VERSION ""

NS_ :

BS_:

BU_: VCU_LE CHUD_LE VKM_LE RCRM_LE VPM_LE EDI_LE V2V_LE TCP_LE CSM_LE UHP_Low_LE TouchPad_LE RSE_LE RSC_LE RSA_LE PDIM_LE OTIM_LE ICS_LE LVMPC_LE LVMNav_LE DVB_T_LE ONSTAR_LE HUD_LE IPC_LE RadioHead_LE CHM_LE Dummy_LE CGM_LE AMP_LE

BO_ 2156298240 High_Volt_Batt_Time_Pwr_Chrg_LE: 8 CGM_LE
 SG_ HTRActvIndOn : 59|1@0+ (1,0) [0|1] ""  VCU_LE,IPC_LE
 SG_ HVBSTLPC_MntOfHr : 53|6@0+ (1,0) [0|63] "Minute"  TCP_LE,ONSTAR_LE,CSM_LE,RadioHead_LE,VCU_LE,IPC_LE
 SG_ HVBSTLPC_HrOfDy : 42|5@0+ (1,0) [0|31] "Hour"  TCP_LE,ONSTAR_LE,CSM_LE,RadioHead_LE,VCU_LE,IPC_LE
 SG_ HVBSTLPC_DyOfWk : 45|3@0+ (1,0) [0|7] ""  TCP_LE,ONSTAR_LE,CSM_LE,RadioHead_LE,VCU_LE,IPC_LE
 SG_ HVBSTHPC_MntOfHr : 35|6@0+ (1,0) [0|63] "Minute"  TCP_LE,ONSTAR_LE,CSM_LE,RadioHead_LE,VCU_LE,IPC_LE
 SG_ HVBSTHPC_HrOfDy : 24|5@0+ (1,0) [0|31] "Hour"  TCP_LE,ONSTAR_LE,CSM_LE,RadioHead_LE,VCU_LE,IPC_LE
 SG_ HVBSTHPC_DyOfWk : 27|3@0+ (1,0) [0|7] ""  TCP_LE,ONSTAR_LE,CSM_LE,RadioHead_LE,VCU_LE,IPC_LE
 SG_ HVBCTLPC_MntOfHr : 17|6@0+ (1,0) [0|63] "Minute"  CSM_LE,RadioHead_LE,VCU_LE,IPC_LE
 SG_ HVBCTLPC_HrOfDy : 22|5@0+ (1,0) [0|31] "Hour"  CSM_LE,RadioHead_LE,VCU_LE,IPC_LE
 SG_ HVBCTLPC_DyOfWk : 9|3@0+ (1,0) [0|7] ""  CSM_LE,RadioHead_LE,VCU_LE,IPC_LE
 SG_ HVBCTHPC_MntOfHr : 15|6@0+ (1,0) [0|63] "Minute"  CSM_LE,RadioHead_LE,VCU_LE,IPC_LE
 SG_ HVBCTHPC_HrOfDy : 4|5@0+ (1,0) [0|31] "Hour"  CSM_LE,RadioHead_LE,VCU_LE,IPC_LE
 SG_ HVBCTHPC_DyOfWk : 7|3@0+ (1,0) [0|7] ""  CSM_LE,RadioHead_LE,VCU_LE,IPC_LE
 SG_ InvldHMIEtrIO : 61|1@0+ (1,0) [0|1] ""  VCU_LE,CSM_LE,RadioHead_LE
 SG_ InsfcntTmTFlChrgIO : 60|1@0+ (1,0) [0|1] ""  VCU_LE,CSM_LE,RadioHead_LE
 SG_ HVBatChrgCrdAlrtReq : 63|2@0+ (1,0) [0|3] ""  CSM_LE,VCU_LE,RadioHead_LE
 SG_ HVCSDTES_NPDTIO : 56|1@0+ (1,0) [0|1] ""  VCU_LE,CSM_LE,RadioHead_LE
 SG_ HVCSDTES_LoPwrCIO : 58|1@0+ (1,0) [0|1] ""  VCU_LE,CSM_LE,RadioHead_LE
 SG_ HVCSDTES_HiPwrCIO : 57|1@0+ (1,0) [0|1] ""  VCU_LE,CSM_LE,RadioHead_LE

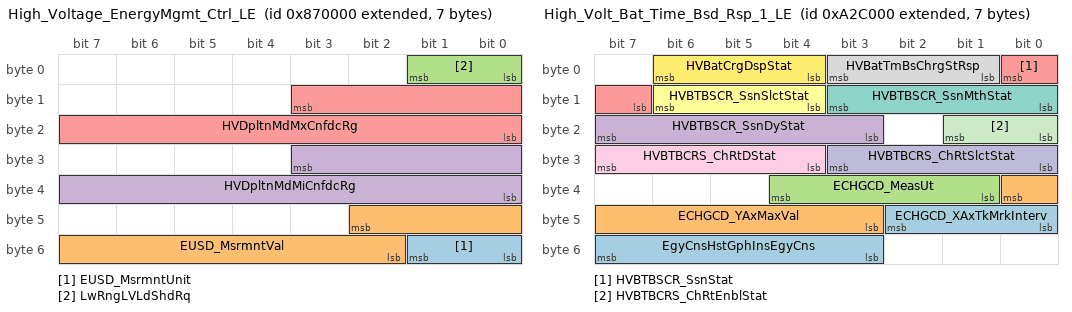
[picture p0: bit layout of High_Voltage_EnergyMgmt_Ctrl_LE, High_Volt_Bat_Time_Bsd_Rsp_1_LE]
BO_ 2156331008 High_Voltage_EnergyMgmt_Ctrl_LE: 7 CGM_LE
 SG_ EUSD_MsrmntUnit : 49|2@0+ (1,0) [0|3] ""  VCU_LE,CSM_LE,RadioHead_LE
 SG_ EUSD_MsrmntVal : 42|9@0+ (1,0) [0|511] ""  VCU_LE,CSM_LE,RadioHead_LE
 SG_ LwRngLVLdShdRq : 1|2@0+ (1,0) [0|3] ""  CSM_LE,VCU_LE,RadioHead_LE
 SG_ HVDpltnMdMiCnfdcRg : 27|12@0+ (0.1,0) [0|409.5] "km"  CSM_LE,RadioHead_LE,VCU_LE,IPC_LE
 SG_ HVDpltnMdMxCnfdcRg : 11|12@0+ (0.1,0) [0|409.5] "km"  CSM_LE,RadioHead_LE,VCU_LE,IPC_LE

BO_ 2158116864 High_Volt_Bat_Time_Bsd_Rsp_LE: 8 CGM_LE
 SG_ HVBatOvrhtdRdIO : 39|1@0+ (1,0) [0|1] ""  VCU_LE,IPC_LE
 SG_ SrvcHghVltBatIndReq : 37|2@0+ (1,0) [0|3] ""  VCU_LE,IPC_LE
 SG_ ChrgStPkInScnActIO : 35|1@0+ (1,0) [0|1] ""  VCU_LE,IPC_LE
 SG_ HVBTBRCR_RtCHSlctTblRwStat : 58|3@0+ (1,0) [0|7] "rows"  CSM_LE,VCU_LE,RadioHead_LE
 SG_ HVBTBRCR_RtChSlctStat : 42|3@0+ (1,0) [0|7] ""  CSM_LE,VCU_LE,RadioHead_LE
 SG_ HVBTBRCR_RtChSlRtStat : 62|4@0+ (1,0) [0|15] ""  CSM_LE,VCU_LE,RadioHead_LE
 SG_ HVBTBRCR_RtChSsnStat : 34|2@0+ (1,0) [0|3] ""  CSM_LE,VCU_LE,RadioHead_LE
 SG_ HVBTBRCR_RtChMHRsp : 32|6@0+ (1,0) [0|63] "min"  CSM_LE,VCU_LE,RadioHead_LE
 SG_ HVBTBRCR_RtChHRsp : 55|5@0+ (1,0) [0|31] "hr"  CSM_LE,VCU_LE,RadioHead_LE
 SG_ HVBTBRCR_RtChDStat : 50|4@0+ (1,0) [0|15] ""  CSM_LE,VCU_LE,RadioHead_LE
 SG_ HVBTBDCRS_DlChSlctStat : 19|4@0+ (1,0) [0|15] ""  CSM_LE,VCU_LE,RadioHead_LE
 SG_ HVBTBDCRS_DlChSsnStat : 31|2@0+ (1,0) [0|3] ""  CSM_LE,VCU_LE,RadioHead_LE
 SG_ HVBTBDCRS_DlChMHRsp : 29|6@0+ (1,0) [0|63] "min"  CSM_LE,VCU_LE,RadioHead_LE
 SG_ HVBTBDCRS_DlChHRsp : 12|5@0+ (1,0) [0|31] "hr"  CSM_LE,VCU_LE,RadioHead_LE
 SG_ HVBTBDCRS_DlChDStat : 23|4@0+ (1,0) [0|15] ""  CSM_LE,VCU_LE,RadioHead_LE
 SG_ HVBatStrtTmDspFrmt : 15|3@0+ (1,0) [0|7] ""  CSM_LE,VCU_LE,RadioHead_LE
 SG_ OBHVBCMinsRmng : 5|6@0+ (1,0) [0|63] ""  CSM_LE,RadioHead_LE,VCU_LE,IPC_LE
 SG_ OBHVBCCompTmDispFrmt : 7|2@0+ (1,0) [0|3] ""  CSM_LE,RadioHead_LE,VCU_LE,IPC_LE

BO_ 2158149632 High_Volt_Bat_Time_Bsd_Rsp_1_LE: 7 CGM_LE
 SG_ ECHGCD_XAxTkMrkInterv : 42|3@0+ (1,0) [0|7] ""  VCU_LE,CSM_LE,RadioHead_LE
 SG_ ECHGCD_YAxMaxVal : 32|6@0+ (4,0) [0|252] ""  VCU_LE,CSM_LE,RadioHead_LE
 SG_ ECHGCD_MeasUt : 36|4@0+ (1,0) [0|15] ""  VCU_LE,CSM_LE,RadioHead_LE
 SG_ HVBTBSCR_SsnDyStat : 23|5@0+ (1,0) [0|31] "day"  VCU_LE,CSM_LE,RadioHead_LE
 SG_ HVBTBSCR_SsnStat : 0|2@0+ (1,0) [0|3] ""  VCU_LE,CSM_LE,RadioHead_LE
 SG_ HVBTBSCR_SsnSlctStat : 14|3@0+ (1,0) [0|7] ""  VCU_LE,CSM_LE,RadioHead_LE
 SG_ HVBTBSCR_SsnMthStat : 11|4@0+ (1,0) [0|15] ""  VCU_LE,CSM_LE,RadioHead_LE
 SG_ HVBatTmBsChrgStRsp : 3|3@0+ (1,0) [0|7] ""  VCU_LE,CSM_LE,RadioHead_LE
 SG_ HVBTBCRS_ChRtDStat : 31|4@0+ (1,0) [0|15] ""  VCU_LE,CSM_LE,RadioHead_LE
 SG_ HVBTBCRS_ChRtSlctStat : 27|4@0+ (1,0) [0|15] ""  VCU_LE,CSM_LE,RadioHead_LE
 SG_ HVBTBCRS_ChRtEnblStat : 17|2@0+ (1,0) [0|3] ""  VCU_LE,CSM_LE,RadioHead_LE
 SG_ HVBatCrgDspStat : 6|3@0+ (1,0) [0|7] ""  CSM_LE,VCU_LE,RadioHead_LE
 SG_ EgyCnsHstGphInsEgyCns : 55|5@0+ (1,0) [0|31] ""  VCU_LE,CSM_LE,RadioHead_LE

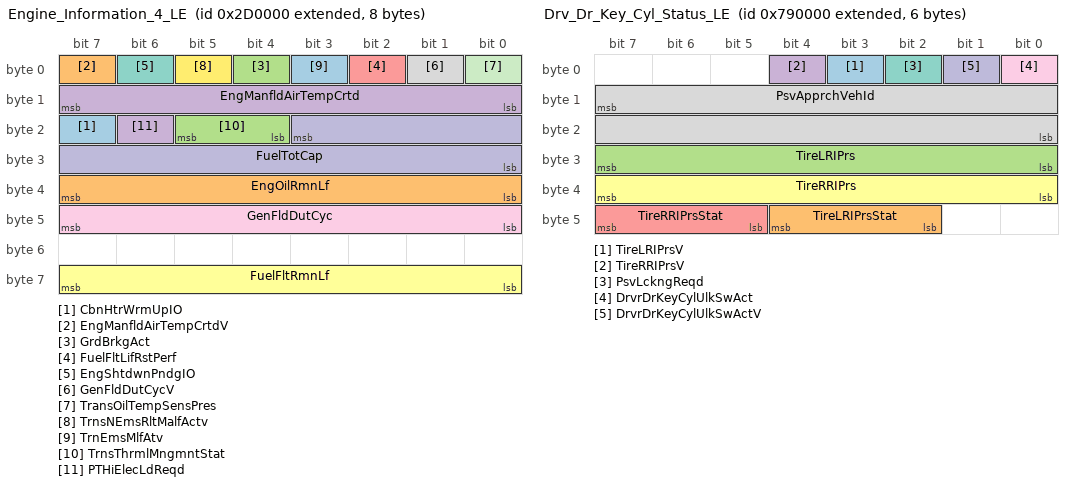
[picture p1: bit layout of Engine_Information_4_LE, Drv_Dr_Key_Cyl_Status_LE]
BO_ 2150432768 Engine_Information_4_LE: 8 CGM_LE
 SG_ CbnHtrWrmUpIO : 23|1@0+ (1,0) [0|1] ""  VCU_LE,IPC_LE
 SG_ EngManfldAirTempCrtdV : 7|1@0+ (1,0) [0|1] ""  Dummy_LE
 SG_ GrdBrkgAct : 4|1@0+ (1,0) [0|1] ""  CSM_LE,RadioHead_LE,VCU_LE,IPC_LE
 SG_ EngManfldAirTempCrtd : 15|8@0+ (1,-40) [-40|215] "deg C"  Dummy_LE
 SG_ FuelFltLifRstPerf : 2|1@0+ (1,0) [0|1] ""  CSM_LE,RadioHead_LE,VCU_LE,IPC_LE
 SG_ FuelFltRmnLf : 63|8@0+ (0.392157,0) [0|100.000035] "%"  CSM_LE,RadioHead_LE,VCU_LE,IPC_LE
 SG_ EngShtdwnPndgIO : 6|1@0+ (1,0) [0|1] ""  CSM_LE,RadioHead_LE,VCU_LE,IPC_LE
 SG_ GenFldDutCycV : 1|1@0+ (1,0) [0|1] ""  CSM_LE,VCU_LE,RadioHead_LE
 SG_ GenFldDutCyc : 47|8@0+ (0.392157,0) [0|100.000035] "%"  CSM_LE,VCU_LE,RadioHead_LE
 SG_ FuelTotCap : 19|12@0+ (0.125,0) [0|511.875] "liters"  TCP_LE,ONSTAR_LE,CSM_LE,RadioHead_LE,VCU_LE,IPC_LE
 SG_ TransOilTempSensPres : 0|1@0+ (1,0) [0|1] ""  CSM_LE,RadioHead_LE,VCU_LE,IPC_LE
 SG_ TrnsNEmsRltMalfActv : 5|1@0+ (1,0) [0|1] ""  CSM_LE,RadioHead_LE,VCU_LE,IPC_LE
 SG_ TrnEmsMlfAtv : 3|1@0+ (1,0) [0|1] ""  CSM_LE,RadioHead_LE,VCU_LE,IPC_LE
 SG_ EngOilRmnLf : 39|8@0+ (0.392157,0) [0|100.000035] "%"  CSM_LE,TCP_LE,ONSTAR_LE,RadioHead_LE,VCU_LE,IPC_LE
 SG_ TrnsThrmlMngmntStat : 21|2@0+ (1,0) [0|3] ""  CSM_LE,TCP_LE,ONSTAR_LE,RadioHead_LE,VCU_LE,IPC_LE
 SG_ PTHiElecLdReqd : 22|1@0+ (1,0) [0|1] ""  CSM_LE,RadioHead_LE,VCU_LE,IPC_LE

BO_ 2155413504 Drv_Dr_Key_Cyl_Status_LE: 6 CGM_LE
 SG_ TireLRIPrsV : 3|1@0+ (1,0) [0|1] ""  V2V_LE,TCP_LE,ONSTAR_LE,VCU_LE,IPC_LE
 SG_ TireLRIPrsStat : 44|3@0+ (1,0) [0|7] ""  TCP_LE,ONSTAR_LE,VCU_LE,IPC_LE
 SG_ TireLRIPrs : 31|8@0+ (4,0) [0|1020] "kPaG"  V2V_LE,TCP_LE,ONSTAR_LE,VCU_LE,IPC_LE
 SG_ TireRRIPrsV : 4|1@0+ (1,0) [0|1] ""  V2V_LE,TCP_LE,ONSTAR_LE,VCU_LE,IPC_LE
 SG_ TireRRIPrsStat : 47|3@0+ (1,0) [0|7] ""  TCP_LE,ONSTAR_LE,VCU_LE,IPC_LE
 SG_ TireRRIPrs : 39|8@0+ (4,0) [0|1020] "kPaG"  V2V_LE,TCP_LE,ONSTAR_LE,VCU_LE,IPC_LE
 SG_ PsvLckngReqd : 2|1@0+ (1,0) [0|1] ""  Dummy_LE
 SG_ PsvApprchVehId : 15|16@0+ (1,0) [0|65535] ""  Dummy_LE
 SG_ DrvrDrKeyCylUlkSwAct : 0|1@0+ (1,0) [0|1] ""  CSM_LE,VCU_LE,RadioHead_LE
 SG_ DrvrDrKeyCylUlkSwActV : 1|1@0+ (1,0) [0|1] ""  CSM_LE,VCU_LE,RadioHead_LE

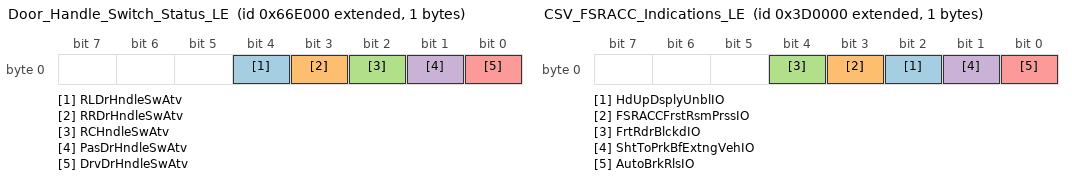
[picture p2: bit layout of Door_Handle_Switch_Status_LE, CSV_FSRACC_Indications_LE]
BO_ 2154225664 Door_Handle_Switch_Status_LE: 1 CGM_LE
 SG_ RLDrHndleSwAtv : 4|1@0+ (1,0) [0|1] ""  VKM_LE,CSM_LE,VCU_LE,RadioHead_LE
 SG_ RRDrHndleSwAtv : 3|1@0+ (1,0) [0|1] ""  VKM_LE,CSM_LE,VCU_LE,RadioHead_LE
 SG_ RCHndleSwAtv : 2|1@0+ (1,0) [0|1] ""  VKM_LE,CSM_LE,VCU_LE,RadioHead_LE
 SG_ PasDrHndleSwAtv : 1|1@0+ (1,0) [0|1] ""  VKM_LE,CSM_LE,VCU_LE,RadioHead_LE
 SG_ DrvDrHndleSwAtv : 0|1@0+ (1,0) [0|1] ""  VKM_LE,CSM_LE,VCU_LE,RadioHead_LE

BO_ 2151481344 CSV_FSRACC_Indications_LE: 1 CGM_LE
 SG_ HdUpDsplyUnblIO : 2|1@0+ (1,0) [0|1] ""  VCU_LE,IPC_LE
 SG_ FSRACCFrstRsmPrssIO : 3|1@0+ (1,0) [0|1] ""  VCU_LE,IPC_LE
 SG_ FrtRdrBlckdIO : 4|1@0+ (1,0) [0|1] ""  CSM_LE,RadioHead_LE,VCU_LE,IPC_LE
 SG_ ShtToPrkBfExtngVehIO : 1|1@0+ (1,0) [0|1] ""  VCU_LE,IPC_LE
 SG_ AutoBrkRlsIO : 0|1@0+ (1,0) [0|1] ""  VCU_LE,IPC_LE

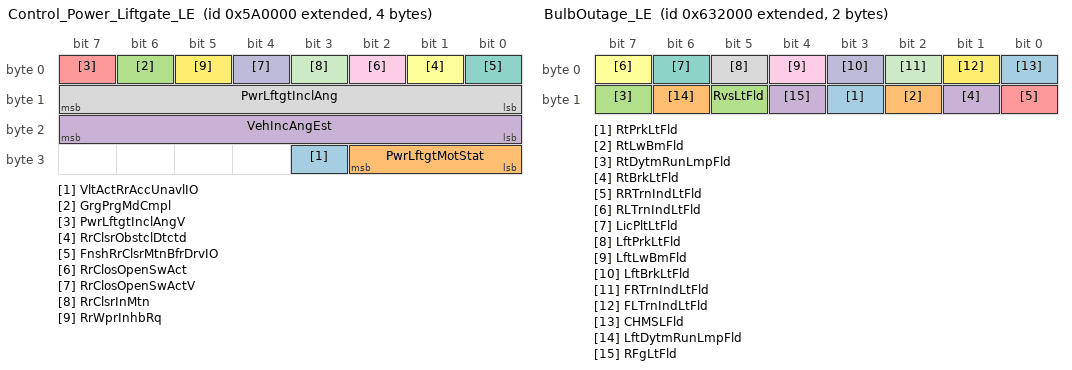
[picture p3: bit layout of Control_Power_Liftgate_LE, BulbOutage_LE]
BO_ 2153381888 Control_Power_Liftgate_LE: 4 CGM_LE
 SG_ VltActRrAccUnavlIO : 27|1@0+ (1,0) [0|1] ""  VCU_LE,IPC_LE
 SG_ PwrLftgtMotStat : 26|3@0+ (1,0) [0|7] ""  CSM_LE,IPC_LE,VCU_LE,RadioHead_LE
 SG_ GrgPrgMdCmpl : 6|1@0+ (1,0) [0|1] ""  CSM_LE,VCU_LE,RadioHead_LE
 SG_ VehIncAngEst : 23|8@0+ (1,0) [0|255] "deg"  CSM_LE,VCU_LE,RadioHead_LE
 SG_ PwrLftgtInclAngV : 7|1@0+ (1,0) [0|1] ""  CSM_LE,VCU_LE,RadioHead_LE
 SG_ RrClsrObstclDtctd : 1|1@0+ (1,0) [0|1] ""  CSM_LE,VCU_LE,RadioHead_LE
 SG_ FnshRrClsrMtnBfrDrvIO : 0|1@0+ (1,0) [0|1] ""  CSM_LE,RadioHead_LE,VCU_LE,IPC_LE
 SG_ PwrLftgtInclAng : 15|8@0+ (1,0) [0|255] ""  CSM_LE,VCU_LE,RadioHead_LE
 SG_ RrClosOpenSwAct : 2|1@0+ (1,0) [0|1] ""  VKM_LE,CSM_LE,RadioHead_LE,VCU_LE,IPC_LE
 SG_ RrClosOpenSwActV : 4|1@0+ (1,0) [0|1] ""  CSM_LE,RadioHead_LE,VCU_LE,IPC_LE
 SG_ RrClsrInMtn : 3|1@0+ (1,0) [0|1] ""  CSM_LE,VCU_LE,RadioHead_LE
 SG_ RrWprInhbRq : 5|1@0+ (1,0) [0|1] ""  CSM_LE,VCU_LE,RadioHead_LE

BO_ 2153979904 BulbOutage_LE: 2 CGM_LE
 SG_ RtPrkLtFld : 11|1@0+ (1,0) [0|1] ""  CSM_LE,TCP_LE,ONSTAR_LE,RadioHead_LE,VCU_LE,IPC_LE
 SG_ RtLwBmFld : 10|1@0+ (1,0) [0|1] ""  CSM_LE,TCP_LE,ONSTAR_LE,RadioHead_LE,VCU_LE,IPC_LE
 SG_ RtDytmRunLmpFld : 15|1@0+ (1,0) [0|1] ""  CSM_LE,RadioHead_LE,VCU_LE,IPC_LE
 SG_ RtBrkLtFld : 9|1@0+ (1,0) [0|1] ""  CSM_LE,TCP_LE,ONSTAR_LE,RadioHead_LE,VCU_LE,IPC_LE
 SG_ RRTrnIndLtFld : 8|1@0+ (1,0) [0|1] ""  CSM_LE,TCP_LE,ONSTAR_LE,RadioHead_LE,VCU_LE,IPC_LE
 SG_ RLTrnIndLtFld : 7|1@0+ (1,0) [0|1] ""  CSM_LE,TCP_LE,ONSTAR_LE,RadioHead_LE,VCU_LE,IPC_LE
 SG_ LicPltLtFld : 6|1@0+ (1,0) [0|1] ""  CSM_LE,TCP_LE,ONSTAR_LE,RadioHead_LE,VCU_LE,IPC_LE
 SG_ LftPrkLtFld : 5|1@0+ (1,0) [0|1] ""  CSM_LE,TCP_LE,ONSTAR_LE,RadioHead_LE,VCU_LE,IPC_LE
 SG_ LftLwBmFld : 4|1@0+ (1,0) [0|1] ""  CSM_LE,TCP_LE,ONSTAR_LE,RadioHead_LE,VCU_LE,IPC_LE
 SG_ LftBrkLtFld : 3|1@0+ (1,0) [0|1] ""  CSM_LE,TCP_LE,ONSTAR_LE,RadioHead_LE,VCU_LE,IPC_LE
 SG_ FRTrnIndLtFld : 2|1@0+ (1,0) [0|1] ""  CSM_LE,TCP_LE,ONSTAR_LE,RadioHead_LE,VCU_LE,IPC_LE
 SG_ FLTrnIndLtFld : 1|1@0+ (1,0) [0|1] ""  CSM_LE,TCP_LE,ONSTAR_LE,RadioHead_LE,VCU_LE,IPC_LE
 SG_ CHMSLFld : 0|1@0+ (1,0) [0|1] ""  CSM_LE,TCP_LE,ONSTAR_LE,RadioHead_LE,VCU_LE,IPC_LE
 SG_ LftDytmRunLmpFld : 14|1@0+ (1,0) [0|1] ""  CSM_LE,RadioHead_LE,VCU_LE,IPC_LE
 SG_ RvsLtFld : 13|1@0+ (1,0) [0|1] ""  CSM_LE,TCP_LE,ONSTAR_LE,RadioHead_LE,VCU_LE,IPC_LE
 SG_ RFgLtFld : 12|1@0+ (1,0) [0|1] ""  CSM_LE,TCP_LE,ONSTAR_LE,RadioHead_LE,VCU_LE,IPC_LE

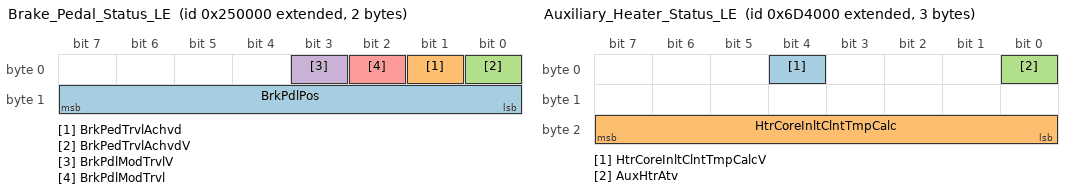
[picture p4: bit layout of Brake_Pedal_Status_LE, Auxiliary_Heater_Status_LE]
BO_ 2149908480 Brake_Pedal_Status_LE: 2 CGM_LE
 SG_ BrkPdlPos : 15|8@0+ (0.392157,0) [0|100.000035] "% full"  CSM_LE,RadioHead_LE,VCU_LE,IPC_LE
 SG_ BrkPedTrvlAchvd : 1|1@0+ (1,0) [0|1] ""  CSM_LE,RadioHead_LE,VCU_LE,IPC_LE
 SG_ BrkPedTrvlAchvdV : 0|1@0+ (1,0) [0|1] ""  CSM_LE,RadioHead_LE,VCU_LE,IPC_LE
 SG_ BrkPdlModTrvlV : 3|1@0+ (1,0) [0|1] ""  CSM_LE,VCU_LE,RadioHead_LE
 SG_ BrkPdlModTrvl : 2|1@0+ (1,0) [0|1] ""  CSM_LE,VCU_LE,RadioHead_LE

BO_ 2154643456 Auxiliary_Heater_Status_LE: 3 CGM_LE
 SG_ HtrCoreInltClntTmpCalcV : 4|1@0+ (1,0) [0|1] ""  CSM_LE,VCU_LE,RadioHead_LE
 SG_ HtrCoreInltClntTmpCalc : 23|8@0+ (1,-40) [-40|215] "deg C"  CSM_LE,VCU_LE,RadioHead_LE
 SG_ AuxHtrAtv : 0|1@0+ (1,0) [0|1] ""  CSM_LE,VCU_LE,RadioHead_LE

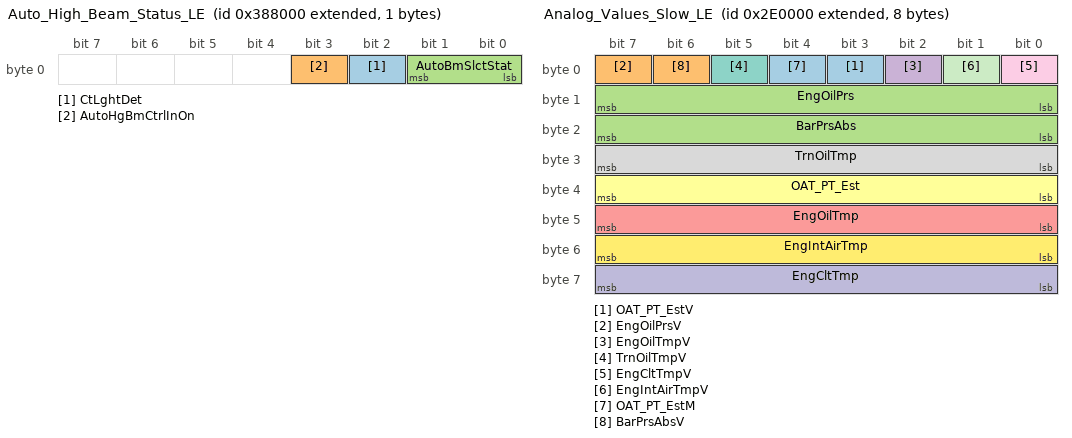
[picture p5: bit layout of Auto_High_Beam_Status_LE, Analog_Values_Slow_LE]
BO_ 2151186432 Auto_High_Beam_Status_LE: 1 CGM_LE
 SG_ CtLghtDet : 2|1@0+ (1,0) [0|1] ""  CSM_LE,VCU_LE,RadioHead_LE
 SG_ AutoHgBmCtrlInOn : 3|1@0+ (1,0) [0|1] ""  CSM_LE,RadioHead_LE,VCU_LE,IPC_LE
 SG_ AutoBmSlctStat : 1|2@0+ (1,0) [0|3] ""  CSM_LE,VCU_LE,RadioHead_LE

BO_ 2150498304 Analog_Values_Slow_LE: 8 CGM_LE
 SG_ OAT_PT_EstV : 3|1@0+ (1,0) [0|1] ""  CSM_LE,VCU_LE,RadioHead_LE
 SG_ EngOilPrsV : 7|1@0+ (1,0) [0|1] ""  CSM_LE,TCP_LE,ONSTAR_LE,RadioHead_LE,VCU_LE,IPC_LE
 SG_ EngOilPrs : 15|8@0+ (4,0) [0|1020] "kPa"  CSM_LE,TCP_LE,ONSTAR_LE,RadioHead_LE,VCU_LE,IPC_LE
 SG_ EngOilTmpV : 2|1@0+ (1,0) [0|1] ""  CSM_LE,RadioHead_LE,VCU_LE,IPC_LE
 SG_ EngOilTmp : 47|8@0+ (1,-40) [-40|215] "deg C"  CSM_LE,RadioHead_LE,VCU_LE,IPC_LE
 SG_ OAT_PT_Est : 39|8@0+ (0.5,-40) [-40|87.5] "deg C"  CSM_LE,VCU_LE,RadioHead_LE
 SG_ TrnOilTmpV : 5|1@0+ (1,0) [0|1] ""  CSM_LE,RadioHead_LE,VCU_LE,IPC_LE
 SG_ TrnOilTmp : 31|8@0+ (1,-40) [-40|215] "deg C"  CSM_LE,RadioHead_LE,VCU_LE,IPC_LE
 SG_ EngCltTmpV : 0|1@0+ (1,0) [0|1] ""  CSM_LE,RadioHead_LE,VCU_LE,IPC_LE
 SG_ EngCltTmp : 63|8@0+ (1,-40) [-40|215] "deg C"  CSM_LE,RadioHead_LE,VCU_LE,IPC_LE
 SG_ EngIntAirTmpV : 1|1@0+ (1,0) [0|1] ""  CSM_LE,VCU_LE,RadioHead_LE
 SG_ EngIntAirTmp : 55|8@0+ (1,-40) [-40|215] "deg C"  CSM_LE,VCU_LE,RadioHead_LE
 SG_ OAT_PT_EstM : 4|1@0+ (1,0) [0|1] ""  CSM_LE,VCU_LE,RadioHead_LE
 SG_ BarPrsAbsV : 6|1@0+ (1,0) [0|1] ""  CSM_LE,IPC_LE,VCU_LE,RadioHead_LE
 SG_ BarPrsAbs : 23|8@0+ (0.5,0) [0|127.5] "kPa"  CSM_LE,IPC_LE,VCU_LE,RadioHead_LE

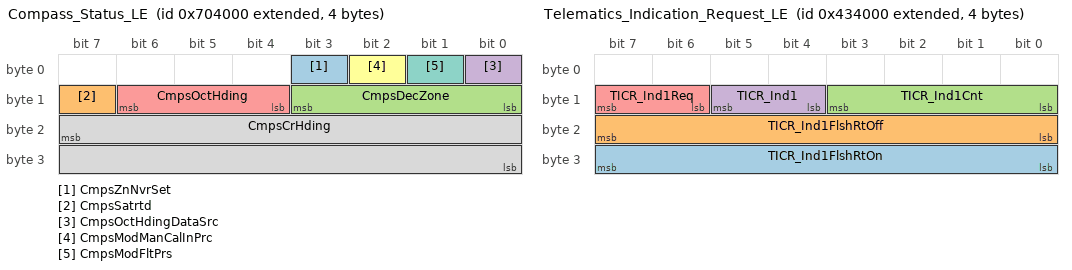
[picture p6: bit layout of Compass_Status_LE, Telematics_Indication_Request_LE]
BO_ 2154840064 Compass_Status_LE: 4 ONSTAR_LE
 SG_ CmpsZnNvrSet : 3|1@0+ (1,0) [0|1] ""  CSM_LE,CGM_LE,RadioHead_LE,VCU_LE,IPC_LE
 SG_ CmpsSatrtd : 15|1@0+ (1,0) [0|1] ""  CSM_LE,CGM_LE,RadioHead_LE,VCU_LE,IPC_LE
 SG_ CmpsDecZone : 11|4@0+ (1,0) [0|15] ""  CSM_LE,CGM_LE,RadioHead_LE,VCU_LE,IPC_LE
 SG_ CmpsOctHdingDataSrc : 0|1@0+ (1,0) [0|1] ""  CSM_LE,CGM_LE,RadioHead_LE,VCU_LE,IPC_LE
 SG_ CmpsOctHding : 14|3@0+ (1,0) [0|7] ""  CSM_LE,CGM_LE,RadioHead_LE,VCU_LE,IPC_LE
 SG_ CmpsModManCalInPrc : 2|1@0+ (1,0) [0|1] ""  CSM_LE,CGM_LE,RadioHead_LE,VCU_LE,IPC_LE
 SG_ CmpsModFltPrs : 1|1@0+ (1,0) [0|1] ""  CSM_LE,CGM_LE,RadioHead_LE,VCU_LE,IPC_LE
 SG_ CmpsCrHding : 23|16@0+ (0.0054932,0) [0|359.996862] "deg"  CSM_LE,CGM_LE,RadioHead_LE,VCU_LE,IPC_LE

BO_ 2151890944 Telematics_Indication_Request_LE: 4 ONSTAR_LE
 SG_ TICR_Ind1FlshRtOn : 31|8@0+ (10,0) [0|2550] "ms"  CGM_LE
 SG_ TICR_Ind1FlshRtOff : 23|8@0+ (10,0) [0|2550] "ms"  CGM_LE
 SG_ TICR_Ind1Cnt : 11|4@0+ (1,0) [0|15] ""  CGM_LE
 SG_ TICR_Ind1 : 13|2@0+ (1,0) [0|3] ""  CGM_LE
 SG_ TICR_Ind1Req : 15|2@0+ (1,0) [0|3] ""  CGM_LE

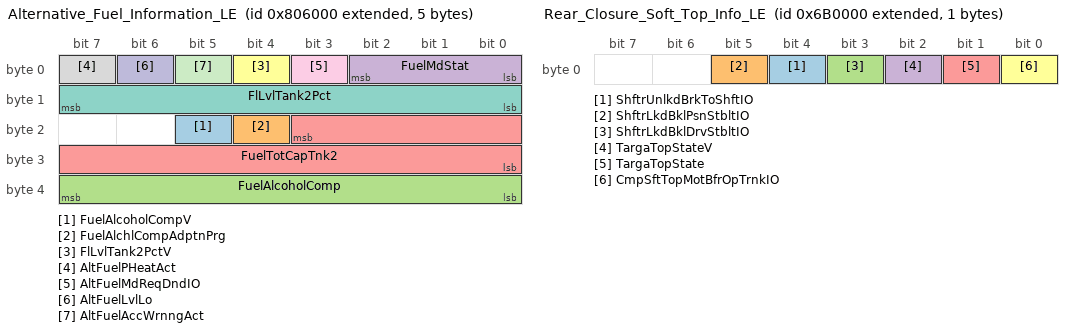
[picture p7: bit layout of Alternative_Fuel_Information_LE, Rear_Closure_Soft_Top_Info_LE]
BO_ 2155896832 Alternative_Fuel_Information_LE: 5 CGM_LE
 SG_ FuelAlcoholCompV : 21|1@0+ (1,0) [0|1] ""  CSM_LE,RadioHead_LE,VCU_LE,IPC_LE
 SG_ FuelAlchlCompAdptnPrg : 20|1@0+ (1,0) [0|1] ""  CSM_LE,RadioHead_LE,VCU_LE,IPC_LE
 SG_ FuelAlcoholComp : 39|8@0+ (0.392157,0) [0|100.000035] "%"  CSM_LE,RadioHead_LE,VCU_LE,IPC_LE
 SG_ FuelMdStat : 2|3@0+ (1,0) [0|7] ""  CSM_LE,RadioHead_LE,VCU_LE,IPC_LE
 SG_ FuelTotCapTnk2 : 19|12@0+ (0.125,0) [0|511.875] "liters"  CSM_LE,RadioHead_LE,VCU_LE,IPC_LE
 SG_ FlLvlTank2PctV : 4|1@0+ (1,0) [0|1] ""  CSM_LE,RadioHead_LE,VCU_LE,IPC_LE
 SG_ FlLvlTank2Pct : 15|8@0+ (0.392157,0) [0|100.000035] "%"  CSM_LE,RadioHead_LE,VCU_LE,IPC_LE
 SG_ AltFuelPHeatAct : 7|1@0+ (1,0) [0|1] ""  CSM_LE,RadioHead_LE,VCU_LE,IPC_LE
 SG_ AltFuelMdReqDndIO : 3|1@0+ (1,0) [0|1] ""  CSM_LE,RadioHead_LE,VCU_LE,IPC_LE
 SG_ AltFuelLvlLo : 6|1@0+ (1,0) [0|1] ""  CSM_LE,RadioHead_LE,VCU_LE,IPC_LE
 SG_ AltFuelAccWrnngAct : 5|1@0+ (1,0) [0|1] ""  CSM_LE,RadioHead_LE,VCU_LE,IPC_LE

BO_ 2154496000 Rear_Closure_Soft_Top_Info_LE: 1 CGM_LE
 SG_ ShftrUnlkdBrkToShftIO : 4|1@0+ (1,0) [0|1] ""  VCU_LE,IPC_LE
 SG_ ShftrLkdBklPsnStbltIO : 5|1@0+ (1,0) [0|1] ""  VCU_LE,IPC_LE
 SG_ ShftrLkdBklDrvStbltIO : 3|1@0+ (1,0) [0|1] ""  VCU_LE,IPC_LE
 SG_ TargaTopStateV : 2|1@0+ (1,0) [0|1] ""  AMP_LE,CSM_LE,VCU_LE,RadioHead_LE
 SG_ TargaTopState : 1|1@0+ (1,0) [0|1] ""  AMP_LE,CSM_LE,VCU_LE,RadioHead_LE
 SG_ CmpSftTopMotBfrOpTrnkIO : 0|1@0+ (1,0) [0|1] ""  CSM_LE,VCU_LE,IPC_LE

BO_ 2154471424 Rear_Closure_Ajr_Switch_Stats_LE: 1 CGM_LE
 SG_ RrClsrSnwLdIO : 1|1@0+ (1,0) [0|1] ""  CSM_LE,RadioHead_LE,VCU_LE,IPC_LE
 SG_ RrClosAjarSwAct : 0|1@0+ (1,0) [0|1] ""  RCRM_LE,AMP_LE,VPM_LE,CSM_LE,RadioHead_LE,VCU_LE,IPC_LE

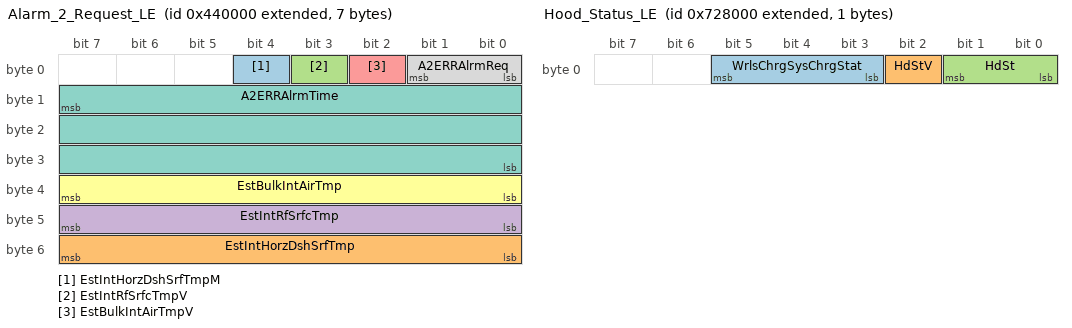
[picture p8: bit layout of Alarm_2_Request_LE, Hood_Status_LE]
BO_ 2151940096 Alarm_2_Request_LE: 7 CGM_LE
 SG_ EstIntHorzDshSrfTmpM : 4|1@0+ (1,0) [0|1] ""  Dummy_LE
 SG_ EstIntHorzDshSrfTmp : 55|8@0+ (1,-40) [-40|215] "deg C"  Dummy_LE
 SG_ EstIntRfSrfcTmpV : 3|1@0+ (1,0) [0|1] ""  VCU_LE,CSM_LE,RadioHead_LE
 SG_ EstIntRfSrfcTmp : 47|8@0+ (0.5,-40) [-40|87.5] "deg C"  VCU_LE,CSM_LE,RadioHead_LE
 SG_ EstBulkIntAirTmpV : 2|1@0+ (1,0) [0|1] ""  VCU_LE,CSM_LE,RadioHead_LE
 SG_ EstBulkIntAirTmp : 39|8@0+ (0.5,-40) [-40|87.5] "deg C"  VCU_LE,CSM_LE,RadioHead_LE
 SG_ A2ERRAlrmTime : 15|24@0+ (1,0) [0|16777215] "min"  Dummy_LE
 SG_ A2ERRAlrmReq : 1|2@0+ (1,0) [0|3] ""  Dummy_LE

BO_ 2154987520 Hood_Status_LE: 1 CGM_LE
 SG_ WrlsChrgSysChrgStat : 5|3@0+ (1,0) [0|7] ""  VCU_LE,CSM_LE,RadioHead_LE
 SG_ HdStV : 2|1@0+ (1,0) [0|1] ""  V2V_LE,CSM_LE,RadioHead_LE,VCU_LE,IPC_LE
 SG_ HdSt : 1|2@0+ (1,0) [0|3] ""  VKM_LE,CSM_LE,VPM_LE,V2V_LE,RadioHead_LE,VCU_LE,IPC_LE

BO_ 2156281856 High_Volt_Bat_Time_Bsd_Req_1_LE: 7 RadioHead_LE
 SG_ LftmEffDtRstRqd : 18|1@0+ (1,0) [0|1] ""  CGM_LE
 SG_ HTRCsStReq : 37|3@0+ (1,0) [0|7] ""  CGM_LE
 SG_ RtBsChrgCmplnTmPrfReq : 34|2@0+ (1,0) [0|3] ""  CGM_LE
 SG_ TONPDTR_StTmpOvrAtv : 32|2@0+ (1,0) [0|3] ""  CGM_LE
 SG_ TONPDTR_MntOfHr : 53|6@0+ (1,0) [0|63] "Minute"  CGM_LE
 SG_ TONPDTR_HrOfDy : 42|5@0+ (1,0) [0|31] "Hour"  CGM_LE
 SG_ TONPDTR_DyOfWk : 46|4@0+ (1,0) [0|15] ""  CGM_LE
 SG_ StTODChrgTmpOvrd : 7|1@0+ (1,0) [0|1] ""  CGM_LE
 SG_ HVBTBSCSR_SsnStReq : 0|2@0+ (1,0) [0|3] ""  CGM_LE
 SG_ HVBTBSCSR_SsnSlStReq : 14|3@0+ (1,0) [0|7] ""  CGM_LE
 SG_ HVBTBSCSR_SsnMthStReq : 11|4@0+ (1,0) [0|15] ""  CGM_LE
 SG_ HVBTBSCSR_SsnDayStReq : 23|5@0+ (1,0) [0|31] "day"  CGM_LE
 SG_ HVBTBCRSR_ChRtSlStReq : 27|4@0+ (1,0) [0|15] ""  CGM_LE
 SG_ HVBTBCRSR_ChRtEnblStReq : 17|2@0+ (1,0) [0|3] ""  CGM_LE
 SG_ HVBTBCRSR_ChRtDStReq : 31|4@0+ (1,0) [0|15] ""  CGM_LE
 SG_ HVBatTmBsChrgMdReq : 3|3@0+ (1,0) [0|7] ""  CGM_LE
 SG_ HVChgSyChgLvlPrfSt : 6|3@0+ (1,0) [0|7] ""  CGM_LE
 SG_ TODCTmpImdtOvrdReq : 39|2@0+ (1,0) [0|3] ""  CGM_LE

BO_ 2156314624 High_Volt_Time_Based_Chrg_LE: 8 CGM_LE
 SG_ HVChrgSysSplyFltIO : 23|1@0+ (1,0) [0|1] ""  VCU_LE,IPC_LE
 SG_ OffBrdCSFltDtctd : 6|1@0+ (1,0) [0|1] ""  CSM_LE,ONSTAR_LE,VCU_LE,IPC_LE
 SG_ OBVhCsACChgRqBnVs : 7|1@0+ (1,0) [0|1] ""  VCU_LE,CSM_LE,RadioHead_LE
 SG_ TODCNPDT_Min : 13|6@0+ (1,0) [0|63] "Minute"  VCU_LE,CSM_LE,RadioHead_LE
 SG_ TODCNPDT_Hr : 2|5@0+ (1,0) [0|31] "Hour"  VCU_LE,CSM_LE,RadioHead_LE
 SG_ TODCNPDT_DyOfWk : 5|3@0+ (1,0) [0|7] ""  VCU_LE,CSM_LE,RadioHead_LE
 SG_ HVBatBlkSOC : 63|8@0+ (0.392157,0) [0|100.000035] "%"  CSM_LE,RadioHead_LE,VCU_LE,IPC_LE
 SG_ TODCOpMd : 22|3@0+ (1,0) [0|7] ""  CSM_LE,TCP_LE,ONSTAR_LE,VCU_LE,RadioHead_LE
 SG_ TODCDMPTO_TpOvR : 51|4@0+ (1,0) [0|15] ""  TCP_LE,ONSTAR_LE,CSM_LE,RadioHead_LE,VCU_LE,IPC_LE
 SG_ TODCDMPTO_CmPgR : 52|1@0+ (1,0) [0|1] ""  TCP_LE,ONSTAR_LE,CSM_LE,RadioHead_LE,VCU_LE,IPC_LE
 SG_ HVChrgSysStNot : 55|3@0+ (1,0) [0|7] ""  CSM_LE,TCP_LE,ONSTAR_LE,VCU_LE,RadioHead_LE
 SG_ HVChrgAbrtRsn : 19|3@0+ (1,0) [0|7] ""  CSM_LE,TCP_LE,ONSTAR_LE,VCU_LE,RadioHead_LE
 SG_ HVCSCLPD_UsrIntTyp : 16|2@0+ (1,0) [0|3] ""  CSM_LE,VCU_LE,RadioHead_LE
 SG_ HVCSCLPD_RdCrntLv3 : 44|5@0+ (1,0) [0|31] "A"  CSM_LE,VCU_LE,RadioHead_LE
 SG_ HVCSCLPD_RdCrntLv2 : 33|5@0+ (1,0) [0|31] "A"  CSM_LE,VCU_LE,RadioHead_LE
 SG_ HVCSCLPD_RdCrntLv1 : 38|5@0+ (1,0) [0|31] "A"  CSM_LE,VCU_LE,RadioHead_LE
 SG_ HVCSCLPD_NrmChrgC : 27|5@0+ (1,0) [0|31] "A"  CSM_LE,VCU_LE,RadioHead_LE
 SG_ HVCSCLPD_ChgLvlPfS : 30|3@0+ (1,0) [0|7] ""  CSM_LE,VCU_LE,RadioHead_LE

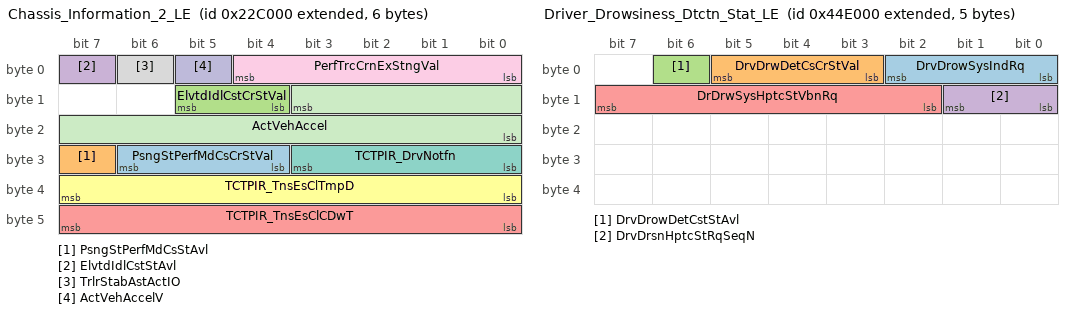
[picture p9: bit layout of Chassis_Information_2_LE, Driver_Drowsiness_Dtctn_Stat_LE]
BO_ 2149761024 Chassis_Information_2_LE: 6 CGM_LE
 SG_ PsngStPerfMdCsCrStVal : 30|3@0+ (1,0) [0|7] ""  VCU_LE,CSM_LE,RadioHead_LE
 SG_ PsngStPerfMdCsStAvl : 31|1@0+ (1,0) [0|1] ""  VCU_LE,CSM_LE,RadioHead_LE
 SG_ ElvtdIdlCstCrStVal : 13|2@0+ (1,0) [0|3] ""  CSM_LE,RadioHead_LE,VCU_LE,IPC_LE
 SG_ ElvtdIdlCstStAvl : 7|1@0+ (1,0) [0|1] ""  VCU_LE,CSM_LE,RadioHead_LE
 SG_ TCTPIR_TnsEsClCDwT : 47|8@0+ (0.392157,0) [0|100.000035] "%"  VCU_LE,IPC_LE
 SG_ TCTPIR_TnsEsClTmpD : 39|8@0+ (0.392157,0) [0|100.000035] "%"  VCU_LE,IPC_LE
 SG_ TCTPIR_DrvNotfn : 27|4@0+ (1,0) [0|15] ""  VCU_LE,IPC_LE
 SG_ TrlrStabAstActIO : 6|1@0+ (1,0) [0|1] ""  VCU_LE,IPC_LE
 SG_ PerfTrcCrnExStngVal : 4|5@0+ (1,0) [0|31] ""  VCU_LE,IPC_LE
 SG_ ActVehAccelV : 5|1@0+ (1,0) [0|1] ""  VCU_LE,IPC_LE
 SG_ ActVehAccel : 11|12@0- (0.01,0) [-20.48|20.47] "m/s^2"  VCU_LE,IPC_LE

BO_ 2151997440 Driver_Drowsiness_Dtctn_Stat_LE: 5 CGM_LE
 SG_ DrvDrowSysIndRq : 2|3@0+ (1,0) [0|7] ""  VCU_LE,IPC_LE
 SG_ DrvDrwDetCsCrStVal : 5|3@0+ (1,0) [0|7] ""  VCU_LE,CSM_LE,RadioHead_LE
 SG_ DrvDrowDetCstStAvl : 6|1@0+ (1,0) [0|1] ""  VCU_LE,CSM_LE,RadioHead_LE
 SG_ DrvDrsnHptcStRqSeqN : 9|2@0+ (1,0) [0|3] ""  Dummy_LE
 SG_ DrDrwSysHptcStVbnRq : 15|6@0+ (1,0) [0|63] ""  Dummy_LE

BO_ 2151948288 Driver_Drow_Det_Cst_Rqst_LE: 1 RadioHead_LE
 SG_ RunBrdOpMdCstStReq : 7|3@0+ (1,0) [0|7] ""  CGM_LE
 SG_ DrvDrowDetCstStRq : 2|3@0+ (1,0) [0|7] ""  CGM_LE

BO_ 2152128512 Performance_Mode_Cust_Setings_LE: 4 CGM_LE
 SG_ PSPMCA_PsngStPrfMd6Avl : 16|1@0+ (1,0) [0|1] ""  VCU_LE,CSM_LE,RadioHead_LE
 SG_ PSPMCA_PsngStPrfMd5Avl : 17|1@0+ (1,0) [0|1] ""  VCU_LE,CSM_LE,RadioHead_LE
 SG_ PSPMCA_PsngStPrfMd4Avl : 18|1@0+ (1,0) [0|1] ""  VCU_LE,CSM_LE,RadioHead_LE
 SG_ PSPMCA_PsngStPrfMd3Avl : 19|1@0+ (1,0) [0|1] ""  VCU_LE,CSM_LE,RadioHead_LE
 SG_ PSPMCA_PsngStPrfMd2Avl : 20|1@0+ (1,0) [0|1] ""  VCU_LE,CSM_LE,RadioHead_LE
 SG_ PSPMCA_PsngStPrfMd1Avl : 21|1@0+ (1,0) [0|1] ""  VCU_LE,CSM_LE,RadioHead_LE
 SG_ DSPMCA_DrvrStPrfMd6Avl : 8|1@0+ (1,0) [0|1] ""  VCU_LE,CSM_LE,RadioHead_LE
 SG_ DSPMCA_DrvrStPrfMd5Avl : 9|1@0+ (1,0) [0|1] ""  VCU_LE,CSM_LE,RadioHead_LE
 SG_ DSPMCA_DrvrStPrfMd4Avl : 10|1@0+ (1,0) [0|1] ""  VCU_LE,CSM_LE,RadioHead_LE
 SG_ DSPMCA_DrvrStPrfMd3Avl : 11|1@0+ (1,0) [0|1] ""  VCU_LE,CSM_LE,RadioHead_LE
 SG_ DSPMCA_DrvrStPrfMd2Avl : 12|1@0+ (1,0) [0|1] ""  VCU_LE,CSM_LE,RadioHead_LE
 SG_ DSPMCA_DrvrStPrfMd1Avl : 13|1@0+ (1,0) [0|1] ""  VCU_LE,CSM_LE,RadioHead_LE
 SG_ DSPMCA_DrvStyPrfMd7Avl : 24|1@0+ (1,0) [0|1] ""  VCU_LE,CSM_LE,RadioHead_LE
 SG_ DSPMCA_DrvStyPrfMd6Avl : 25|1@0+ (1,0) [0|1] ""  VCU_LE,CSM_LE,RadioHead_LE
 SG_ DSPMCA_DrvStyPrfMd5Avl : 26|1@0+ (1,0) [0|1] ""  VCU_LE,CSM_LE,RadioHead_LE
 SG_ DSPMCA_DrvStyPrfMd4Avl : 27|1@0+ (1,0) [0|1] ""  VCU_LE,CSM_LE,RadioHead_LE
 SG_ DSPMCA_DrvStyPrfMd3Avl : 28|1@0+ (1,0) [0|1] ""  VCU_LE,CSM_LE,RadioHead_LE
 SG_ DSPMCA_DrvStyPrfMd2Avl : 29|1@0+ (1,0) [0|1] ""  VCU_LE,CSM_LE,RadioHead_LE
 SG_ DSPMCA_DrvStyPrfMd1Avl : 30|1@0+ (1,0) [0|1] ""  VCU_LE,CSM_LE,RadioHead_LE
 SG_ ACCPMCA_ACCPrfMd6Avl : 0|1@0+ (1,0) [0|1] ""  VCU_LE,CSM_LE,RadioHead_LE
 SG_ ACCPMCA_ACCPrfMd5Avl : 1|1@0+ (1,0) [0|1] ""  VCU_LE,CSM_LE,RadioHead_LE
 SG_ ACCPMCA_ACCPrfMd4Avl : 2|1@0+ (1,0) [0|1] ""  VCU_LE,CSM_LE,RadioHead_LE
 SG_ ACCPMCA_ACCPrfMd3Avl : 3|1@0+ (1,0) [0|1] ""  VCU_LE,CSM_LE,RadioHead_LE
 SG_ ACCPMCA_ACCPrfMd2Avl : 4|1@0+ (1,0) [0|1] ""  VCU_LE,CSM_LE,RadioHead_LE
 SG_ ACCPMCA_ACCPrfMd1Avl : 5|1@0+ (1,0) [0|1] ""  VCU_LE,CSM_LE,RadioHead_LE

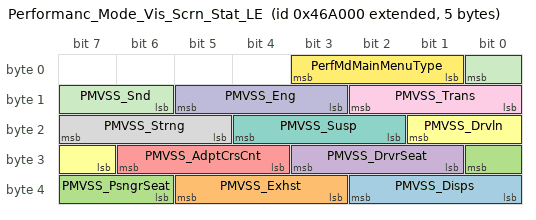
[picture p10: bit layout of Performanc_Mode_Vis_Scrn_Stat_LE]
BO_ 2152112128 Performanc_Mode_Vis_Scrn_Stat_LE: 5 CGM_LE
 SG_ PMVSS_Disps : 34|3@0+ (1,0) [0|7] ""  VCU_LE,CSM_LE,RadioHead_LE
 SG_ PMVSS_Exhst : 37|3@0+ (1,0) [0|7] ""  VCU_LE,CSM_LE,RadioHead_LE
 SG_ PMVSS_PsngrSeat : 24|3@0+ (1,0) [0|7] ""  VCU_LE,CSM_LE,RadioHead_LE
 SG_ PMVSS_DrvrSeat : 27|3@0+ (1,0) [0|7] ""  VCU_LE,CSM_LE,RadioHead_LE
 SG_ PMVSS_AdptCrsCnt : 30|3@0+ (1,0) [0|7] ""  VCU_LE,CSM_LE,RadioHead_LE
 SG_ PMVSS_Drvln : 17|3@0+ (1,0) [0|7] ""  VCU_LE,CSM_LE,RadioHead_LE
 SG_ PMVSS_Susp : 20|3@0+ (1,0) [0|7] ""  VCU_LE,CSM_LE,RadioHead_LE
 SG_ PMVSS_Strng : 23|3@0+ (1,0) [0|7] ""  VCU_LE,CSM_LE,RadioHead_LE
 SG_ PMVSS_Trans : 10|3@0+ (1,0) [0|7] ""  VCU_LE,CSM_LE,RadioHead_LE
 SG_ PMVSS_Eng : 13|3@0+ (1,0) [0|7] ""  VCU_LE,CSM_LE,RadioHead_LE
 SG_ PMVSS_Snd : 0|3@0+ (1,0) [0|7] ""  VCU_LE,CSM_LE,RadioHead_LE
 SG_ PerfMdMainMenuType : 3|3@0+ (1,0) [0|7] ""  VCU_LE,CSM_LE,RadioHead_LE

BO_ 2154299392 Car_Sharing_Info1_LE: 1 VKM_LE
 SG_ CrShrngVehChlngReq : 7|1@0+ (1,0) [0|1] ""  CGM_LE

BO_TX_BU_ 2154840064 : TCP_LE,CSM_LE,ONSTAR_LE,CGM_LE;
BO_TX_BU_ 2151890944 : TCP_LE,ONSTAR_LE;
BO_TX_BU_ 2156281856 : VCU_LE,CSM_LE,RadioHead_LE;
BO_TX_BU_ 2151948288 : VCU_LE,CSM_LE,RadioHead_LE;
CM_ BO_ 2151481344 "CAUTION!!!! BOTH GATED AND Tx ON LS!! DO NOT ADD ONLY GATED SIGNALS";
CM_ SG_ 2149908480 BrkPdlModTrvlV "Indicates that the brake pedal position has passed a threshold for brake torque management and some 2 channel Vehicle Dynamics Control systems.";
CM_ SG_ 2149908480 BrkPdlModTrvl "Indicates that the brake pedal position has passed a threshold for brake torque management and some 2 channel Vehicle Dynamics Control systems.";
CM_ SG_ 2154643456 AuxHtrAtv "Auxiliary Heater shall be used to denote a heater function that uses some kind of power, electrical or mechanical,  that was generated by the engine.";
CM_ SG_ 2154840064 CmpsCrHding "i.e., adjusted for declination zone, hysterisis, and filtering)";
CM_ BO_ 2154471424 "LAP: varför mappad i två olika VD'n?";
CM_ BO_ 2154987520 "LAP: Är det rätt Tx??? passar i frame0x130??";
BA_DEF_ SG_  "VNSigPrimaryTriggering" ENUM  "No","Yes","DLCLS","DLCHS","DLCCE","DLCFO";
BA_DEF_ SG_  "VNSigRemoteDiagnostics" ENUM  "No","Yes","DLCLS","DLCHS","DLCCE","DLCFO";
BA_DEF_ SG_  "VNSigInfotainment" ENUM  "No","Yes","DLCLS","DLCHS","DLCCE","DLCFO";
BA_DEF_ SG_  "VNSigParkedVehicle" ENUM  "No","Yes","DLCLS","DLCHS","DLCCE","DLCFO";
BA_DEF_ SG_  "VNSigIntermediate" ENUM  "No","Yes","DLCLS","DLCHS","DLCCE","DLCFO";
BA_DEF_ SG_  "VNSigUnused_4" ENUM  "No","Yes","DLCLS","DLCHS","DLCCE","DLCFO";
BA_DEF_ SG_  "SignalType" STRING ;
BA_DEF_ SG_  "PacketOrder" INT 0 65535;
BA_DEF_ SG_  "SignalLongName" STRING ;
BA_DEF_ SG_  "GenSigStartValue" INT 0 65535;
BA_DEF_ SG_  "VNSigDiagnostic" ENUM  "No","Yes","DLCLS","DLCHS","DLCCE","DLCFO";
BA_DEF_ SG_  "VNSigAllNodes" ENUM  "No","Yes","DLCLS","DLCHS","DLCCE","DLCFO";
BA_DEF_ SG_  "GenSigDeltaValue" INT 0 0;
BA_DEF_ SG_  "GenSigSendType" ENUM  "not used","not used","not used","not used","not used","not used","not used","NoSigSendType","not used","not used","OnAnyChange","OnChangeIfActive","OnDelta","DLCLS","DLCHS","DLCCE","DLCFO";
BA_DEF_ SG_  "GenSigSendOnInit" ENUM  "Not Initialized","Application","Handler","DLCLS","DLCHS","DLCCE","DLCFO";
BA_DEF_ BO_  "AppGenMsgCycleTime" INT 0 0;
BA_DEF_ BO_  "TpTxIndex" INT 0 99;
BA_DEF_ BO_  "GenMsgILSupport" ENUM  "No","Yes","DLCLS","DLCHS","DLCCE","DLCFO";
BA_DEF_ BO_  "TpApplType" STRING ;
BA_DEF_ BO_  "Prio" INT 0 7;
BA_DEF_ BO_  "MessageSubnet" ENUM  "LS","MS","HS","CE","PE","HV","FO","S1","HE","LE","HE2","DLCLS","DLCHS","DLCCE","DLCFO";
BA_DEF_ BO_  "GenMsgMandatoryToSupervision" ENUM  "No","Yes","DLCLS","DLCHS","DLCCE","DLCFO";
BA_DEF_ BO_  "DiagState" ENUM  "No","Yes","DLCLS","DLCHS","DLCCE","DLCFO";
BA_DEF_ BO_  "GenMsgStartDelayTime" INT 0 100000;
BA_DEF_ BO_  "GenMsgDelayTime" INT 0 100000;
BA_DEF_ BO_  "GenMsgCycleTime" INT 0 100000;
BA_DEF_ BO_  "GenMsgSendType" ENUM  "cyclicX","spontanX","cyclicIfActiveX","spontanWithDelay","cyclicAndSpontanX","cyclicAndSpontanWithDelay","spontanWithRepitition","cyclicIfActiveAndSpontanWD","DLCLS","DLCHS","DLCCE","DLCFO";
BA_DEF_ BO_  "DiagResponse" ENUM  "No","Yes","DLCLS","DLCHS","DLCCE","DLCFO";
BA_DEF_ BO_  "DiagRequest" ENUM  "No","Yes","DLCLS","DLCHS","DLCCE","DLCFO";
BA_DEF_ BO_  "NmMessage" ENUM  "No","Yes","DLCLS","DLCHS","DLCCE","DLCFO";
BA_DEF_REL_ BU_SG_REL_  "GenSigSuprvRespComment" STRING ;
BA_DEF_REL_ BU_SG_REL_  "GenSigVBitResp" ENUM  "No","Yes","DLCLS","DLCHS","DLCCE","DLCFO";
BA_DEF_REL_ BU_SG_REL_  "GenSigVBitRespComment" STRING ;
BA_DEF_REL_ BU_SG_REL_  "GenSigVDAFailComment" STRING ;
BA_DEF_REL_ BU_SG_REL_  "GenSigVDAFailResp" ENUM  "No","Yes","DLCLS","DLCHS","DLCCE","DLCFO";
BA_DEF_REL_ BU_SG_REL_  "GenSigRxStartValue" STRING ;
BA_DEF_REL_ BU_SG_REL_  "GenSigSuprvRespSubValue" INT 0 65535;
BA_DEF_REL_ BU_SG_REL_  "GenSigSuprvResp" ENUM  "None","Notify App","Substitute Default","DLCLS","DLCHS","DLCCE","DLCFO";
BA_DEF_REL_ BU_SG_REL_  "GenSigTimeoutMsg" HEX -2147483648 268435455;
BA_DEF_DEF_  "VNSigPrimaryTriggering" "No";
BA_DEF_DEF_  "VNSigRemoteDiagnostics" "No";
BA_DEF_DEF_  "VNSigInfotainment" "No";
BA_DEF_DEF_  "VNSigParkedVehicle" "No";
BA_DEF_DEF_  "VNSigIntermediate" "No";
BA_DEF_DEF_  "VNSigUnused_4" "No";
BA_DEF_DEF_  "SignalType" "";
BA_DEF_DEF_  "PacketOrder" 0;
BA_DEF_DEF_  "SignalLongName" "";
BA_DEF_DEF_  "GenSigStartValue" 0;
BA_DEF_DEF_  "VNSigDiagnostic" "No";
BA_DEF_DEF_  "VNSigAllNodes" "No";
BA_DEF_DEF_  "GenSigDeltaValue" 0;
BA_DEF_DEF_  "GenSigSendType" "NoSigSendType";
BA_DEF_DEF_  "GenSigSendOnInit" "Not Initialized";
BA_DEF_DEF_  "AppGenMsgCycleTime" 0;
BA_DEF_DEF_  "TpTxIndex" 0;
BA_DEF_DEF_  "GenMsgILSupport" "Yes";
BA_DEF_DEF_  "TpApplType" "";
BA_DEF_DEF_  "Prio" 4;
BA_DEF_DEF_  "MessageSubnet" "FO";
BA_DEF_DEF_  "GenMsgMandatoryToSupervision" "No";
BA_DEF_DEF_  "DiagState" "No";
BA_DEF_DEF_  "GenMsgStartDelayTime" 0;
BA_DEF_DEF_  "GenMsgDelayTime" 0;
BA_DEF_DEF_  "GenMsgCycleTime" 0;
BA_DEF_DEF_  "GenMsgSendType" "spontanX";
BA_DEF_DEF_  "DiagResponse" "No";
BA_DEF_DEF_  "DiagRequest" "No";
BA_DEF_DEF_  "NmMessage" "No";
BA_DEF_DEF_REL_ "GenSigSuprvRespComment" "";
BA_DEF_DEF_REL_ "GenSigVBitResp" "No";
BA_DEF_DEF_REL_ "GenSigVBitRespComment" "";
BA_DEF_DEF_REL_ "GenSigVDAFailComment" "";
BA_DEF_DEF_REL_ "GenSigVDAFailResp" "No";
BA_DEF_DEF_REL_ "GenSigRxStartValue" "";
BA_DEF_DEF_REL_ "GenSigSuprvRespSubValue" 0;
BA_DEF_DEF_REL_ "GenSigSuprvResp" "None";
BA_DEF_DEF_REL_ "GenSigTimeoutMsg" 0;
BA_ "MessageSubnet" BO_ 2156298240 9;
BA_ "GenMsgDelayTime" BO_ 2156298240 100;
BA_ "MessageSubnet" BO_ 2156331008 9;
BA_ "GenMsgDelayTime" BO_ 2156331008 100;
BA_ "MessageSubnet" BO_ 2158116864 9;
BA_ "GenMsgDelayTime" BO_ 2158116864 100;
BA_ "MessageSubnet" BO_ 2158149632 9;
BA_ "GenMsgDelayTime" BO_ 2158149632 100;
BA_ "MessageSubnet" BO_ 2150432768 9;
BA_ "GenMsgStartDelayTime" BO_ 2150432768 150;
BA_ "GenMsgCycleTime" BO_ 2150432768 500;
BA_ "GenMsgSendType" BO_ 2150432768 0;
BA_ "MessageSubnet" BO_ 2155413504 9;
BA_ "GenMsgDelayTime" BO_ 2155413504 100;
BA_ "Prio" BO_ 2154225664 3;
BA_ "MessageSubnet" BO_ 2154225664 9;
BA_ "GenMsgDelayTime" BO_ 2154225664 100;
BA_ "MessageSubnet" BO_ 2151481344 9;
BA_ "GenMsgCycleTime" BO_ 2151481344 200;
BA_ "GenMsgSendType" BO_ 2151481344 0;
BA_ "MessageSubnet" BO_ 2153381888 9;
BA_ "GenMsgDelayTime" BO_ 2153381888 100;
BA_ "MessageSubnet" BO_ 2153979904 9;
BA_ "GenMsgDelayTime" BO_ 2153979904 100;
BA_ "MessageSubnet" BO_ 2149908480 9;
BA_ "GenMsgStartDelayTime" BO_ 2149908480 130;
BA_ "GenMsgDelayTime" BO_ 2149908480 100;
BA_ "GenMsgCycleTime" BO_ 2149908480 1000;
BA_ "GenMsgSendType" BO_ 2149908480 0;
BA_ "MessageSubnet" BO_ 2154643456 9;
BA_ "GenMsgDelayTime" BO_ 2154643456 100;
BA_ "MessageSubnet" BO_ 2151186432 9;
BA_ "GenMsgDelayTime" BO_ 2151186432 100;
BA_ "MessageSubnet" BO_ 2150498304 9;
BA_ "GenMsgStartDelayTime" BO_ 2150498304 140;
BA_ "GenMsgCycleTime" BO_ 2150498304 1000;
BA_ "GenMsgSendType" BO_ 2150498304 0;
BA_ "MessageSubnet" BO_ 2154840064 9;
BA_ "GenMsgDelayTime" BO_ 2154840064 100;
BA_ "MessageSubnet" BO_ 2151890944 9;
BA_ "GenMsgDelayTime" BO_ 2151890944 100;
BA_ "GenMsgCycleTime" BO_ 2151890944 1500;
BA_ "GenMsgSendType" BO_ 2151890944 0;
BA_ "MessageSubnet" BO_ 2155896832 9;
BA_ "GenMsgStartDelayTime" BO_ 2155896832 170;
BA_ "GenMsgCycleTime" BO_ 2155896832 500;
BA_ "GenMsgSendType" BO_ 2155896832 0;
BA_ "MessageSubnet" BO_ 2154496000 9;
BA_ "GenMsgDelayTime" BO_ 2154496000 100;
BA_ "Prio" BO_ 2154471424 3;
BA_ "MessageSubnet" BO_ 2154471424 9;
BA_ "GenMsgDelayTime" BO_ 2154471424 100;
BA_ "MessageSubnet" BO_ 2151940096 9;
BA_ "GenMsgDelayTime" BO_ 2151940096 100;
BA_ "MessageSubnet" BO_ 2154987520 9;
BA_ "GenMsgDelayTime" BO_ 2154987520 100;
BA_ "MessageSubnet" BO_ 2156281856 9;
BA_ "GenMsgDelayTime" BO_ 2156281856 100;
BA_ "MessageSubnet" BO_ 2156314624 9;
BA_ "GenMsgDelayTime" BO_ 2156314624 100;
BA_ "MessageSubnet" BO_ 2149761024 9;
BA_ "GenMsgStartDelayTime" BO_ 2149761024 110;
BA_ "GenMsgCycleTime" BO_ 2149761024 250;
BA_ "GenMsgSendType" BO_ 2149761024 0;
BA_ "MessageSubnet" BO_ 2151997440 9;
BA_ "GenMsgDelayTime" BO_ 2151997440 100;
BA_ "MessageSubnet" BO_ 2151948288 9;
BA_ "GenMsgDelayTime" BO_ 2151948288 100;
BA_ "MessageSubnet" BO_ 2152128512 9;
BA_ "GenMsgCycleTime" BO_ 2152128512 2000;
BA_ "GenMsgSendType" BO_ 2152128512 0;
BA_ "MessageSubnet" BO_ 2152112128 9;
BA_ "GenMsgDelayTime" BO_ 2152112128 100;
BA_ "MessageSubnet" BO_ 2154299392 9;
BA_ "GenMsgDelayTime" BO_ 2154299392 100;
BA_ "GenSigSendType" SG_ 2156298240 HTRActvIndOn 10;
BA_ "GenSigSendOnInit" SG_ 2156298240 HTRActvIndOn 1;
BA_ "VNSigInfotainment" SG_ 2156298240 HTRActvIndOn 1;
BA_ "SignalType" SG_ 2156298240 HTRActvIndOn "BLN";
BA_ "SignalLongName" SG_ 2156298240 HTRActvIndOn "Hill Top Reserve Active Indication On";
BA_ "VNSigAllNodes" SG_ 2156298240 HTRActvIndOn 1;
BA_ "GenSigDeltaValue" SG_ 2156298240 HVBSTLPC_MntOfHr 1;
BA_ "GenSigSendType" SG_ 2156298240 HVBSTLPC_MntOfHr 12;
BA_ "GenSigSendOnInit" SG_ 2156298240 HVBSTLPC_MntOfHr 1;
BA_ "VNSigInfotainment" SG_ 2156298240 HVBSTLPC_MntOfHr 1;
BA_ "SignalType" SG_ 2156298240 HVBSTLPC_MntOfHr "UNM";
BA_ "PacketOrder" SG_ 2156298240 HVBSTLPC_MntOfHr 3;
BA_ "SignalLongName" SG_ 2156298240 HVBSTLPC_MntOfHr "High Voltage Battery Start Time Low Power Charge : Minute of Hour";
BA_ "VNSigAllNodes" SG_ 2156298240 HVBSTLPC_MntOfHr 1;
BA_ "GenSigDeltaValue" SG_ 2156298240 HVBSTLPC_HrOfDy 1;
BA_ "GenSigSendType" SG_ 2156298240 HVBSTLPC_HrOfDy 12;
BA_ "GenSigSendOnInit" SG_ 2156298240 HVBSTLPC_HrOfDy 1;
BA_ "VNSigInfotainment" SG_ 2156298240 HVBSTLPC_HrOfDy 1;
BA_ "SignalType" SG_ 2156298240 HVBSTLPC_HrOfDy "UNM";
BA_ "PacketOrder" SG_ 2156298240 HVBSTLPC_HrOfDy 2;
BA_ "SignalLongName" SG_ 2156298240 HVBSTLPC_HrOfDy "High Voltage Battery Start Time Low Power Charge : Hour of Day";
BA_ "VNSigAllNodes" SG_ 2156298240 HVBSTLPC_HrOfDy 1;
BA_ "GenSigSendType" SG_ 2156298240 HVBSTLPC_DyOfWk 10;
BA_ "GenSigSendOnInit" SG_ 2156298240 HVBSTLPC_DyOfWk 1;
BA_ "VNSigInfotainment" SG_ 2156298240 HVBSTLPC_DyOfWk 1;
BA_ "SignalType" SG_ 2156298240 HVBSTLPC_DyOfWk "ENM";
BA_ "PacketOrder" SG_ 2156298240 HVBSTLPC_DyOfWk 1;
BA_ "SignalLongName" SG_ 2156298240 HVBSTLPC_DyOfWk "High Voltage Battery Start Time Low Power Charge : Day of Week";
BA_ "VNSigAllNodes" SG_ 2156298240 HVBSTLPC_DyOfWk 1;
BA_ "GenSigDeltaValue" SG_ 2156298240 HVBSTHPC_MntOfHr 1;
BA_ "GenSigSendType" SG_ 2156298240 HVBSTHPC_MntOfHr 12;
BA_ "GenSigSendOnInit" SG_ 2156298240 HVBSTHPC_MntOfHr 1;
BA_ "VNSigInfotainment" SG_ 2156298240 HVBSTHPC_MntOfHr 1;
BA_ "SignalType" SG_ 2156298240 HVBSTHPC_MntOfHr "UNM";
BA_ "PacketOrder" SG_ 2156298240 HVBSTHPC_MntOfHr 3;
BA_ "SignalLongName" SG_ 2156298240 HVBSTHPC_MntOfHr "High Voltage Battery Start Time High Power Charge : Minute of Hour";
BA_ "VNSigAllNodes" SG_ 2156298240 HVBSTHPC_MntOfHr 1;
BA_ "GenSigDeltaValue" SG_ 2156298240 HVBSTHPC_HrOfDy 1;
BA_ "GenSigSendType" SG_ 2156298240 HVBSTHPC_HrOfDy 12;
BA_ "GenSigSendOnInit" SG_ 2156298240 HVBSTHPC_HrOfDy 1;
BA_ "VNSigInfotainment" SG_ 2156298240 HVBSTHPC_HrOfDy 1;
BA_ "SignalType" SG_ 2156298240 HVBSTHPC_HrOfDy "UNM";
BA_ "PacketOrder" SG_ 2156298240 HVBSTHPC_HrOfDy 2;
BA_ "SignalLongName" SG_ 2156298240 HVBSTHPC_HrOfDy "High Voltage Battery Start Time High Power Charge : Hour of Day";
BA_ "VNSigAllNodes" SG_ 2156298240 HVBSTHPC_HrOfDy 1;
BA_ "GenSigSendType" SG_ 2156298240 HVBSTHPC_DyOfWk 10;
BA_ "GenSigSendOnInit" SG_ 2156298240 HVBSTHPC_DyOfWk 1;
BA_ "VNSigInfotainment" SG_ 2156298240 HVBSTHPC_DyOfWk 1;
BA_ "SignalType" SG_ 2156298240 HVBSTHPC_DyOfWk "ENM";
BA_ "PacketOrder" SG_ 2156298240 HVBSTHPC_DyOfWk 1;
BA_ "SignalLongName" SG_ 2156298240 HVBSTHPC_DyOfWk "High Voltage Battery Start Time High Power Charge : Day of Week";
BA_ "VNSigAllNodes" SG_ 2156298240 HVBSTHPC_DyOfWk 1;
BA_ "GenSigDeltaValue" SG_ 2156298240 HVBCTLPC_MntOfHr 1;
BA_ "GenSigSendType" SG_ 2156298240 HVBCTLPC_MntOfHr 12;
BA_ "GenSigSendOnInit" SG_ 2156298240 HVBCTLPC_MntOfHr 1;
BA_ "VNSigInfotainment" SG_ 2156298240 HVBCTLPC_MntOfHr 1;
BA_ "SignalType" SG_ 2156298240 HVBCTLPC_MntOfHr "UNM";
BA_ "PacketOrder" SG_ 2156298240 HVBCTLPC_MntOfHr 3;
BA_ "SignalLongName" SG_ 2156298240 HVBCTLPC_MntOfHr "High Voltage Battery Complete Time Low Power Charge : Minute of Hour";
BA_ "VNSigAllNodes" SG_ 2156298240 HVBCTLPC_MntOfHr 1;
BA_ "GenSigDeltaValue" SG_ 2156298240 HVBCTLPC_HrOfDy 1;
BA_ "GenSigSendType" SG_ 2156298240 HVBCTLPC_HrOfDy 12;
BA_ "GenSigSendOnInit" SG_ 2156298240 HVBCTLPC_HrOfDy 1;
BA_ "VNSigInfotainment" SG_ 2156298240 HVBCTLPC_HrOfDy 1;
BA_ "SignalType" SG_ 2156298240 HVBCTLPC_HrOfDy "UNM";
BA_ "PacketOrder" SG_ 2156298240 HVBCTLPC_HrOfDy 2;
BA_ "SignalLongName" SG_ 2156298240 HVBCTLPC_HrOfDy "High Voltage Battery Complete Time Low Power Charge : Hour of Day";
BA_ "VNSigAllNodes" SG_ 2156298240 HVBCTLPC_HrOfDy 1;
BA_ "GenSigSendType" SG_ 2156298240 HVBCTLPC_DyOfWk 10;
BA_ "GenSigSendOnInit" SG_ 2156298240 HVBCTLPC_DyOfWk 1;
BA_ "VNSigInfotainment" SG_ 2156298240 HVBCTLPC_DyOfWk 1;
BA_ "SignalType" SG_ 2156298240 HVBCTLPC_DyOfWk "ENM";
BA_ "PacketOrder" SG_ 2156298240 HVBCTLPC_DyOfWk 1;
BA_ "SignalLongName" SG_ 2156298240 HVBCTLPC_DyOfWk "High Voltage Battery Complete Time Low Power Charge : Day of Week";
BA_ "VNSigAllNodes" SG_ 2156298240 HVBCTLPC_DyOfWk 1;
BA_ "GenSigDeltaValue" SG_ 2156298240 HVBCTHPC_MntOfHr 1;
BA_ "GenSigSendType" SG_ 2156298240 HVBCTHPC_MntOfHr 12;
BA_ "GenSigSendOnInit" SG_ 2156298240 HVBCTHPC_MntOfHr 1;
BA_ "VNSigInfotainment" SG_ 2156298240 HVBCTHPC_MntOfHr 1;
BA_ "SignalType" SG_ 2156298240 HVBCTHPC_MntOfHr "UNM";
BA_ "PacketOrder" SG_ 2156298240 HVBCTHPC_MntOfHr 3;
BA_ "SignalLongName" SG_ 2156298240 HVBCTHPC_MntOfHr "High Voltage Battery Complete Time High Power Charge : Minute of Hour";
BA_ "VNSigAllNodes" SG_ 2156298240 HVBCTHPC_MntOfHr 1;
BA_ "GenSigDeltaValue" SG_ 2156298240 HVBCTHPC_HrOfDy 1;
BA_ "GenSigSendType" SG_ 2156298240 HVBCTHPC_HrOfDy 12;
BA_ "GenSigSendOnInit" SG_ 2156298240 HVBCTHPC_HrOfDy 1;
BA_ "VNSigInfotainment" SG_ 2156298240 HVBCTHPC_HrOfDy 1;
BA_ "SignalType" SG_ 2156298240 HVBCTHPC_HrOfDy "UNM";
BA_ "PacketOrder" SG_ 2156298240 HVBCTHPC_HrOfDy 2;
BA_ "SignalLongName" SG_ 2156298240 HVBCTHPC_HrOfDy "High Voltage Battery Complete Time High Power Charge : Hour of Day";
BA_ "VNSigAllNodes" SG_ 2156298240 HVBCTHPC_HrOfDy 1;
BA_ "GenSigSendType" SG_ 2156298240 HVBCTHPC_DyOfWk 10;
BA_ "GenSigSendOnInit" SG_ 2156298240 HVBCTHPC_DyOfWk 1;
BA_ "VNSigInfotainment" SG_ 2156298240 HVBCTHPC_DyOfWk 1;
BA_ "SignalType" SG_ 2156298240 HVBCTHPC_DyOfWk "ENM";
BA_ "PacketOrder" SG_ 2156298240 HVBCTHPC_DyOfWk 1;
BA_ "SignalLongName" SG_ 2156298240 HVBCTHPC_DyOfWk "High Voltage Battery Complete Time High Power Charge : Day of Week";
BA_ "VNSigAllNodes" SG_ 2156298240 HVBCTHPC_DyOfWk 1;
BA_ "GenSigSendType" SG_ 2156298240 InvldHMIEtrIO 10;
BA_ "VNSigInfotainment" SG_ 2156298240 InvldHMIEtrIO 1;
BA_ "SignalType" SG_ 2156298240 InvldHMIEtrIO "BLN";
BA_ "SignalLongName" SG_ 2156298240 InvldHMIEtrIO "Invalid HMI Entry Indication On";
BA_ "VNSigAllNodes" SG_ 2156298240 InvldHMIEtrIO 1;
BA_ "GenSigSendType" SG_ 2156298240 InsfcntTmTFlChrgIO 10;
BA_ "VNSigInfotainment" SG_ 2156298240 InsfcntTmTFlChrgIO 1;
BA_ "SignalType" SG_ 2156298240 InsfcntTmTFlChrgIO "BLN";
BA_ "SignalLongName" SG_ 2156298240 InsfcntTmTFlChrgIO "Insufficient Time to Fully Charge Indication On";
BA_ "VNSigAllNodes" SG_ 2156298240 InsfcntTmTFlChrgIO 1;
BA_ "GenSigSendType" SG_ 2156298240 HVBatChrgCrdAlrtReq 10;
BA_ "VNSigInfotainment" SG_ 2156298240 HVBatChrgCrdAlrtReq 1;
BA_ "SignalType" SG_ 2156298240 HVBatChrgCrdAlrtReq "ENM";
BA_ "SignalLongName" SG_ 2156298240 HVBatChrgCrdAlrtReq "High Voltage Battery Charge Cord Alert Request";
BA_ "VNSigAllNodes" SG_ 2156298240 HVBatChrgCrdAlrtReq 1;
BA_ "GenSigSendType" SG_ 2156298240 HVCSDTES_NPDTIO 10;
BA_ "GenSigSendOnInit" SG_ 2156298240 HVCSDTES_NPDTIO 1;
BA_ "VNSigInfotainment" SG_ 2156298240 HVCSDTES_NPDTIO 1;
BA_ "SignalType" SG_ 2156298240 HVCSDTES_NPDTIO "BLN";
BA_ "PacketOrder" SG_ 2156298240 HVCSDTES_NPDTIO 3;
BA_ "SignalLongName" SG_ 2156298240 HVCSDTES_NPDTIO "High Voltage Charging System Departure Time Exceeded Status : Next Planned Departure Time Indication On";
BA_ "VNSigAllNodes" SG_ 2156298240 HVCSDTES_NPDTIO 1;
BA_ "GenSigSendType" SG_ 2156298240 HVCSDTES_LoPwrCIO 10;
BA_ "GenSigSendOnInit" SG_ 2156298240 HVCSDTES_LoPwrCIO 1;
BA_ "VNSigInfotainment" SG_ 2156298240 HVCSDTES_LoPwrCIO 1;
BA_ "SignalType" SG_ 2156298240 HVCSDTES_LoPwrCIO "BLN";
BA_ "PacketOrder" SG_ 2156298240 HVCSDTES_LoPwrCIO 1;
BA_ "SignalLongName" SG_ 2156298240 HVCSDTES_LoPwrCIO "High Voltage Charging System Departure Time Exceeded Status : Low Power Charge Complete Time Indication On";
BA_ "VNSigAllNodes" SG_ 2156298240 HVCSDTES_LoPwrCIO 1;
BA_ "GenSigSendType" SG_ 2156298240 HVCSDTES_HiPwrCIO 10;
BA_ "GenSigSendOnInit" SG_ 2156298240 HVCSDTES_HiPwrCIO 1;
BA_ "VNSigInfotainment" SG_ 2156298240 HVCSDTES_HiPwrCIO 1;
BA_ "SignalType" SG_ 2156298240 HVCSDTES_HiPwrCIO "BLN";
BA_ "PacketOrder" SG_ 2156298240 HVCSDTES_HiPwrCIO 2;
BA_ "SignalLongName" SG_ 2156298240 HVCSDTES_HiPwrCIO "High Voltage Charging System Departure Time Exceeded Status : High Power Charge Complete Time Indication On";
BA_ "VNSigAllNodes" SG_ 2156298240 HVCSDTES_HiPwrCIO 1;
BA_ "GenSigSendType" SG_ 2156331008 EUSD_MsrmntUnit 10;
BA_ "PacketOrder" SG_ 2156331008 EUSD_MsrmntUnit 2;
BA_ "VNSigInfotainment" SG_ 2156331008 EUSD_MsrmntUnit 1;
BA_ "SignalType" SG_ 2156331008 EUSD_MsrmntUnit "ENM";
BA_ "SignalLongName" SG_ 2156331008 EUSD_MsrmntUnit "Energy Usage Score Display : Measurement Unit";
BA_ "VNSigAllNodes" SG_ 2156331008 EUSD_MsrmntUnit 1;
BA_ "GenSigDeltaValue" SG_ 2156331008 EUSD_MsrmntVal 1;
BA_ "GenSigSendType" SG_ 2156331008 EUSD_MsrmntVal 12;
BA_ "PacketOrder" SG_ 2156331008 EUSD_MsrmntVal 1;
BA_ "VNSigInfotainment" SG_ 2156331008 EUSD_MsrmntVal 1;
BA_ "SignalType" SG_ 2156331008 EUSD_MsrmntVal "UNM";
BA_ "SignalLongName" SG_ 2156331008 EUSD_MsrmntVal "Energy Usage Score Display : Measurement Value";
BA_ "VNSigAllNodes" SG_ 2156331008 EUSD_MsrmntVal 1;
BA_ "GenSigSendType" SG_ 2156331008 LwRngLVLdShdRq 10;
BA_ "VNSigInfotainment" SG_ 2156331008 LwRngLVLdShdRq 1;
BA_ "SignalType" SG_ 2156331008 LwRngLVLdShdRq "ENM";
BA_ "SignalLongName" SG_ 2156331008 LwRngLVLdShdRq "Low Range Low Voltage Load Shedding Request";
BA_ "VNSigAllNodes" SG_ 2156331008 LwRngLVLdShdRq 1;
BA_ "GenSigDeltaValue" SG_ 2156331008 HVDpltnMdMiCnfdcRg 1;
BA_ "GenSigSendType" SG_ 2156331008 HVDpltnMdMiCnfdcRg 12;
BA_ "GenSigSendOnInit" SG_ 2156331008 HVDpltnMdMiCnfdcRg 1;
BA_ "VNSigInfotainment" SG_ 2156331008 HVDpltnMdMiCnfdcRg 1;
BA_ "SignalType" SG_ 2156331008 HVDpltnMdMiCnfdcRg "UNM";
BA_ "SignalLongName" SG_ 2156331008 HVDpltnMdMiCnfdcRg "High Voltage Depletion Mode Minimum Confidence Range";
BA_ "VNSigAllNodes" SG_ 2156331008 HVDpltnMdMiCnfdcRg 1;
BA_ "GenSigDeltaValue" SG_ 2156331008 HVDpltnMdMxCnfdcRg 1;
BA_ "GenSigSendType" SG_ 2156331008 HVDpltnMdMxCnfdcRg 12;
BA_ "GenSigSendOnInit" SG_ 2156331008 HVDpltnMdMxCnfdcRg 1;
BA_ "VNSigInfotainment" SG_ 2156331008 HVDpltnMdMxCnfdcRg 1;
BA_ "SignalType" SG_ 2156331008 HVDpltnMdMxCnfdcRg "UNM";
BA_ "SignalLongName" SG_ 2156331008 HVDpltnMdMxCnfdcRg "High Voltage Depletion Mode Maximum Confidence Range";
BA_ "VNSigAllNodes" SG_ 2156331008 HVDpltnMdMxCnfdcRg 1;
BA_ "GenSigSendType" SG_ 2158116864 HVBatOvrhtdRdIO 10;
BA_ "SignalType" SG_ 2158116864 HVBatOvrhtdRdIO "BLN";
BA_ "SignalLongName" SG_ 2158116864 HVBatOvrhtdRdIO "High Voltage Battery Overheated Redundant Indication On";
BA_ "VNSigAllNodes" SG_ 2158116864 HVBatOvrhtdRdIO 1;
BA_ "GenSigSendType" SG_ 2158116864 SrvcHghVltBatIndReq 10;
BA_ "SignalType" SG_ 2158116864 SrvcHghVltBatIndReq "ENM";
BA_ "SignalLongName" SG_ 2158116864 SrvcHghVltBatIndReq "Service High Voltage Battery Indication Request";
BA_ "VNSigAllNodes" SG_ 2158116864 SrvcHghVltBatIndReq 1;
BA_ "GenSigSendType" SG_ 2158116864 ChrgStPkInScnActIO 10;
BA_ "SignalType" SG_ 2158116864 ChrgStPkInScnActIO "BLN";
BA_ "SignalLongName" SG_ 2158116864 ChrgStPkInScnActIO "Charge Status Peek In Screen Active Indication On";
BA_ "VNSigAllNodes" SG_ 2158116864 ChrgStPkInScnActIO 1;
BA_ "GenSigDeltaValue" SG_ 2158116864 HVBTBRCR_RtCHSlctTblRwStat 1;
BA_ "GenSigSendType" SG_ 2158116864 HVBTBRCR_RtCHSlctTblRwStat 12;
BA_ "GenSigSendOnInit" SG_ 2158116864 HVBTBRCR_RtCHSlctTblRwStat 1;
BA_ "VNSigInfotainment" SG_ 2158116864 HVBTBRCR_RtCHSlctTblRwStat 1;
BA_ "SignalType" SG_ 2158116864 HVBTBRCR_RtCHSlctTblRwStat "UNM";
BA_ "PacketOrder" SG_ 2158116864 HVBTBRCR_RtCHSlctTblRwStat 7;
BA_ "SignalLongName" SG_ 2158116864 HVBTBRCR_RtCHSlctTblRwStat "High Voltage Battery Time Based Rate Charging Response : Rate Charging Selected Table Row Status";
BA_ "VNSigAllNodes" SG_ 2158116864 HVBTBRCR_RtCHSlctTblRwStat 1;
BA_ "GenSigSendType" SG_ 2158116864 HVBTBRCR_RtChSlctStat 10;
BA_ "GenSigSendOnInit" SG_ 2158116864 HVBTBRCR_RtChSlctStat 1;
BA_ "VNSigInfotainment" SG_ 2158116864 HVBTBRCR_RtChSlctStat 1;
BA_ "SignalType" SG_ 2158116864 HVBTBRCR_RtChSlctStat "ENM";
BA_ "PacketOrder" SG_ 2158116864 HVBTBRCR_RtChSlctStat 3;
BA_ "SignalLongName" SG_ 2158116864 HVBTBRCR_RtChSlctStat "High Voltage Battery Time Based Rate Charging Response : Rate Charging Selected Status";
BA_ "VNSigAllNodes" SG_ 2158116864 HVBTBRCR_RtChSlctStat 1;
BA_ "GenSigSendType" SG_ 2158116864 HVBTBRCR_RtChSlRtStat 10;
BA_ "GenSigSendOnInit" SG_ 2158116864 HVBTBRCR_RtChSlRtStat 1;
BA_ "VNSigInfotainment" SG_ 2158116864 HVBTBRCR_RtChSlRtStat 1;
BA_ "SignalType" SG_ 2158116864 HVBTBRCR_RtChSlRtStat "ENM";
BA_ "PacketOrder" SG_ 2158116864 HVBTBRCR_RtChSlRtStat 6;
BA_ "SignalLongName" SG_ 2158116864 HVBTBRCR_RtChSlRtStat "High Voltage Battery Time Based Rate Charging Response : Rate Charging Selected Rate Status";
BA_ "VNSigAllNodes" SG_ 2158116864 HVBTBRCR_RtChSlRtStat 1;
BA_ "GenSigSendType" SG_ 2158116864 HVBTBRCR_RtChSsnStat 10;
BA_ "GenSigSendOnInit" SG_ 2158116864 HVBTBRCR_RtChSsnStat 1;
BA_ "VNSigInfotainment" SG_ 2158116864 HVBTBRCR_RtChSsnStat 1;
BA_ "SignalType" SG_ 2158116864 HVBTBRCR_RtChSsnStat "ENM";
BA_ "PacketOrder" SG_ 2158116864 HVBTBRCR_RtChSsnStat 1;
BA_ "SignalLongName" SG_ 2158116864 HVBTBRCR_RtChSsnStat "High Voltage Battery Time Based Rate Charging Response : Rate Charging Season Status";
BA_ "VNSigAllNodes" SG_ 2158116864 HVBTBRCR_RtChSsnStat 1;
BA_ "GenSigDeltaValue" SG_ 2158116864 HVBTBRCR_RtChMHRsp 1;
BA_ "GenSigSendType" SG_ 2158116864 HVBTBRCR_RtChMHRsp 12;
BA_ "GenSigSendOnInit" SG_ 2158116864 HVBTBRCR_RtChMHRsp 1;
BA_ "VNSigInfotainment" SG_ 2158116864 HVBTBRCR_RtChMHRsp 1;
BA_ "SignalType" SG_ 2158116864 HVBTBRCR_RtChMHRsp "UNM";
BA_ "PacketOrder" SG_ 2158116864 HVBTBRCR_RtChMHRsp 2;
BA_ "SignalLongName" SG_ 2158116864 HVBTBRCR_RtChMHRsp "High Voltage Battery Time Based Rate Charging Response : Rate Charging Minute of Hour Response";
BA_ "VNSigAllNodes" SG_ 2158116864 HVBTBRCR_RtChMHRsp 1;
BA_ "GenSigDeltaValue" SG_ 2158116864 HVBTBRCR_RtChHRsp 1;
BA_ "GenSigSendType" SG_ 2158116864 HVBTBRCR_RtChHRsp 12;
BA_ "GenSigSendOnInit" SG_ 2158116864 HVBTBRCR_RtChHRsp 1;
BA_ "VNSigInfotainment" SG_ 2158116864 HVBTBRCR_RtChHRsp 1;
BA_ "SignalType" SG_ 2158116864 HVBTBRCR_RtChHRsp "UNM";
BA_ "PacketOrder" SG_ 2158116864 HVBTBRCR_RtChHRsp 4;
BA_ "SignalLongName" SG_ 2158116864 HVBTBRCR_RtChHRsp "High Voltage Battery Time Based Rate Charging Response : Rate Charging Hour Response";
BA_ "VNSigAllNodes" SG_ 2158116864 HVBTBRCR_RtChHRsp 1;
BA_ "GenSigSendType" SG_ 2158116864 HVBTBRCR_RtChDStat 10;
BA_ "GenSigSendOnInit" SG_ 2158116864 HVBTBRCR_RtChDStat 1;
BA_ "VNSigInfotainment" SG_ 2158116864 HVBTBRCR_RtChDStat 1;
BA_ "SignalType" SG_ 2158116864 HVBTBRCR_RtChDStat "ENM";
BA_ "PacketOrder" SG_ 2158116864 HVBTBRCR_RtChDStat 5;
BA_ "SignalLongName" SG_ 2158116864 HVBTBRCR_RtChDStat "High Voltage Battery Time Based Rate Charging Response : Rate Charging Day Status";
BA_ "VNSigAllNodes" SG_ 2158116864 HVBTBRCR_RtChDStat 1;
BA_ "GenSigSendType" SG_ 2158116864 HVBTBDCRS_DlChSlctStat 10;
BA_ "GenSigSendOnInit" SG_ 2158116864 HVBTBDCRS_DlChSlctStat 1;
BA_ "VNSigInfotainment" SG_ 2158116864 HVBTBDCRS_DlChSlctStat 1;
BA_ "SignalType" SG_ 2158116864 HVBTBDCRS_DlChSlctStat "ENM";
BA_ "PacketOrder" SG_ 2158116864 HVBTBDCRS_DlChSlctStat 3;
BA_ "SignalLongName" SG_ 2158116864 HVBTBDCRS_DlChSlctStat "High Voltage Battery Time Based Delayed Charging Response : Delayed Charging Selected Status";
BA_ "VNSigAllNodes" SG_ 2158116864 HVBTBDCRS_DlChSlctStat 1;
BA_ "GenSigSendType" SG_ 2158116864 HVBTBDCRS_DlChSsnStat 10;
BA_ "GenSigSendOnInit" SG_ 2158116864 HVBTBDCRS_DlChSsnStat 1;
BA_ "VNSigInfotainment" SG_ 2158116864 HVBTBDCRS_DlChSsnStat 1;
BA_ "SignalType" SG_ 2158116864 HVBTBDCRS_DlChSsnStat "ENM";
BA_ "PacketOrder" SG_ 2158116864 HVBTBDCRS_DlChSsnStat 4;
BA_ "SignalLongName" SG_ 2158116864 HVBTBDCRS_DlChSsnStat "High Voltage Battery Time Based Delayed Charging Response : Delayed Charging Season Status";
BA_ "VNSigAllNodes" SG_ 2158116864 HVBTBDCRS_DlChSsnStat 1;
BA_ "GenSigDeltaValue" SG_ 2158116864 HVBTBDCRS_DlChMHRsp 1;
BA_ "GenSigSendType" SG_ 2158116864 HVBTBDCRS_DlChMHRsp 12;
BA_ "GenSigSendOnInit" SG_ 2158116864 HVBTBDCRS_DlChMHRsp 1;
BA_ "VNSigInfotainment" SG_ 2158116864 HVBTBDCRS_DlChMHRsp 1;
BA_ "SignalType" SG_ 2158116864 HVBTBDCRS_DlChMHRsp "UNM";
BA_ "PacketOrder" SG_ 2158116864 HVBTBDCRS_DlChMHRsp 5;
BA_ "SignalLongName" SG_ 2158116864 HVBTBDCRS_DlChMHRsp "High Voltage Battery Time Based Delayed Charging Response : Delayed Charging Minute of Hour Response";
BA_ "VNSigAllNodes" SG_ 2158116864 HVBTBDCRS_DlChMHRsp 1;
BA_ "GenSigDeltaValue" SG_ 2158116864 HVBTBDCRS_DlChHRsp 1;
BA_ "GenSigSendType" SG_ 2158116864 HVBTBDCRS_DlChHRsp 12;
BA_ "GenSigSendOnInit" SG_ 2158116864 HVBTBDCRS_DlChHRsp 1;
BA_ "VNSigInfotainment" SG_ 2158116864 HVBTBDCRS_DlChHRsp 1;
BA_ "SignalType" SG_ 2158116864 HVBTBDCRS_DlChHRsp "UNM";
BA_ "PacketOrder" SG_ 2158116864 HVBTBDCRS_DlChHRsp 1;
BA_ "SignalLongName" SG_ 2158116864 HVBTBDCRS_DlChHRsp "High Voltage Battery Time Based Delayed Charging Response : Delayed Charging Hour Response";
BA_ "VNSigAllNodes" SG_ 2158116864 HVBTBDCRS_DlChHRsp 1;
BA_ "GenSigSendType" SG_ 2158116864 HVBTBDCRS_DlChDStat 10;
BA_ "GenSigSendOnInit" SG_ 2158116864 HVBTBDCRS_DlChDStat 1;
BA_ "VNSigInfotainment" SG_ 2158116864 HVBTBDCRS_DlChDStat 1;
BA_ "SignalType" SG_ 2158116864 HVBTBDCRS_DlChDStat "ENM";
BA_ "PacketOrder" SG_ 2158116864 HVBTBDCRS_DlChDStat 2;
BA_ "SignalLongName" SG_ 2158116864 HVBTBDCRS_DlChDStat "High Voltage Battery Time Based Delayed Charging Response : Delayed Charging Day Status";
BA_ "VNSigAllNodes" SG_ 2158116864 HVBTBDCRS_DlChDStat 1;
BA_ "GenSigSendType" SG_ 2158116864 HVBatStrtTmDspFrmt 10;
BA_ "VNSigInfotainment" SG_ 2158116864 HVBatStrtTmDspFrmt 1;
BA_ "SignalType" SG_ 2158116864 HVBatStrtTmDspFrmt "ENM";
BA_ "SignalLongName" SG_ 2158116864 HVBatStrtTmDspFrmt "High Voltage Battery Start Time Display Format";
BA_ "VNSigAllNodes" SG_ 2158116864 HVBatStrtTmDspFrmt 1;
BA_ "GenSigDeltaValue" SG_ 2158116864 OBHVBCMinsRmng 1;
BA_ "GenSigSendType" SG_ 2158116864 OBHVBCMinsRmng 12;
BA_ "VNSigInfotainment" SG_ 2158116864 OBHVBCMinsRmng 1;
BA_ "SignalType" SG_ 2158116864 OBHVBCMinsRmng "UNM";
BA_ "SignalLongName" SG_ 2158116864 OBHVBCMinsRmng "Off Board High Voltage Bulk Charging Minutes Remaining";
BA_ "VNSigAllNodes" SG_ 2158116864 OBHVBCMinsRmng 1;
BA_ "GenSigSendType" SG_ 2158116864 OBHVBCCompTmDispFrmt 10;
BA_ "VNSigInfotainment" SG_ 2158116864 OBHVBCCompTmDispFrmt 1;
BA_ "SignalType" SG_ 2158116864 OBHVBCCompTmDispFrmt "ENM";
BA_ "SignalLongName" SG_ 2158116864 OBHVBCCompTmDispFrmt "Off Board High Voltage Bulk Charging Completion Time Display Format";
BA_ "VNSigAllNodes" SG_ 2158116864 OBHVBCCompTmDispFrmt 1;
BA_ "GenSigSendType" SG_ 2158149632 ECHGCD_XAxTkMrkInterv 10;
BA_ "PacketOrder" SG_ 2158149632 ECHGCD_XAxTkMrkInterv 3;
BA_ "VNSigInfotainment" SG_ 2158149632 ECHGCD_XAxTkMrkInterv 1;
BA_ "SignalType" SG_ 2158149632 ECHGCD_XAxTkMrkInterv "ENM";
BA_ "SignalLongName" SG_ 2158149632 ECHGCD_XAxTkMrkInterv "Energy Consumption History Graph Configuration Data : X Axis Tick Mark Interval";
BA_ "VNSigAllNodes" SG_ 2158149632 ECHGCD_XAxTkMrkInterv 1;
BA_ "GenSigDeltaValue" SG_ 2158149632 ECHGCD_YAxMaxVal 1;
BA_ "GenSigSendType" SG_ 2158149632 ECHGCD_YAxMaxVal 12;
BA_ "PacketOrder" SG_ 2158149632 ECHGCD_YAxMaxVal 2;
BA_ "VNSigInfotainment" SG_ 2158149632 ECHGCD_YAxMaxVal 1;
BA_ "SignalType" SG_ 2158149632 ECHGCD_YAxMaxVal "UNM";
BA_ "SignalLongName" SG_ 2158149632 ECHGCD_YAxMaxVal "Energy Consumption History Graph Configuration Data : Y Axis Maximum Value";
BA_ "VNSigAllNodes" SG_ 2158149632 ECHGCD_YAxMaxVal 1;
BA_ "GenSigSendType" SG_ 2158149632 ECHGCD_MeasUt 10;
BA_ "PacketOrder" SG_ 2158149632 ECHGCD_MeasUt 1;
BA_ "VNSigInfotainment" SG_ 2158149632 ECHGCD_MeasUt 1;
BA_ "SignalType" SG_ 2158149632 ECHGCD_MeasUt "ENM";
BA_ "SignalLongName" SG_ 2158149632 ECHGCD_MeasUt "Energy Consumption History Graph Configuration Data : Measurement Unit";
BA_ "VNSigAllNodes" SG_ 2158149632 ECHGCD_MeasUt 1;
BA_ "GenSigDeltaValue" SG_ 2158149632 HVBTBSCR_SsnDyStat 1;
BA_ "GenSigSendType" SG_ 2158149632 HVBTBSCR_SsnDyStat 12;
BA_ "GenSigSendOnInit" SG_ 2158149632 HVBTBSCR_SsnDyStat 1;
BA_ "VNSigInfotainment" SG_ 2158149632 HVBTBSCR_SsnDyStat 1;
BA_ "SignalType" SG_ 2158149632 HVBTBSCR_SsnDyStat "UNM";
BA_ "PacketOrder" SG_ 2158149632 HVBTBSCR_SsnDyStat 4;
BA_ "SignalLongName" SG_ 2158149632 HVBTBSCR_SsnDyStat "High Voltage Battery Time Based Season Charging Response : Season Day Status";
BA_ "VNSigAllNodes" SG_ 2158149632 HVBTBSCR_SsnDyStat 1;
BA_ "GenSigSendType" SG_ 2158149632 HVBTBSCR_SsnStat 10;
BA_ "GenSigSendOnInit" SG_ 2158149632 HVBTBSCR_SsnStat 1;
BA_ "VNSigInfotainment" SG_ 2158149632 HVBTBSCR_SsnStat 1;
BA_ "SignalType" SG_ 2158149632 HVBTBSCR_SsnStat "ENM";
BA_ "PacketOrder" SG_ 2158149632 HVBTBSCR_SsnStat 1;
BA_ "SignalLongName" SG_ 2158149632 HVBTBSCR_SsnStat "High Voltage Battery Time Based Season Charging Response : Season Status";
BA_ "VNSigAllNodes" SG_ 2158149632 HVBTBSCR_SsnStat 1;
BA_ "GenSigSendType" SG_ 2158149632 HVBTBSCR_SsnSlctStat 10;
BA_ "GenSigSendOnInit" SG_ 2158149632 HVBTBSCR_SsnSlctStat 1;
BA_ "VNSigInfotainment" SG_ 2158149632 HVBTBSCR_SsnSlctStat 1;
BA_ "SignalType" SG_ 2158149632 HVBTBSCR_SsnSlctStat "ENM";
BA_ "PacketOrder" SG_ 2158149632 HVBTBSCR_SsnSlctStat 2;
BA_ "SignalLongName" SG_ 2158149632 HVBTBSCR_SsnSlctStat "High Voltage Battery Time Based Season Charging Response : Season Selected Status";
BA_ "VNSigAllNodes" SG_ 2158149632 HVBTBSCR_SsnSlctStat 1;
BA_ "GenSigSendType" SG_ 2158149632 HVBTBSCR_SsnMthStat 10;
BA_ "GenSigSendOnInit" SG_ 2158149632 HVBTBSCR_SsnMthStat 1;
BA_ "VNSigInfotainment" SG_ 2158149632 HVBTBSCR_SsnMthStat 1;
BA_ "SignalType" SG_ 2158149632 HVBTBSCR_SsnMthStat "ENM";
BA_ "PacketOrder" SG_ 2158149632 HVBTBSCR_SsnMthStat 3;
BA_ "SignalLongName" SG_ 2158149632 HVBTBSCR_SsnMthStat "High Voltage Battery Time Based Season Charging Response : Season Month Status";
BA_ "VNSigAllNodes" SG_ 2158149632 HVBTBSCR_SsnMthStat 1;
BA_ "GenSigSendType" SG_ 2158149632 HVBatTmBsChrgStRsp 10;
BA_ "GenSigSendOnInit" SG_ 2158149632 HVBatTmBsChrgStRsp 1;
BA_ "VNSigInfotainment" SG_ 2158149632 HVBatTmBsChrgStRsp 1;
BA_ "SignalType" SG_ 2158149632 HVBatTmBsChrgStRsp "ENM";
BA_ "SignalLongName" SG_ 2158149632 HVBatTmBsChrgStRsp "High Voltage Battery Time Based Charging Status Response";
BA_ "VNSigAllNodes" SG_ 2158149632 HVBatTmBsChrgStRsp 1;
BA_ "GenSigSendType" SG_ 2158149632 HVBTBCRS_ChRtDStat 10;
BA_ "GenSigSendOnInit" SG_ 2158149632 HVBTBCRS_ChRtDStat 1;
BA_ "VNSigInfotainment" SG_ 2158149632 HVBTBCRS_ChRtDStat 1;
BA_ "SignalType" SG_ 2158149632 HVBTBCRS_ChRtDStat "ENM";
BA_ "PacketOrder" SG_ 2158149632 HVBTBCRS_ChRtDStat 2;
BA_ "SignalLongName" SG_ 2158149632 HVBTBCRS_ChRtDStat "High Voltage Battery Time Based Charge Rate Response : Charge Rate Day Status";
BA_ "VNSigAllNodes" SG_ 2158149632 HVBTBCRS_ChRtDStat 1;
BA_ "GenSigSendType" SG_ 2158149632 HVBTBCRS_ChRtSlctStat 10;
BA_ "GenSigSendOnInit" SG_ 2158149632 HVBTBCRS_ChRtSlctStat 1;
BA_ "VNSigInfotainment" SG_ 2158149632 HVBTBCRS_ChRtSlctStat 1;
BA_ "SignalType" SG_ 2158149632 HVBTBCRS_ChRtSlctStat "ENM";
BA_ "PacketOrder" SG_ 2158149632 HVBTBCRS_ChRtSlctStat 3;
BA_ "SignalLongName" SG_ 2158149632 HVBTBCRS_ChRtSlctStat "High Voltage Battery Time Based Charge Rate Response : Charge Rate Selected Status";
BA_ "VNSigAllNodes" SG_ 2158149632 HVBTBCRS_ChRtSlctStat 1;
BA_ "GenSigSendType" SG_ 2158149632 HVBTBCRS_ChRtEnblStat 10;
BA_ "GenSigSendOnInit" SG_ 2158149632 HVBTBCRS_ChRtEnblStat 1;
BA_ "VNSigInfotainment" SG_ 2158149632 HVBTBCRS_ChRtEnblStat 1;
BA_ "SignalType" SG_ 2158149632 HVBTBCRS_ChRtEnblStat "ENM";
BA_ "PacketOrder" SG_ 2158149632 HVBTBCRS_ChRtEnblStat 1;
BA_ "SignalLongName" SG_ 2158149632 HVBTBCRS_ChRtEnblStat "High Voltage Battery Time Based Charge Rate Response : Charge Rate Enable Status";
BA_ "VNSigAllNodes" SG_ 2158149632 HVBTBCRS_ChRtEnblStat 1;
BA_ "GenSigSendType" SG_ 2158149632 HVBatCrgDspStat 10;
BA_ "VNSigInfotainment" SG_ 2158149632 HVBatCrgDspStat 1;
BA_ "SignalType" SG_ 2158149632 HVBatCrgDspStat "ENM";
BA_ "SignalLongName" SG_ 2158149632 HVBatCrgDspStat "High Voltage Battery Charge Display Status";
BA_ "VNSigAllNodes" SG_ 2158149632 HVBatCrgDspStat 1;
BA_ "GenSigDeltaValue" SG_ 2158149632 EgyCnsHstGphInsEgyCns 1;
BA_ "GenSigSendType" SG_ 2158149632 EgyCnsHstGphInsEgyCns 12;
BA_ "VNSigInfotainment" SG_ 2158149632 EgyCnsHstGphInsEgyCns 1;
BA_ "SignalType" SG_ 2158149632 EgyCnsHstGphInsEgyCns "UNM";
BA_ "SignalLongName" SG_ 2158149632 EgyCnsHstGphInsEgyCns "Energy Consumption History Graph Instantaneous Energy Consumption";
BA_ "VNSigAllNodes" SG_ 2158149632 EgyCnsHstGphInsEgyCns 1;
BA_ "SignalType" SG_ 2150432768 CbnHtrWrmUpIO "BLN";
BA_ "SignalLongName" SG_ 2150432768 CbnHtrWrmUpIO "Cabin Heater Warm Up Indication On";
BA_ "VNSigAllNodes" SG_ 2150432768 CbnHtrWrmUpIO 1;
BA_ "SignalType" SG_ 2150432768 EngManfldAirTempCrtdV "ENM";
BA_ "SignalLongName" SG_ 2150432768 EngManfldAirTempCrtdV "Engine Manifold Air Temperature Corrected Validity";
BA_ "VNSigAllNodes" SG_ 2150432768 EngManfldAirTempCrtdV 1;
BA_ "SignalType" SG_ 2150432768 GrdBrkgAct "BLN";
BA_ "SignalLongName" SG_ 2150432768 GrdBrkgAct "Grade Braking Active";
BA_ "VNSigAllNodes" SG_ 2150432768 GrdBrkgAct 1;
BA_ "SignalType" SG_ 2150432768 EngManfldAirTempCrtd "UNM";
BA_ "SignalLongName" SG_ 2150432768 EngManfldAirTempCrtd "Engine Manifold Air Temperature Corrected";
BA_ "VNSigAllNodes" SG_ 2150432768 EngManfldAirTempCrtd 1;
BA_ "SignalType" SG_ 2150432768 FuelFltLifRstPerf "BLN";
BA_ "SignalLongName" SG_ 2150432768 FuelFltLifRstPerf "Fuel Filter Life Reset Performed";
BA_ "VNSigAllNodes" SG_ 2150432768 FuelFltLifRstPerf 1;
BA_ "SignalType" SG_ 2150432768 FuelFltRmnLf "UNM";
BA_ "SignalLongName" SG_ 2150432768 FuelFltRmnLf "Fuel Filter Remaining Life";
BA_ "VNSigAllNodes" SG_ 2150432768 FuelFltRmnLf 1;
BA_ "SignalType" SG_ 2150432768 EngShtdwnPndgIO "BLN";
BA_ "SignalLongName" SG_ 2150432768 EngShtdwnPndgIO "Engine Shutdown Pending Indication On";
BA_ "VNSigAllNodes" SG_ 2150432768 EngShtdwnPndgIO 1;
BA_ "SignalType" SG_ 2150432768 GenFldDutCycV "ENM";
BA_ "SignalLongName" SG_ 2150432768 GenFldDutCycV "Generator Field Duty Cycle Validity";
BA_ "VNSigAllNodes" SG_ 2150432768 GenFldDutCycV 1;
BA_ "SignalType" SG_ 2150432768 GenFldDutCyc "UNM";
BA_ "SignalLongName" SG_ 2150432768 GenFldDutCyc "Generator Field Duty Cycle";
BA_ "VNSigAllNodes" SG_ 2150432768 GenFldDutCyc 1;
BA_ "GenSigSendOnInit" SG_ 2150432768 FuelTotCap 1;
BA_ "SignalType" SG_ 2150432768 FuelTotCap "UNM";
BA_ "SignalLongName" SG_ 2150432768 FuelTotCap "Fuel Total Capacity";
BA_ "VNSigAllNodes" SG_ 2150432768 FuelTotCap 1;
BA_ "SignalType" SG_ 2150432768 TransOilTempSensPres "BLN";
BA_ "SignalLongName" SG_ 2150432768 TransOilTempSensPres "Transmission Oil Temperature Sensor Present";
BA_ "VNSigAllNodes" SG_ 2150432768 TransOilTempSensPres 1;
BA_ "SignalType" SG_ 2150432768 TrnsNEmsRltMalfActv "BLN";
BA_ "SignalLongName" SG_ 2150432768 TrnsNEmsRltMalfActv "Transmission Non Emissions Related Malfunction Active";
BA_ "VNSigAllNodes" SG_ 2150432768 TrnsNEmsRltMalfActv 1;
BA_ "SignalType" SG_ 2150432768 TrnEmsMlfAtv "BLN";
BA_ "SignalLongName" SG_ 2150432768 TrnEmsMlfAtv "Transmission Emissions Related Malfunction Active";
BA_ "VNSigAllNodes" SG_ 2150432768 TrnEmsMlfAtv 1;
BA_ "SignalType" SG_ 2150432768 EngOilRmnLf "UNM";
BA_ "SignalLongName" SG_ 2150432768 EngOilRmnLf "Engine Oil Remaining Life";
BA_ "VNSigAllNodes" SG_ 2150432768 EngOilRmnLf 1;
BA_ "SignalType" SG_ 2150432768 TrnsThrmlMngmntStat "ENM";
BA_ "SignalLongName" SG_ 2150432768 TrnsThrmlMngmntStat "Transmission Thermal Management Status";
BA_ "VNSigAllNodes" SG_ 2150432768 TrnsThrmlMngmntStat 1;
BA_ "SignalType" SG_ 2150432768 PTHiElecLdReqd "BLN";
BA_ "SignalLongName" SG_ 2150432768 PTHiElecLdReqd "Powertrain High Electrical Load Requested";
BA_ "VNSigAllNodes" SG_ 2150432768 PTHiElecLdReqd 1;
BA_ "GenSigSendType" SG_ 2155413504 TireLRIPrsV 10;
BA_ "SignalType" SG_ 2155413504 TireLRIPrsV "ENM";
BA_ "SignalLongName" SG_ 2155413504 TireLRIPrsV "Tire Left Rear Inner Pressure Validity";
BA_ "VNSigAllNodes" SG_ 2155413504 TireLRIPrsV 1;
BA_ "GenSigSendType" SG_ 2155413504 TireLRIPrsStat 10;
BA_ "SignalType" SG_ 2155413504 TireLRIPrsStat "ENM";
BA_ "SignalLongName" SG_ 2155413504 TireLRIPrsStat "Tire Left Rear Inner Pressure Status";
BA_ "VNSigAllNodes" SG_ 2155413504 TireLRIPrsStat 1;
BA_ "GenSigDeltaValue" SG_ 2155413504 TireLRIPrs 1;
BA_ "GenSigSendType" SG_ 2155413504 TireLRIPrs 12;
BA_ "SignalType" SG_ 2155413504 TireLRIPrs "UNM";
BA_ "SignalLongName" SG_ 2155413504 TireLRIPrs "Tire Left Rear Inner Pressure";
BA_ "GenSigStartValue" SG_ 2155413504 TireLRIPrs 255;
BA_ "VNSigAllNodes" SG_ 2155413504 TireLRIPrs 1;
BA_ "GenSigSendType" SG_ 2155413504 TireRRIPrsV 10;
BA_ "SignalType" SG_ 2155413504 TireRRIPrsV "ENM";
BA_ "SignalLongName" SG_ 2155413504 TireRRIPrsV "Tire Right Rear Inner Pressure Validity";
BA_ "VNSigAllNodes" SG_ 2155413504 TireRRIPrsV 1;
BA_ "GenSigSendType" SG_ 2155413504 TireRRIPrsStat 10;
BA_ "SignalType" SG_ 2155413504 TireRRIPrsStat "ENM";
BA_ "SignalLongName" SG_ 2155413504 TireRRIPrsStat "Tire Right Rear Inner Pressure Status";
BA_ "VNSigAllNodes" SG_ 2155413504 TireRRIPrsStat 1;
BA_ "GenSigDeltaValue" SG_ 2155413504 TireRRIPrs 1;
BA_ "GenSigSendType" SG_ 2155413504 TireRRIPrs 12;
BA_ "SignalType" SG_ 2155413504 TireRRIPrs "UNM";
BA_ "SignalLongName" SG_ 2155413504 TireRRIPrs "Tire Right Rear Inner Pressure";
BA_ "GenSigStartValue" SG_ 2155413504 TireRRIPrs 255;
BA_ "VNSigAllNodes" SG_ 2155413504 TireRRIPrs 1;
BA_ "GenSigSendType" SG_ 2155413504 PsvLckngReqd 10;
BA_ "SignalType" SG_ 2155413504 PsvLckngReqd "BLN";
BA_ "SignalLongName" SG_ 2155413504 PsvLckngReqd "Passive Locking Requested";
BA_ "VNSigAllNodes" SG_ 2155413504 PsvLckngReqd 1;
BA_ "GenSigDeltaValue" SG_ 2155413504 PsvApprchVehId 1;
BA_ "GenSigSendType" SG_ 2155413504 PsvApprchVehId 12;
BA_ "SignalType" SG_ 2155413504 PsvApprchVehId "UNM";
BA_ "SignalLongName" SG_ 2155413504 PsvApprchVehId "Passive Approach Vehicle Identifier";
BA_ "VNSigAllNodes" SG_ 2155413504 PsvApprchVehId 1;
BA_ "GenSigSendType" SG_ 2155413504 DrvrDrKeyCylUlkSwAct 10;
BA_ "SignalType" SG_ 2155413504 DrvrDrKeyCylUlkSwAct "BLN";
BA_ "SignalLongName" SG_ 2155413504 DrvrDrKeyCylUlkSwAct "Driver Door Key Cylinder Unlock Switch Active";
BA_ "VNSigAllNodes" SG_ 2155413504 DrvrDrKeyCylUlkSwAct 1;
BA_ "GenSigSendType" SG_ 2155413504 DrvrDrKeyCylUlkSwActV 10;
BA_ "SignalType" SG_ 2155413504 DrvrDrKeyCylUlkSwActV "ENM";
BA_ "SignalLongName" SG_ 2155413504 DrvrDrKeyCylUlkSwActV "Driver Door Key Cylinder Unlock Switch Active Validity";
BA_ "VNSigAllNodes" SG_ 2155413504 DrvrDrKeyCylUlkSwActV 1;
BA_ "GenSigSendType" SG_ 2154225664 RLDrHndleSwAtv 10;
BA_ "SignalType" SG_ 2154225664 RLDrHndleSwAtv "BLN";
BA_ "SignalLongName" SG_ 2154225664 RLDrHndleSwAtv "Rear Left Door Handle Switch Active";
BA_ "VNSigAllNodes" SG_ 2154225664 RLDrHndleSwAtv 1;
BA_ "GenSigSendType" SG_ 2154225664 RRDrHndleSwAtv 10;
BA_ "SignalType" SG_ 2154225664 RRDrHndleSwAtv "BLN";
BA_ "SignalLongName" SG_ 2154225664 RRDrHndleSwAtv "Rear Right Door Handle Switch Active";
BA_ "VNSigAllNodes" SG_ 2154225664 RRDrHndleSwAtv 1;
BA_ "GenSigSendType" SG_ 2154225664 RCHndleSwAtv 10;
BA_ "SignalType" SG_ 2154225664 RCHndleSwAtv "BLN";
BA_ "SignalLongName" SG_ 2154225664 RCHndleSwAtv "Rear Closure Handle Switch Active";
BA_ "VNSigAllNodes" SG_ 2154225664 RCHndleSwAtv 1;
BA_ "GenSigSendType" SG_ 2154225664 PasDrHndleSwAtv 10;
BA_ "SignalType" SG_ 2154225664 PasDrHndleSwAtv "BLN";
BA_ "SignalLongName" SG_ 2154225664 PasDrHndleSwAtv "Passenger Door Handle Switch Active";
BA_ "VNSigAllNodes" SG_ 2154225664 PasDrHndleSwAtv 1;
BA_ "GenSigSendType" SG_ 2154225664 DrvDrHndleSwAtv 10;
BA_ "SignalType" SG_ 2154225664 DrvDrHndleSwAtv "BLN";
BA_ "SignalLongName" SG_ 2154225664 DrvDrHndleSwAtv "Driver Door Handle Switch Active";
BA_ "VNSigAllNodes" SG_ 2154225664 DrvDrHndleSwAtv 1;
BA_ "SignalType" SG_ 2151481344 HdUpDsplyUnblIO "BLN";
BA_ "SignalLongName" SG_ 2151481344 HdUpDsplyUnblIO "Head Up Display Unavailable Indication On";
BA_ "VNSigAllNodes" SG_ 2151481344 HdUpDsplyUnblIO 1;
BA_ "SignalType" SG_ 2151481344 FSRACCFrstRsmPrssIO "BLN";
BA_ "SignalLongName" SG_ 2151481344 FSRACCFrstRsmPrssIO "Full Speed Range Adaptive Cruise Control First Resume Press Indication On";
BA_ "VNSigAllNodes" SG_ 2151481344 FSRACCFrstRsmPrssIO 1;
BA_ "SignalType" SG_ 2151481344 FrtRdrBlckdIO "BLN";
BA_ "SignalLongName" SG_ 2151481344 FrtRdrBlckdIO "Front Radar Blocked Indication On";
BA_ "VNSigAllNodes" SG_ 2151481344 FrtRdrBlckdIO 1;
BA_ "SignalType" SG_ 2151481344 ShtToPrkBfExtngVehIO "BLN";
BA_ "SignalLongName" SG_ 2151481344 ShtToPrkBfExtngVehIO "Shift to Park Before Exiting Vehicle Indication On";
BA_ "VNSigAllNodes" SG_ 2151481344 ShtToPrkBfExtngVehIO 1;
BA_ "SignalType" SG_ 2151481344 AutoBrkRlsIO "BLN";
BA_ "SignalLongName" SG_ 2151481344 AutoBrkRlsIO "Autonomous Brake Release Indication On";
BA_ "VNSigAllNodes" SG_ 2151481344 AutoBrkRlsIO 1;
BA_ "GenSigSendType" SG_ 2153381888 VltActRrAccUnavlIO 10;
BA_ "SignalType" SG_ 2153381888 VltActRrAccUnavlIO "BLN";
BA_ "SignalLongName" SG_ 2153381888 VltActRrAccUnavlIO "Valet Active Rear Access Unavailable Indication On";
BA_ "VNSigAllNodes" SG_ 2153381888 VltActRrAccUnavlIO 1;
BA_ "GenSigSendType" SG_ 2153381888 PwrLftgtMotStat 10;
BA_ "SignalType" SG_ 2153381888 PwrLftgtMotStat "ENM";
BA_ "SignalLongName" SG_ 2153381888 PwrLftgtMotStat "Power Liftgate Motion Status";
BA_ "VNSigAllNodes" SG_ 2153381888 PwrLftgtMotStat 1;
BA_ "GenSigSendType" SG_ 2153381888 GrgPrgMdCmpl 10;
BA_ "GenSigSendOnInit" SG_ 2153381888 GrgPrgMdCmpl 1;
BA_ "SignalType" SG_ 2153381888 GrgPrgMdCmpl "BLN";
BA_ "SignalLongName" SG_ 2153381888 GrgPrgMdCmpl "Garage Programming Mode Complete";
BA_ "VNSigAllNodes" SG_ 2153381888 GrgPrgMdCmpl 1;
BA_ "GenSigDeltaValue" SG_ 2153381888 VehIncAngEst 1;
BA_ "GenSigSendType" SG_ 2153381888 VehIncAngEst 12;
BA_ "SignalType" SG_ 2153381888 VehIncAngEst "UNM";
BA_ "SignalLongName" SG_ 2153381888 VehIncAngEst "Vehicle Inclination Angle Estimated";
BA_ "VNSigAllNodes" SG_ 2153381888 VehIncAngEst 1;
BA_ "GenSigSendType" SG_ 2153381888 PwrLftgtInclAngV 10;
BA_ "GenSigSendOnInit" SG_ 2153381888 PwrLftgtInclAngV 1;
BA_ "VNSigParkedVehicle" SG_ 2153381888 PwrLftgtInclAngV 1;
BA_ "SignalType" SG_ 2153381888 PwrLftgtInclAngV "ENM";
BA_ "SignalLongName" SG_ 2153381888 PwrLftgtInclAngV "Power Liftgate Inclination Angle Validity";
BA_ "VNSigAllNodes" SG_ 2153381888 PwrLftgtInclAngV 1;
BA_ "GenSigSendType" SG_ 2153381888 RrClsrObstclDtctd 10;
BA_ "GenSigSendOnInit" SG_ 2153381888 RrClsrObstclDtctd 1;
BA_ "SignalType" SG_ 2153381888 RrClsrObstclDtctd "BLN";
BA_ "SignalLongName" SG_ 2153381888 RrClsrObstclDtctd "Rear Closure Obstacle Detected";
BA_ "VNSigAllNodes" SG_ 2153381888 RrClsrObstclDtctd 1;
BA_ "GenSigSendType" SG_ 2153381888 FnshRrClsrMtnBfrDrvIO 10;
BA_ "GenSigSendOnInit" SG_ 2153381888 FnshRrClsrMtnBfrDrvIO 1;
BA_ "SignalType" SG_ 2153381888 FnshRrClsrMtnBfrDrvIO "BLN";
BA_ "SignalLongName" SG_ 2153381888 FnshRrClsrMtnBfrDrvIO "Finish Rear Closure Motion Before Driving Indication On";
BA_ "VNSigAllNodes" SG_ 2153381888 FnshRrClsrMtnBfrDrvIO 1;
BA_ "GenSigDeltaValue" SG_ 2153381888 PwrLftgtInclAng 1;
BA_ "GenSigSendType" SG_ 2153381888 PwrLftgtInclAng 12;
BA_ "GenSigSendOnInit" SG_ 2153381888 PwrLftgtInclAng 1;
BA_ "VNSigParkedVehicle" SG_ 2153381888 PwrLftgtInclAng 1;
BA_ "SignalType" SG_ 2153381888 PwrLftgtInclAng "UNM";
BA_ "SignalLongName" SG_ 2153381888 PwrLftgtInclAng "Power Liftgate Inclination Angle";
BA_ "VNSigAllNodes" SG_ 2153381888 PwrLftgtInclAng 1;
BA_ "GenSigSendType" SG_ 2153381888 RrClosOpenSwAct 10;
BA_ "GenSigSendOnInit" SG_ 2153381888 RrClosOpenSwAct 1;
BA_ "SignalType" SG_ 2153381888 RrClosOpenSwAct "BLN";
BA_ "SignalLongName" SG_ 2153381888 RrClosOpenSwAct "Rear Closure Open Switch Active";
BA_ "VNSigAllNodes" SG_ 2153381888 RrClosOpenSwAct 1;
BA_ "GenSigSendType" SG_ 2153381888 RrClosOpenSwActV 10;
BA_ "SignalType" SG_ 2153381888 RrClosOpenSwActV "ENM";
BA_ "SignalLongName" SG_ 2153381888 RrClosOpenSwActV "Rear Closure Open Switch Active Validity";
BA_ "VNSigAllNodes" SG_ 2153381888 RrClosOpenSwActV 1;
BA_ "GenSigSendType" SG_ 2153381888 RrClsrInMtn 10;
BA_ "GenSigSendOnInit" SG_ 2153381888 RrClsrInMtn 1;
BA_ "SignalType" SG_ 2153381888 RrClsrInMtn "BLN";
BA_ "SignalLongName" SG_ 2153381888 RrClsrInMtn "Rear Closure In Motion";
BA_ "VNSigAllNodes" SG_ 2153381888 RrClsrInMtn 1;
BA_ "GenSigSendType" SG_ 2153381888 RrWprInhbRq 10;
BA_ "SignalType" SG_ 2153381888 RrWprInhbRq "BLN";
BA_ "SignalLongName" SG_ 2153381888 RrWprInhbRq "Rear Wiper Inhibit Request";
BA_ "VNSigAllNodes" SG_ 2153381888 RrWprInhbRq 1;
BA_ "GenSigSendType" SG_ 2153979904 RtPrkLtFld 10;
BA_ "GenSigSendOnInit" SG_ 2153979904 RtPrkLtFld 1;
BA_ "SignalType" SG_ 2153979904 RtPrkLtFld "BLN";
BA_ "SignalLongName" SG_ 2153979904 RtPrkLtFld "Right Park Light Failed";
BA_ "VNSigAllNodes" SG_ 2153979904 RtPrkLtFld 1;
BA_ "GenSigSendType" SG_ 2153979904 RtLwBmFld 10;
BA_ "GenSigSendOnInit" SG_ 2153979904 RtLwBmFld 1;
BA_ "SignalType" SG_ 2153979904 RtLwBmFld "BLN";
BA_ "SignalLongName" SG_ 2153979904 RtLwBmFld "Right Low Beam Failed";
BA_ "VNSigAllNodes" SG_ 2153979904 RtLwBmFld 1;
BA_ "GenSigSendType" SG_ 2153979904 RtDytmRunLmpFld 10;
BA_ "GenSigSendOnInit" SG_ 2153979904 RtDytmRunLmpFld 1;
BA_ "SignalType" SG_ 2153979904 RtDytmRunLmpFld "BLN";
BA_ "SignalLongName" SG_ 2153979904 RtDytmRunLmpFld "Right Daytime Running Lamp Failed";
BA_ "VNSigAllNodes" SG_ 2153979904 RtDytmRunLmpFld 1;
BA_ "GenSigSendType" SG_ 2153979904 RtBrkLtFld 10;
BA_ "GenSigSendOnInit" SG_ 2153979904 RtBrkLtFld 1;
BA_ "SignalType" SG_ 2153979904 RtBrkLtFld "BLN";
BA_ "SignalLongName" SG_ 2153979904 RtBrkLtFld "Right Brake Light Failed";
BA_ "VNSigAllNodes" SG_ 2153979904 RtBrkLtFld 1;
BA_ "GenSigSendType" SG_ 2153979904 RRTrnIndLtFld 10;
BA_ "GenSigSendOnInit" SG_ 2153979904 RRTrnIndLtFld 1;
BA_ "SignalType" SG_ 2153979904 RRTrnIndLtFld "BLN";
BA_ "SignalLongName" SG_ 2153979904 RRTrnIndLtFld "Rear Right Turn Indicator Light Failed";
BA_ "VNSigAllNodes" SG_ 2153979904 RRTrnIndLtFld 1;
BA_ "GenSigSendType" SG_ 2153979904 RLTrnIndLtFld 10;
BA_ "GenSigSendOnInit" SG_ 2153979904 RLTrnIndLtFld 1;
BA_ "SignalType" SG_ 2153979904 RLTrnIndLtFld "BLN";
BA_ "SignalLongName" SG_ 2153979904 RLTrnIndLtFld "Rear Left Turn Indicator Light Failed";
BA_ "VNSigAllNodes" SG_ 2153979904 RLTrnIndLtFld 1;
BA_ "GenSigSendType" SG_ 2153979904 LicPltLtFld 10;
BA_ "GenSigSendOnInit" SG_ 2153979904 LicPltLtFld 1;
BA_ "SignalType" SG_ 2153979904 LicPltLtFld "BLN";
BA_ "SignalLongName" SG_ 2153979904 LicPltLtFld "License Plate Light Failed";
BA_ "VNSigAllNodes" SG_ 2153979904 LicPltLtFld 1;
BA_ "GenSigSendType" SG_ 2153979904 LftPrkLtFld 10;
BA_ "GenSigSendOnInit" SG_ 2153979904 LftPrkLtFld 1;
BA_ "SignalType" SG_ 2153979904 LftPrkLtFld "BLN";
BA_ "SignalLongName" SG_ 2153979904 LftPrkLtFld "Left Park Light Failed";
BA_ "VNSigAllNodes" SG_ 2153979904 LftPrkLtFld 1;
BA_ "GenSigSendType" SG_ 2153979904 LftLwBmFld 10;
BA_ "GenSigSendOnInit" SG_ 2153979904 LftLwBmFld 1;
BA_ "SignalType" SG_ 2153979904 LftLwBmFld "BLN";
BA_ "SignalLongName" SG_ 2153979904 LftLwBmFld "Left Low Beam Failed";
BA_ "VNSigAllNodes" SG_ 2153979904 LftLwBmFld 1;
BA_ "GenSigSendType" SG_ 2153979904 LftBrkLtFld 10;
BA_ "GenSigSendOnInit" SG_ 2153979904 LftBrkLtFld 1;
BA_ "SignalType" SG_ 2153979904 LftBrkLtFld "BLN";
BA_ "SignalLongName" SG_ 2153979904 LftBrkLtFld "Left Brake Light Failed";
BA_ "VNSigAllNodes" SG_ 2153979904 LftBrkLtFld 1;
BA_ "GenSigSendType" SG_ 2153979904 FRTrnIndLtFld 10;
BA_ "GenSigSendOnInit" SG_ 2153979904 FRTrnIndLtFld 1;
BA_ "SignalType" SG_ 2153979904 FRTrnIndLtFld "BLN";
BA_ "SignalLongName" SG_ 2153979904 FRTrnIndLtFld "Front Right Turn Indicator Light Failed";
BA_ "VNSigAllNodes" SG_ 2153979904 FRTrnIndLtFld 1;
BA_ "GenSigSendType" SG_ 2153979904 FLTrnIndLtFld 10;
BA_ "GenSigSendOnInit" SG_ 2153979904 FLTrnIndLtFld 1;
BA_ "SignalType" SG_ 2153979904 FLTrnIndLtFld "BLN";
BA_ "SignalLongName" SG_ 2153979904 FLTrnIndLtFld "Front Left Turn Indicator Light Failed";
BA_ "VNSigAllNodes" SG_ 2153979904 FLTrnIndLtFld 1;
BA_ "GenSigSendType" SG_ 2153979904 CHMSLFld 10;
BA_ "GenSigSendOnInit" SG_ 2153979904 CHMSLFld 1;
BA_ "SignalType" SG_ 2153979904 CHMSLFld "BLN";
BA_ "SignalLongName" SG_ 2153979904 CHMSLFld "Center High Mounted Stop Light Failed";
BA_ "VNSigAllNodes" SG_ 2153979904 CHMSLFld 1;
BA_ "GenSigSendType" SG_ 2153979904 LftDytmRunLmpFld 10;
BA_ "GenSigSendOnInit" SG_ 2153979904 LftDytmRunLmpFld 1;
BA_ "SignalType" SG_ 2153979904 LftDytmRunLmpFld "BLN";
BA_ "SignalLongName" SG_ 2153979904 LftDytmRunLmpFld "Left Daytime Running Lamp Failed";
BA_ "VNSigAllNodes" SG_ 2153979904 LftDytmRunLmpFld 1;
BA_ "GenSigSendType" SG_ 2153979904 RvsLtFld 10;
BA_ "GenSigSendOnInit" SG_ 2153979904 RvsLtFld 1;
BA_ "SignalType" SG_ 2153979904 RvsLtFld "BLN";
BA_ "SignalLongName" SG_ 2153979904 RvsLtFld "Reverse Light Failed";
BA_ "VNSigAllNodes" SG_ 2153979904 RvsLtFld 1;
BA_ "GenSigSendType" SG_ 2153979904 RFgLtFld 10;
BA_ "GenSigSendOnInit" SG_ 2153979904 RFgLtFld 1;
BA_ "SignalType" SG_ 2153979904 RFgLtFld "BLN";
BA_ "SignalLongName" SG_ 2153979904 RFgLtFld "Rear Fog Light Failed";
BA_ "VNSigAllNodes" SG_ 2153979904 RFgLtFld 1;
BA_ "GenSigDeltaValue" SG_ 2149908480 BrkPdlPos 1;
BA_ "GenSigSendType" SG_ 2149908480 BrkPdlPos 12;
BA_ "GenSigSendOnInit" SG_ 2149908480 BrkPdlPos 1;
BA_ "SignalType" SG_ 2149908480 BrkPdlPos "UNM";
BA_ "SignalLongName" SG_ 2149908480 BrkPdlPos "Brake Pedal Position";
BA_ "VNSigAllNodes" SG_ 2149908480 BrkPdlPos 1;
BA_ "GenSigSendType" SG_ 2149908480 BrkPedTrvlAchvd 10;
BA_ "SignalType" SG_ 2149908480 BrkPedTrvlAchvd "BLN";
BA_ "PacketOrder" SG_ 2149908480 BrkPedTrvlAchvd 1;
BA_ "SignalLongName" SG_ 2149908480 BrkPedTrvlAchvd "Brake Pedal Initial Travel Achieved Status : Brake Pedal Initial Travel Achieved";
BA_ "VNSigAllNodes" SG_ 2149908480 BrkPedTrvlAchvd 1;
BA_ "GenSigSendType" SG_ 2149908480 BrkPedTrvlAchvdV 10;
BA_ "SignalType" SG_ 2149908480 BrkPedTrvlAchvdV "ENM";
BA_ "PacketOrder" SG_ 2149908480 BrkPedTrvlAchvdV 2;
BA_ "SignalLongName" SG_ 2149908480 BrkPedTrvlAchvdV "Brake Pedal Initial Travel Achieved Status : Brake Pedal Initial Travel Achieved Validity";
BA_ "VNSigAllNodes" SG_ 2149908480 BrkPedTrvlAchvdV 1;
BA_ "GenSigSendType" SG_ 2149908480 BrkPdlModTrvlV 10;
BA_ "SignalType" SG_ 2149908480 BrkPdlModTrvlV "ENM";
BA_ "SignalLongName" SG_ 2149908480 BrkPdlModTrvlV "Brake Pedal Moderate Travel Achieved Validity";
BA_ "VNSigAllNodes" SG_ 2149908480 BrkPdlModTrvlV 1;
BA_ "GenSigSendType" SG_ 2149908480 BrkPdlModTrvl 10;
BA_ "SignalType" SG_ 2149908480 BrkPdlModTrvl "BLN";
BA_ "SignalLongName" SG_ 2149908480 BrkPdlModTrvl "Brake Pedal Moderate Travel Achieved";
BA_ "VNSigAllNodes" SG_ 2149908480 BrkPdlModTrvl 1;
BA_ "GenSigSendType" SG_ 2154643456 HtrCoreInltClntTmpCalcV 10;
BA_ "SignalType" SG_ 2154643456 HtrCoreInltClntTmpCalcV "ENM";
BA_ "SignalLongName" SG_ 2154643456 HtrCoreInltClntTmpCalcV "Heater Core Inlet Coolant Temperature Calculated Validity";
BA_ "VNSigAllNodes" SG_ 2154643456 HtrCoreInltClntTmpCalcV 1;
BA_ "GenSigDeltaValue" SG_ 2154643456 HtrCoreInltClntTmpCalc 1;
BA_ "GenSigSendType" SG_ 2154643456 HtrCoreInltClntTmpCalc 12;
BA_ "SignalType" SG_ 2154643456 HtrCoreInltClntTmpCalc "UNM";
BA_ "SignalLongName" SG_ 2154643456 HtrCoreInltClntTmpCalc "Heater Core Inlet Coolant Temperature Calculated";
BA_ "VNSigAllNodes" SG_ 2154643456 HtrCoreInltClntTmpCalc 1;
BA_ "GenSigSendType" SG_ 2154643456 AuxHtrAtv 10;
BA_ "SignalType" SG_ 2154643456 AuxHtrAtv "BLN";
BA_ "SignalLongName" SG_ 2154643456 AuxHtrAtv "Auxiliary Heater Active";
BA_ "VNSigAllNodes" SG_ 2154643456 AuxHtrAtv 1;
BA_ "GenSigSendType" SG_ 2151186432 CtLghtDet 10;
BA_ "GenSigSendOnInit" SG_ 2151186432 CtLghtDet 2;
BA_ "SignalType" SG_ 2151186432 CtLghtDet "BLN";
BA_ "SignalLongName" SG_ 2151186432 CtLghtDet "City Light Detected";
BA_ "VNSigAllNodes" SG_ 2151186432 CtLghtDet 1;
BA_ "GenSigSendType" SG_ 2151186432 AutoHgBmCtrlInOn 10;
BA_ "SignalType" SG_ 2151186432 AutoHgBmCtrlInOn "BLN";
BA_ "SignalLongName" SG_ 2151186432 AutoHgBmCtrlInOn "Auto High Beam Control Indication On";
BA_ "VNSigAllNodes" SG_ 2151186432 AutoHgBmCtrlInOn 1;
BA_ "GenSigSendType" SG_ 2151186432 AutoBmSlctStat 10;
BA_ "GenSigSendOnInit" SG_ 2151186432 AutoBmSlctStat 2;
BA_ "SignalType" SG_ 2151186432 AutoBmSlctStat "ENM";
BA_ "SignalLongName" SG_ 2151186432 AutoBmSlctStat "Automatic Beam Select Status";
BA_ "VNSigAllNodes" SG_ 2151186432 AutoBmSlctStat 1;
BA_ "SignalType" SG_ 2150498304 OAT_PT_EstV "ENM";
BA_ "SignalLongName" SG_ 2150498304 OAT_PT_EstV "Outside Air Temperature Powertrain Estimated Validity";
BA_ "VNSigAllNodes" SG_ 2150498304 OAT_PT_EstV 1;
BA_ "SignalType" SG_ 2150498304 EngOilPrsV "ENM";
BA_ "SignalLongName" SG_ 2150498304 EngOilPrsV "Engine Oil Pressure Validity";
BA_ "VNSigAllNodes" SG_ 2150498304 EngOilPrsV 1;
BA_ "SignalType" SG_ 2150498304 EngOilPrs "UNM";
BA_ "SignalLongName" SG_ 2150498304 EngOilPrs "Engine Oil Pressure";
BA_ "VNSigAllNodes" SG_ 2150498304 EngOilPrs 1;
BA_ "SignalType" SG_ 2150498304 EngOilTmpV "ENM";
BA_ "SignalLongName" SG_ 2150498304 EngOilTmpV "Engine Oil Temperature Validity";
BA_ "VNSigAllNodes" SG_ 2150498304 EngOilTmpV 1;
BA_ "SignalType" SG_ 2150498304 EngOilTmp "UNM";
BA_ "SignalLongName" SG_ 2150498304 EngOilTmp "Engine Oil Temperature";
BA_ "VNSigAllNodes" SG_ 2150498304 EngOilTmp 1;
BA_ "SignalType" SG_ 2150498304 OAT_PT_Est "UNM";
BA_ "SignalLongName" SG_ 2150498304 OAT_PT_Est "Outside Air Temperature Powertrain Estimated";
BA_ "VNSigAllNodes" SG_ 2150498304 OAT_PT_Est 1;
BA_ "SignalType" SG_ 2150498304 TrnOilTmpV "ENM";
BA_ "SignalLongName" SG_ 2150498304 TrnOilTmpV "Transmission Oil Temperature Validity";
BA_ "VNSigAllNodes" SG_ 2150498304 TrnOilTmpV 1;
BA_ "SignalType" SG_ 2150498304 TrnOilTmp "UNM";
BA_ "SignalLongName" SG_ 2150498304 TrnOilTmp "Transmission Oil Temperature";
BA_ "VNSigAllNodes" SG_ 2150498304 TrnOilTmp 1;
BA_ "GenSigSendOnInit" SG_ 2150498304 EngCltTmpV 1;
BA_ "SignalType" SG_ 2150498304 EngCltTmpV "ENM";
BA_ "SignalLongName" SG_ 2150498304 EngCltTmpV "Engine Coolant Temperature Validity";
BA_ "VNSigAllNodes" SG_ 2150498304 EngCltTmpV 1;
BA_ "GenSigSendOnInit" SG_ 2150498304 EngCltTmp 1;
BA_ "SignalType" SG_ 2150498304 EngCltTmp "UNM";
BA_ "SignalLongName" SG_ 2150498304 EngCltTmp "Engine Coolant Temperature";
BA_ "VNSigAllNodes" SG_ 2150498304 EngCltTmp 1;
BA_ "SignalType" SG_ 2150498304 EngIntAirTmpV "ENM";
BA_ "SignalLongName" SG_ 2150498304 EngIntAirTmpV "Engine Intake Air Temperature Validity";
BA_ "VNSigAllNodes" SG_ 2150498304 EngIntAirTmpV 1;
BA_ "SignalType" SG_ 2150498304 EngIntAirTmp "UNM";
BA_ "SignalLongName" SG_ 2150498304 EngIntAirTmp "Engine Intake Air Temperature";
BA_ "VNSigAllNodes" SG_ 2150498304 EngIntAirTmp 1;
BA_ "SignalType" SG_ 2150498304 OAT_PT_EstM "ENM";
BA_ "SignalLongName" SG_ 2150498304 OAT_PT_EstM "Outside Air Temperature Powertrain Estimated Mask";
BA_ "VNSigAllNodes" SG_ 2150498304 OAT_PT_EstM 1;
BA_ "SignalType" SG_ 2150498304 BarPrsAbsV "ENM";
BA_ "SignalLongName" SG_ 2150498304 BarPrsAbsV "Barometric Pressure Absolute Validity";
BA_ "VNSigAllNodes" SG_ 2150498304 BarPrsAbsV 1;
BA_ "SignalType" SG_ 2150498304 BarPrsAbs "UNM";
BA_ "SignalLongName" SG_ 2150498304 BarPrsAbs "Barometric Pressure Absolute";
BA_ "VNSigAllNodes" SG_ 2150498304 BarPrsAbs 1;
BA_ "GenSigSendType" SG_ 2154840064 CmpsZnNvrSet 10;
BA_ "GenSigSendOnInit" SG_ 2154840064 CmpsZnNvrSet 1;
BA_ "SignalType" SG_ 2154840064 CmpsZnNvrSet "BLN";
BA_ "SignalLongName" SG_ 2154840064 CmpsZnNvrSet "Compass Zone Never Set";
BA_ "VNSigAllNodes" SG_ 2154840064 CmpsZnNvrSet 1;
BA_ "GenSigSendType" SG_ 2154840064 CmpsSatrtd 10;
BA_ "GenSigSendOnInit" SG_ 2154840064 CmpsSatrtd 1;
BA_ "SignalType" SG_ 2154840064 CmpsSatrtd "BLN";
BA_ "SignalLongName" SG_ 2154840064 CmpsSatrtd "Compass Saturated";
BA_ "VNSigAllNodes" SG_ 2154840064 CmpsSatrtd 1;
BA_ "GenSigSendType" SG_ 2154840064 CmpsDecZone 10;
BA_ "GenSigSendOnInit" SG_ 2154840064 CmpsDecZone 1;
BA_ "SignalType" SG_ 2154840064 CmpsDecZone "ENM";
BA_ "SignalLongName" SG_ 2154840064 CmpsDecZone "Compass Declination Zone";
BA_ "VNSigAllNodes" SG_ 2154840064 CmpsDecZone 1;
BA_ "GenSigSendType" SG_ 2154840064 CmpsOctHdingDataSrc 10;
BA_ "GenSigSendOnInit" SG_ 2154840064 CmpsOctHdingDataSrc 1;
BA_ "SignalType" SG_ 2154840064 CmpsOctHdingDataSrc "ENM";
BA_ "SignalLongName" SG_ 2154840064 CmpsOctHdingDataSrc "Compass Octant Heading Data Source";
BA_ "VNSigAllNodes" SG_ 2154840064 CmpsOctHdingDataSrc 1;
BA_ "GenSigSendType" SG_ 2154840064 CmpsOctHding 10;
BA_ "GenSigSendOnInit" SG_ 2154840064 CmpsOctHding 1;
BA_ "SignalType" SG_ 2154840064 CmpsOctHding "ENM";
BA_ "SignalLongName" SG_ 2154840064 CmpsOctHding "Compass Octant Heading";
BA_ "VNSigAllNodes" SG_ 2154840064 CmpsOctHding 1;
BA_ "GenSigSendType" SG_ 2154840064 CmpsModManCalInPrc 10;
BA_ "GenSigSendOnInit" SG_ 2154840064 CmpsModManCalInPrc 1;
BA_ "SignalType" SG_ 2154840064 CmpsModManCalInPrc "BLN";
BA_ "SignalLongName" SG_ 2154840064 CmpsModManCalInPrc "Compass Module Manual Calibration In Process";
BA_ "VNSigAllNodes" SG_ 2154840064 CmpsModManCalInPrc 1;
BA_ "GenSigSendType" SG_ 2154840064 CmpsModFltPrs 10;
BA_ "GenSigSendOnInit" SG_ 2154840064 CmpsModFltPrs 1;
BA_ "SignalType" SG_ 2154840064 CmpsModFltPrs "BLN";
BA_ "SignalLongName" SG_ 2154840064 CmpsModFltPrs "Compass Module Fault Present";
BA_ "VNSigAllNodes" SG_ 2154840064 CmpsModFltPrs 1;
BA_ "GenSigDeltaValue" SG_ 2154840064 CmpsCrHding 1;
BA_ "GenSigSendType" SG_ 2154840064 CmpsCrHding 12;
BA_ "GenSigSendOnInit" SG_ 2154840064 CmpsCrHding 1;
BA_ "SignalType" SG_ 2154840064 CmpsCrHding "UNM";
BA_ "SignalLongName" SG_ 2154840064 CmpsCrHding "Compass Corrected Heading";
BA_ "VNSigAllNodes" SG_ 2154840064 CmpsCrHding 1;
BA_ "GenSigDeltaValue" SG_ 2151890944 TICR_Ind1FlshRtOn 1;
BA_ "GenSigSendType" SG_ 2151890944 TICR_Ind1FlshRtOn 12;
BA_ "VNSigInfotainment" SG_ 2151890944 TICR_Ind1FlshRtOn 1;
BA_ "SignalType" SG_ 2151890944 TICR_Ind1FlshRtOn "UNM";
BA_ "PacketOrder" SG_ 2151890944 TICR_Ind1FlshRtOn 5;
BA_ "SignalLongName" SG_ 2151890944 TICR_Ind1FlshRtOn "Telematics Indication Control Request : Indicator 1 Flash Rate On";
BA_ "VNSigAllNodes" SG_ 2151890944 TICR_Ind1FlshRtOn 1;
BA_ "GenSigDeltaValue" SG_ 2151890944 TICR_Ind1FlshRtOff 1;
BA_ "GenSigSendType" SG_ 2151890944 TICR_Ind1FlshRtOff 12;
BA_ "VNSigInfotainment" SG_ 2151890944 TICR_Ind1FlshRtOff 1;
BA_ "SignalType" SG_ 2151890944 TICR_Ind1FlshRtOff "UNM";
BA_ "PacketOrder" SG_ 2151890944 TICR_Ind1FlshRtOff 4;
BA_ "SignalLongName" SG_ 2151890944 TICR_Ind1FlshRtOff "Telematics Indication Control Request : Indicator 1 Flash Rate Off";
BA_ "VNSigAllNodes" SG_ 2151890944 TICR_Ind1FlshRtOff 1;
BA_ "GenSigDeltaValue" SG_ 2151890944 TICR_Ind1Cnt 1;
BA_ "GenSigSendType" SG_ 2151890944 TICR_Ind1Cnt 12;
BA_ "VNSigInfotainment" SG_ 2151890944 TICR_Ind1Cnt 1;
BA_ "SignalType" SG_ 2151890944 TICR_Ind1Cnt "UNM";
BA_ "PacketOrder" SG_ 2151890944 TICR_Ind1Cnt 3;
BA_ "SignalLongName" SG_ 2151890944 TICR_Ind1Cnt "Telematics Indication Control Request : Indicator 1 Count";
BA_ "VNSigAllNodes" SG_ 2151890944 TICR_Ind1Cnt 1;
BA_ "GenSigSendType" SG_ 2151890944 TICR_Ind1 10;
BA_ "VNSigInfotainment" SG_ 2151890944 TICR_Ind1 1;
BA_ "SignalType" SG_ 2151890944 TICR_Ind1 "ENM";
BA_ "PacketOrder" SG_ 2151890944 TICR_Ind1 2;
BA_ "SignalLongName" SG_ 2151890944 TICR_Ind1 "Telematics Indication Control Request : Indicator 1";
BA_ "VNSigAllNodes" SG_ 2151890944 TICR_Ind1 1;
BA_ "GenSigSendType" SG_ 2151890944 TICR_Ind1Req 10;
BA_ "VNSigInfotainment" SG_ 2151890944 TICR_Ind1Req 1;
BA_ "SignalType" SG_ 2151890944 TICR_Ind1Req "ENM";
BA_ "PacketOrder" SG_ 2151890944 TICR_Ind1Req 1;
BA_ "SignalLongName" SG_ 2151890944 TICR_Ind1Req "Telematics Indication Control Request : Indication 1 Request";
BA_ "VNSigAllNodes" SG_ 2151890944 TICR_Ind1Req 1;
BA_ "SignalType" SG_ 2155896832 FuelAlcoholCompV "ENM";
BA_ "SignalLongName" SG_ 2155896832 FuelAlcoholCompV "Fuel Alcohol Composition Validity";
BA_ "VNSigAllNodes" SG_ 2155896832 FuelAlcoholCompV 1;
BA_ "SignalType" SG_ 2155896832 FuelAlchlCompAdptnPrg "BLN";
BA_ "SignalLongName" SG_ 2155896832 FuelAlchlCompAdptnPrg "Fuel Alcohol Composition Adaptation in Progress";
BA_ "VNSigAllNodes" SG_ 2155896832 FuelAlchlCompAdptnPrg 1;
BA_ "SignalType" SG_ 2155896832 FuelAlcoholComp "UNM";
BA_ "SignalLongName" SG_ 2155896832 FuelAlcoholComp "Fuel Alcohol Composition";
BA_ "VNSigAllNodes" SG_ 2155896832 FuelAlcoholComp 1;
BA_ "SignalType" SG_ 2155896832 FuelMdStat "ENM";
BA_ "SignalLongName" SG_ 2155896832 FuelMdStat "Fuel Mode Status";
BA_ "VNSigAllNodes" SG_ 2155896832 FuelMdStat 1;
BA_ "SignalType" SG_ 2155896832 FuelTotCapTnk2 "UNM";
BA_ "SignalLongName" SG_ 2155896832 FuelTotCapTnk2 "Fuel Total Capacity Tank 2";
BA_ "VNSigAllNodes" SG_ 2155896832 FuelTotCapTnk2 1;
BA_ "SignalType" SG_ 2155896832 FlLvlTank2PctV "ENM";
BA_ "SignalLongName" SG_ 2155896832 FlLvlTank2PctV "Fuel Level Tank 2 Percent Validity";
BA_ "VNSigAllNodes" SG_ 2155896832 FlLvlTank2PctV 1;
BA_ "SignalType" SG_ 2155896832 FlLvlTank2Pct "UNM";
BA_ "SignalLongName" SG_ 2155896832 FlLvlTank2Pct "Fuel Level Tank 2 Percent";
BA_ "VNSigAllNodes" SG_ 2155896832 FlLvlTank2Pct 1;
BA_ "SignalType" SG_ 2155896832 AltFuelPHeatAct "BLN";
BA_ "SignalLongName" SG_ 2155896832 AltFuelPHeatAct "Alternative Fuel Pre-heating Active";
BA_ "VNSigAllNodes" SG_ 2155896832 AltFuelPHeatAct 1;
BA_ "SignalType" SG_ 2155896832 AltFuelMdReqDndIO "BLN";
BA_ "SignalLongName" SG_ 2155896832 AltFuelMdReqDndIO "Alternative Fuel Mode Request Denied Indication On";
BA_ "VNSigAllNodes" SG_ 2155896832 AltFuelMdReqDndIO 1;
BA_ "SignalType" SG_ 2155896832 AltFuelLvlLo "BLN";
BA_ "SignalLongName" SG_ 2155896832 AltFuelLvlLo "Alternative Fuel Level Low";
BA_ "VNSigAllNodes" SG_ 2155896832 AltFuelLvlLo 1;
BA_ "SignalType" SG_ 2155896832 AltFuelAccWrnngAct "BLN";
BA_ "SignalLongName" SG_ 2155896832 AltFuelAccWrnngAct "Alternative Fuel Acceleration Warning Active";
BA_ "VNSigAllNodes" SG_ 2155896832 AltFuelAccWrnngAct 1;
BA_ "GenSigSendType" SG_ 2154496000 ShftrUnlkdBrkToShftIO 10;
BA_ "SignalType" SG_ 2154496000 ShftrUnlkdBrkToShftIO "BLN";
BA_ "SignalLongName" SG_ 2154496000 ShftrUnlkdBrkToShftIO "Shifter Unlocked Brake To Shift Indication On";
BA_ "VNSigAllNodes" SG_ 2154496000 ShftrUnlkdBrkToShftIO 1;
BA_ "GenSigSendType" SG_ 2154496000 ShftrLkdBklPsnStbltIO 10;
BA_ "SignalType" SG_ 2154496000 ShftrLkdBklPsnStbltIO "BLN";
BA_ "SignalLongName" SG_ 2154496000 ShftrLkdBklPsnStbltIO "Shifter Locked Buckle Passenger Seatbelt Indication On";
BA_ "VNSigAllNodes" SG_ 2154496000 ShftrLkdBklPsnStbltIO 1;
BA_ "GenSigSendType" SG_ 2154496000 ShftrLkdBklDrvStbltIO 10;
BA_ "SignalType" SG_ 2154496000 ShftrLkdBklDrvStbltIO "BLN";
BA_ "SignalLongName" SG_ 2154496000 ShftrLkdBklDrvStbltIO "Shifter Locked Buckle Driver Seatbelt Indication On";
BA_ "VNSigAllNodes" SG_ 2154496000 ShftrLkdBklDrvStbltIO 1;
BA_ "GenSigSendType" SG_ 2154496000 TargaTopStateV 10;
BA_ "GenSigSendOnInit" SG_ 2154496000 TargaTopStateV 2;
BA_ "SignalType" SG_ 2154496000 TargaTopStateV "ENM";
BA_ "SignalLongName" SG_ 2154496000 TargaTopStateV "Targa Top State Validity";
BA_ "VNSigAllNodes" SG_ 2154496000 TargaTopStateV 1;
BA_ "GenSigSendType" SG_ 2154496000 TargaTopState 10;
BA_ "GenSigSendOnInit" SG_ 2154496000 TargaTopState 2;
BA_ "SignalType" SG_ 2154496000 TargaTopState "ENM";
BA_ "SignalLongName" SG_ 2154496000 TargaTopState "Targa Top State";
BA_ "VNSigAllNodes" SG_ 2154496000 TargaTopState 1;
BA_ "GenSigSendType" SG_ 2154496000 CmpSftTopMotBfrOpTrnkIO 10;
BA_ "GenSigSendOnInit" SG_ 2154496000 CmpSftTopMotBfrOpTrnkIO 2;
BA_ "SignalType" SG_ 2154496000 CmpSftTopMotBfrOpTrnkIO "BLN";
BA_ "SignalLongName" SG_ 2154496000 CmpSftTopMotBfrOpTrnkIO "Complete Soft Top Motion Before Open Trunk Indication On";
BA_ "VNSigAllNodes" SG_ 2154496000 CmpSftTopMotBfrOpTrnkIO 1;
BA_ "GenSigSendType" SG_ 2154471424 RrClsrSnwLdIO 10;
BA_ "SignalType" SG_ 2154471424 RrClsrSnwLdIO "BLN";
BA_ "SignalLongName" SG_ 2154471424 RrClsrSnwLdIO "Rear Closure Snow Load Indication On";
BA_ "VNSigAllNodes" SG_ 2154471424 RrClsrSnwLdIO 1;
BA_ "GenSigSendType" SG_ 2154471424 RrClosAjarSwAct 10;
BA_ "GenSigSendOnInit" SG_ 2154471424 RrClosAjarSwAct 1;
BA_ "SignalType" SG_ 2154471424 RrClosAjarSwAct "BLN";
BA_ "SignalLongName" SG_ 2154471424 RrClosAjarSwAct "Rear Closure Ajar Switch Active";
BA_ "VNSigAllNodes" SG_ 2154471424 RrClosAjarSwAct 1;
BA_ "GenSigSendType" SG_ 2151940096 EstIntHorzDshSrfTmpM 10;
BA_ "SignalType" SG_ 2151940096 EstIntHorzDshSrfTmpM "ENM";
BA_ "SignalLongName" SG_ 2151940096 EstIntHorzDshSrfTmpM "Estimated Interior Horizontal Dash Surface Temperature Mask";
BA_ "VNSigAllNodes" SG_ 2151940096 EstIntHorzDshSrfTmpM 1;
BA_ "GenSigDeltaValue" SG_ 2151940096 EstIntHorzDshSrfTmp 1;
BA_ "GenSigSendType" SG_ 2151940096 EstIntHorzDshSrfTmp 12;
BA_ "SignalType" SG_ 2151940096 EstIntHorzDshSrfTmp "UNM";
BA_ "SignalLongName" SG_ 2151940096 EstIntHorzDshSrfTmp "Estimated Interior Horizontal Dash Surface Temperature";
BA_ "VNSigAllNodes" SG_ 2151940096 EstIntHorzDshSrfTmp 1;
BA_ "GenSigSendType" SG_ 2151940096 EstIntRfSrfcTmpV 10;
BA_ "SignalType" SG_ 2151940096 EstIntRfSrfcTmpV "ENM";
BA_ "SignalLongName" SG_ 2151940096 EstIntRfSrfcTmpV "Estimated Interior Roof Surface Temperature Validity";
BA_ "VNSigAllNodes" SG_ 2151940096 EstIntRfSrfcTmpV 1;
BA_ "GenSigDeltaValue" SG_ 2151940096 EstIntRfSrfcTmp 1;
BA_ "GenSigSendType" SG_ 2151940096 EstIntRfSrfcTmp 12;
BA_ "SignalType" SG_ 2151940096 EstIntRfSrfcTmp "UNM";
BA_ "SignalLongName" SG_ 2151940096 EstIntRfSrfcTmp "Estimated Interior Roof Surface Temperature";
BA_ "VNSigAllNodes" SG_ 2151940096 EstIntRfSrfcTmp 1;
BA_ "GenSigSendType" SG_ 2151940096 EstBulkIntAirTmpV 10;
BA_ "SignalType" SG_ 2151940096 EstBulkIntAirTmpV "ENM";
BA_ "SignalLongName" SG_ 2151940096 EstBulkIntAirTmpV "Estimated Bulk Interior Air Temperature Validity";
BA_ "VNSigAllNodes" SG_ 2151940096 EstBulkIntAirTmpV 1;
BA_ "GenSigDeltaValue" SG_ 2151940096 EstBulkIntAirTmp 1;
BA_ "GenSigSendType" SG_ 2151940096 EstBulkIntAirTmp 12;
BA_ "SignalType" SG_ 2151940096 EstBulkIntAirTmp "UNM";
BA_ "SignalLongName" SG_ 2151940096 EstBulkIntAirTmp "Estimated Bulk Interior Air Temperature";
BA_ "VNSigAllNodes" SG_ 2151940096 EstBulkIntAirTmp 1;
BA_ "GenSigDeltaValue" SG_ 2151940096 A2ERRAlrmTime 1;
BA_ "GenSigSendType" SG_ 2151940096 A2ERRAlrmTime 12;
BA_ "VNSigIntermediate" SG_ 2151940096 A2ERRAlrmTime 1;
BA_ "SignalType" SG_ 2151940096 A2ERRAlrmTime "UNM";
BA_ "PacketOrder" SG_ 2151940096 A2ERRAlrmTime 2;
BA_ "SignalLongName" SG_ 2151940096 A2ERRAlrmTime "Alarm 2 Extended Range Request : Alarm Time";
BA_ "VNSigAllNodes" SG_ 2151940096 A2ERRAlrmTime 1;
BA_ "GenSigSendType" SG_ 2151940096 A2ERRAlrmReq 10;
BA_ "VNSigIntermediate" SG_ 2151940096 A2ERRAlrmReq 1;
BA_ "SignalType" SG_ 2151940096 A2ERRAlrmReq "ENM";
BA_ "PacketOrder" SG_ 2151940096 A2ERRAlrmReq 1;
BA_ "SignalLongName" SG_ 2151940096 A2ERRAlrmReq "Alarm 2 Extended Range Request : Alarm Request";
BA_ "VNSigAllNodes" SG_ 2151940096 A2ERRAlrmReq 1;
BA_ "GenSigSendType" SG_ 2154987520 WrlsChrgSysChrgStat 10;
BA_ "SignalType" SG_ 2154987520 WrlsChrgSysChrgStat "ENM";
BA_ "SignalLongName" SG_ 2154987520 WrlsChrgSysChrgStat "Wireless Charging System Charging Status";
BA_ "VNSigAllNodes" SG_ 2154987520 WrlsChrgSysChrgStat 1;
BA_ "GenSigSendType" SG_ 2154987520 HdStV 10;
BA_ "SignalType" SG_ 2154987520 HdStV "ENM";
BA_ "SignalLongName" SG_ 2154987520 HdStV "Hood Status Validity";
BA_ "VNSigAllNodes" SG_ 2154987520 HdStV 1;
BA_ "GenSigSendType" SG_ 2154987520 HdSt 10;
BA_ "GenSigSendOnInit" SG_ 2154987520 HdSt 2;
BA_ "SignalType" SG_ 2154987520 HdSt "ENM";
BA_ "SignalLongName" SG_ 2154987520 HdSt "Hood Status";
BA_ "VNSigAllNodes" SG_ 2154987520 HdSt 1;
BA_ "GenSigSendType" SG_ 2156281856 LftmEffDtRstRqd 10;
BA_ "GenSigSendOnInit" SG_ 2156281856 LftmEffDtRstRqd 1;
BA_ "VNSigInfotainment" SG_ 2156281856 LftmEffDtRstRqd 1;
BA_ "SignalType" SG_ 2156281856 LftmEffDtRstRqd "BLN";
BA_ "SignalLongName" SG_ 2156281856 LftmEffDtRstRqd "Lifetime Efficiency Data Reset Requested";
BA_ "VNSigAllNodes" SG_ 2156281856 LftmEffDtRstRqd 1;
BA_ "GenSigSendType" SG_ 2156281856 HTRCsStReq 10;
BA_ "VNSigInfotainment" SG_ 2156281856 HTRCsStReq 1;
BA_ "SignalType" SG_ 2156281856 HTRCsStReq "ENM";
BA_ "SignalLongName" SG_ 2156281856 HTRCsStReq "Hill Top Reserve Customization Setting Request";
BA_ "VNSigAllNodes" SG_ 2156281856 HTRCsStReq 1;
BA_ "GenSigSendType" SG_ 2156281856 RtBsChrgCmplnTmPrfReq 10;
BA_ "VNSigInfotainment" SG_ 2156281856 RtBsChrgCmplnTmPrfReq 1;
BA_ "SignalType" SG_ 2156281856 RtBsChrgCmplnTmPrfReq "ENM";
BA_ "SignalLongName" SG_ 2156281856 RtBsChrgCmplnTmPrfReq "Rate Based Charge Completion Time Preference Request";
BA_ "VNSigAllNodes" SG_ 2156281856 RtBsChrgCmplnTmPrfReq 1;
BA_ "GenSigSendType" SG_ 2156281856 TONPDTR_StTmpOvrAtv 10;
BA_ "VNSigInfotainment" SG_ 2156281856 TONPDTR_StTmpOvrAtv 1;
BA_ "SignalType" SG_ 2156281856 TONPDTR_StTmpOvrAtv "ENM";
BA_ "PacketOrder" SG_ 2156281856 TONPDTR_StTmpOvrAtv 1;
BA_ "SignalLongName" SG_ 2156281856 TONPDTR_StTmpOvrAtv "Temporary Override Next Planned Departure Time Requested : Set Temporary Override Next Planned Departure Time Active";
BA_ "VNSigAllNodes" SG_ 2156281856 TONPDTR_StTmpOvrAtv 1;
BA_ "GenSigDeltaValue" SG_ 2156281856 TONPDTR_MntOfHr 1;
BA_ "GenSigSendType" SG_ 2156281856 TONPDTR_MntOfHr 12;
BA_ "VNSigInfotainment" SG_ 2156281856 TONPDTR_MntOfHr 1;
BA_ "SignalType" SG_ 2156281856 TONPDTR_MntOfHr "UNM";
BA_ "PacketOrder" SG_ 2156281856 TONPDTR_MntOfHr 4;
BA_ "SignalLongName" SG_ 2156281856 TONPDTR_MntOfHr "Temporary Override Next Planned Departure Time Requested : Minute of Hour";
BA_ "VNSigAllNodes" SG_ 2156281856 TONPDTR_MntOfHr 1;
BA_ "GenSigDeltaValue" SG_ 2156281856 TONPDTR_HrOfDy 1;
BA_ "GenSigSendType" SG_ 2156281856 TONPDTR_HrOfDy 12;
BA_ "VNSigInfotainment" SG_ 2156281856 TONPDTR_HrOfDy 1;
BA_ "SignalType" SG_ 2156281856 TONPDTR_HrOfDy "UNM";
BA_ "PacketOrder" SG_ 2156281856 TONPDTR_HrOfDy 3;
BA_ "SignalLongName" SG_ 2156281856 TONPDTR_HrOfDy "Temporary Override Next Planned Departure Time Requested : Hour of Day";
BA_ "VNSigAllNodes" SG_ 2156281856 TONPDTR_HrOfDy 1;
BA_ "GenSigSendType" SG_ 2156281856 TONPDTR_DyOfWk 10;
BA_ "VNSigInfotainment" SG_ 2156281856 TONPDTR_DyOfWk 1;
BA_ "SignalType" SG_ 2156281856 TONPDTR_DyOfWk "ENM";
BA_ "PacketOrder" SG_ 2156281856 TONPDTR_DyOfWk 2;
BA_ "SignalLongName" SG_ 2156281856 TONPDTR_DyOfWk "Temporary Override Next Planned Departure Time Requested : Day of Week";
BA_ "VNSigAllNodes" SG_ 2156281856 TONPDTR_DyOfWk 1;
BA_ "GenSigSendType" SG_ 2156281856 StTODChrgTmpOvrd 10;
BA_ "VNSigInfotainment" SG_ 2156281856 StTODChrgTmpOvrd 1;
BA_ "SignalType" SG_ 2156281856 StTODChrgTmpOvrd "BLN";
BA_ "SignalLongName" SG_ 2156281856 StTODChrgTmpOvrd "Set Time of Day Charge Temporary Override";
BA_ "VNSigAllNodes" SG_ 2156281856 StTODChrgTmpOvrd 1;
BA_ "GenSigSendType" SG_ 2156281856 HVBTBSCSR_SsnStReq 10;
BA_ "VNSigInfotainment" SG_ 2156281856 HVBTBSCSR_SsnStReq 1;
BA_ "SignalType" SG_ 2156281856 HVBTBSCSR_SsnStReq "ENM";
BA_ "PacketOrder" SG_ 2156281856 HVBTBSCSR_SsnStReq 1;
BA_ "SignalLongName" SG_ 2156281856 HVBTBSCSR_SsnStReq "High Voltage Battery Time Based Season Charging Set Request : Season Set Request";
BA_ "VNSigAllNodes" SG_ 2156281856 HVBTBSCSR_SsnStReq 1;
BA_ "GenSigSendType" SG_ 2156281856 HVBTBSCSR_SsnSlStReq 10;
BA_ "VNSigInfotainment" SG_ 2156281856 HVBTBSCSR_SsnSlStReq 1;
BA_ "SignalType" SG_ 2156281856 HVBTBSCSR_SsnSlStReq "ENM";
BA_ "PacketOrder" SG_ 2156281856 HVBTBSCSR_SsnSlStReq 2;
BA_ "SignalLongName" SG_ 2156281856 HVBTBSCSR_SsnSlStReq "High Voltage Battery Time Based Season Charging Set Request : Season Selected Set Requset";
BA_ "VNSigAllNodes" SG_ 2156281856 HVBTBSCSR_SsnSlStReq 1;
BA_ "GenSigSendType" SG_ 2156281856 HVBTBSCSR_SsnMthStReq 10;
BA_ "VNSigInfotainment" SG_ 2156281856 HVBTBSCSR_SsnMthStReq 1;
BA_ "SignalType" SG_ 2156281856 HVBTBSCSR_SsnMthStReq "ENM";
BA_ "PacketOrder" SG_ 2156281856 HVBTBSCSR_SsnMthStReq 3;
BA_ "SignalLongName" SG_ 2156281856 HVBTBSCSR_SsnMthStReq "High Voltage Battery Time Based Season Charging Set Request : Season Month Set Request";
BA_ "VNSigAllNodes" SG_ 2156281856 HVBTBSCSR_SsnMthStReq 1;
BA_ "GenSigDeltaValue" SG_ 2156281856 HVBTBSCSR_SsnDayStReq 1;
BA_ "GenSigSendType" SG_ 2156281856 HVBTBSCSR_SsnDayStReq 12;
BA_ "VNSigInfotainment" SG_ 2156281856 HVBTBSCSR_SsnDayStReq 1;
BA_ "SignalType" SG_ 2156281856 HVBTBSCSR_SsnDayStReq "UNM";
BA_ "PacketOrder" SG_ 2156281856 HVBTBSCSR_SsnDayStReq 4;
BA_ "SignalLongName" SG_ 2156281856 HVBTBSCSR_SsnDayStReq "High Voltage Battery Time Based Season Charging Set Request : Season Day Set Request";
BA_ "VNSigAllNodes" SG_ 2156281856 HVBTBSCSR_SsnDayStReq 1;
BA_ "GenSigSendType" SG_ 2156281856 HVBTBCRSR_ChRtSlStReq 10;
BA_ "VNSigInfotainment" SG_ 2156281856 HVBTBCRSR_ChRtSlStReq 1;
BA_ "SignalType" SG_ 2156281856 HVBTBCRSR_ChRtSlStReq "ENM";
BA_ "PacketOrder" SG_ 2156281856 HVBTBCRSR_ChRtSlStReq 3;
BA_ "SignalLongName" SG_ 2156281856 HVBTBCRSR_ChRtSlStReq "High Voltage Battery Time Based Charge Rate Set Request : Charge Rate Selected Set Request";
BA_ "VNSigAllNodes" SG_ 2156281856 HVBTBCRSR_ChRtSlStReq 1;
BA_ "GenSigSendType" SG_ 2156281856 HVBTBCRSR_ChRtEnblStReq 10;
BA_ "VNSigInfotainment" SG_ 2156281856 HVBTBCRSR_ChRtEnblStReq 1;
BA_ "SignalType" SG_ 2156281856 HVBTBCRSR_ChRtEnblStReq "ENM";
BA_ "PacketOrder" SG_ 2156281856 HVBTBCRSR_ChRtEnblStReq 1;
BA_ "SignalLongName" SG_ 2156281856 HVBTBCRSR_ChRtEnblStReq "High Voltage Battery Time Based Charge Rate Set Request : Charge Rate Enable Set Request";
BA_ "VNSigAllNodes" SG_ 2156281856 HVBTBCRSR_ChRtEnblStReq 1;
BA_ "GenSigSendType" SG_ 2156281856 HVBTBCRSR_ChRtDStReq 10;
BA_ "VNSigInfotainment" SG_ 2156281856 HVBTBCRSR_ChRtDStReq 1;
BA_ "SignalType" SG_ 2156281856 HVBTBCRSR_ChRtDStReq "ENM";
BA_ "PacketOrder" SG_ 2156281856 HVBTBCRSR_ChRtDStReq 2;
BA_ "SignalLongName" SG_ 2156281856 HVBTBCRSR_ChRtDStReq "High Voltage Battery Time Based Charge Rate Set Request : Charge Rate Day Set Request";
BA_ "VNSigAllNodes" SG_ 2156281856 HVBTBCRSR_ChRtDStReq 1;
BA_ "GenSigSendType" SG_ 2156281856 HVBatTmBsChrgMdReq 10;
BA_ "VNSigInfotainment" SG_ 2156281856 HVBatTmBsChrgMdReq 1;
BA_ "SignalType" SG_ 2156281856 HVBatTmBsChrgMdReq "ENM";
BA_ "SignalLongName" SG_ 2156281856 HVBatTmBsChrgMdReq "High Voltage Battery Time Based Charging Mode Request";
BA_ "VNSigAllNodes" SG_ 2156281856 HVBatTmBsChrgMdReq 1;
BA_ "GenSigSendType" SG_ 2156281856 HVChgSyChgLvlPrfSt 10;
BA_ "VNSigInfotainment" SG_ 2156281856 HVChgSyChgLvlPrfSt 1;
BA_ "SignalType" SG_ 2156281856 HVChgSyChgLvlPrfSt "ENM";
BA_ "SignalLongName" SG_ 2156281856 HVChgSyChgLvlPrfSt "High Voltage Charging System Charge Level Preference Setting";
BA_ "VNSigAllNodes" SG_ 2156281856 HVChgSyChgLvlPrfSt 1;
BA_ "GenSigSendType" SG_ 2156281856 TODCTmpImdtOvrdReq 10;
BA_ "VNSigInfotainment" SG_ 2156281856 TODCTmpImdtOvrdReq 1;
BA_ "SignalType" SG_ 2156281856 TODCTmpImdtOvrdReq "ENM";
BA_ "SignalLongName" SG_ 2156281856 TODCTmpImdtOvrdReq "Time Of Day Charge Temporary Immediate Override Request";
BA_ "VNSigAllNodes" SG_ 2156281856 TODCTmpImdtOvrdReq 1;
BA_ "GenSigSendType" SG_ 2156314624 HVChrgSysSplyFltIO 10;
BA_ "SignalType" SG_ 2156314624 HVChrgSysSplyFltIO "BLN";
BA_ "SignalLongName" SG_ 2156314624 HVChrgSysSplyFltIO "High Voltage Charging System Supply Fault Indication On";
BA_ "VNSigAllNodes" SG_ 2156314624 HVChrgSysSplyFltIO 1;
BA_ "GenSigSendType" SG_ 2156314624 OffBrdCSFltDtctd 10;
BA_ "VNSigInfotainment" SG_ 2156314624 OffBrdCSFltDtctd 1;
BA_ "SignalType" SG_ 2156314624 OffBrdCSFltDtctd "BLN";
BA_ "SignalLongName" SG_ 2156314624 OffBrdCSFltDtctd "Off Board Charge Station Fault Detected";
BA_ "VNSigAllNodes" SG_ 2156314624 OffBrdCSFltDtctd 1;
BA_ "GenSigSendType" SG_ 2156314624 OBVhCsACChgRqBnVs 10;
BA_ "GenSigSendOnInit" SG_ 2156314624 OBVhCsACChgRqBnVs 1;
BA_ "VNSigInfotainment" SG_ 2156314624 OBVhCsACChgRqBnVs 1;
BA_ "SignalType" SG_ 2156314624 OBVhCsACChgRqBnVs "BLN";
BA_ "SignalLongName" SG_ 2156314624 OBVhCsACChgRqBnVs "On Board Vehicle Cease AC Charging Request Button Visible";
BA_ "VNSigAllNodes" SG_ 2156314624 OBVhCsACChgRqBnVs 1;
BA_ "GenSigDeltaValue" SG_ 2156314624 TODCNPDT_Min 1;
BA_ "GenSigSendType" SG_ 2156314624 TODCNPDT_Min 12;
BA_ "GenSigSendOnInit" SG_ 2156314624 TODCNPDT_Min 1;
BA_ "VNSigInfotainment" SG_ 2156314624 TODCNPDT_Min 1;
BA_ "SignalType" SG_ 2156314624 TODCNPDT_Min "UNM";
BA_ "PacketOrder" SG_ 2156314624 TODCNPDT_Min 3;
BA_ "SignalLongName" SG_ 2156314624 TODCNPDT_Min "Time Of Day Charging Next Planned Departure Time : Minute";
BA_ "VNSigAllNodes" SG_ 2156314624 TODCNPDT_Min 1;
BA_ "GenSigDeltaValue" SG_ 2156314624 TODCNPDT_Hr 1;
BA_ "GenSigSendType" SG_ 2156314624 TODCNPDT_Hr 12;
BA_ "GenSigSendOnInit" SG_ 2156314624 TODCNPDT_Hr 1;
BA_ "VNSigInfotainment" SG_ 2156314624 TODCNPDT_Hr 1;
BA_ "SignalType" SG_ 2156314624 TODCNPDT_Hr "UNM";
BA_ "PacketOrder" SG_ 2156314624 TODCNPDT_Hr 2;
BA_ "SignalLongName" SG_ 2156314624 TODCNPDT_Hr "Time Of Day Charging Next Planned Departure Time : Hour";
BA_ "VNSigAllNodes" SG_ 2156314624 TODCNPDT_Hr 1;
BA_ "GenSigSendType" SG_ 2156314624 TODCNPDT_DyOfWk 10;
BA_ "GenSigSendOnInit" SG_ 2156314624 TODCNPDT_DyOfWk 1;
BA_ "VNSigInfotainment" SG_ 2156314624 TODCNPDT_DyOfWk 1;
BA_ "SignalType" SG_ 2156314624 TODCNPDT_DyOfWk "ENM";
BA_ "PacketOrder" SG_ 2156314624 TODCNPDT_DyOfWk 1;
BA_ "SignalLongName" SG_ 2156314624 TODCNPDT_DyOfWk "Time Of Day Charging Next Planned Departure Time : Day of Week";
BA_ "VNSigAllNodes" SG_ 2156314624 TODCNPDT_DyOfWk 1;
BA_ "GenSigDeltaValue" SG_ 2156314624 HVBatBlkSOC 1;
BA_ "GenSigSendType" SG_ 2156314624 HVBatBlkSOC 12;
BA_ "GenSigSendOnInit" SG_ 2156314624 HVBatBlkSOC 1;
BA_ "VNSigInfotainment" SG_ 2156314624 HVBatBlkSOC 1;
BA_ "SignalType" SG_ 2156314624 HVBatBlkSOC "UNM";
BA_ "SignalLongName" SG_ 2156314624 HVBatBlkSOC "High Voltage Battery Bulk State of Charge";
BA_ "VNSigAllNodes" SG_ 2156314624 HVBatBlkSOC 1;
BA_ "GenSigSendType" SG_ 2156314624 TODCOpMd 10;
BA_ "VNSigInfotainment" SG_ 2156314624 TODCOpMd 1;
BA_ "SignalType" SG_ 2156314624 TODCOpMd "ENM";
BA_ "SignalLongName" SG_ 2156314624 TODCOpMd "Time of Day Charging Operating Mode";
BA_ "VNSigAllNodes" SG_ 2156314624 TODCOpMd 1;
BA_ "GenSigSendType" SG_ 2156314624 TODCDMPTO_TpOvR 10;
BA_ "GenSigSendOnInit" SG_ 2156314624 TODCDMPTO_TpOvR 1;
BA_ "VNSigInfotainment" SG_ 2156314624 TODCDMPTO_TpOvR 1;
BA_ "SignalType" SG_ 2156314624 TODCDMPTO_TpOvR "ENM";
BA_ "PacketOrder" SG_ 2156314624 TODCDMPTO_TpOvR 2;
BA_ "SignalLongName" SG_ 2156314624 TODCDMPTO_TpOvR "Time of Day Charging Display Main Page Temporary Override : Display Temporary Override Request";
BA_ "VNSigAllNodes" SG_ 2156314624 TODCDMPTO_TpOvR 1;
BA_ "GenSigSendType" SG_ 2156314624 TODCDMPTO_CmPgR 10;
BA_ "GenSigSendOnInit" SG_ 2156314624 TODCDMPTO_CmPgR 1;
BA_ "VNSigInfotainment" SG_ 2156314624 TODCDMPTO_CmPgR 1;
BA_ "SignalType" SG_ 2156314624 TODCDMPTO_CmPgR "BLN";
BA_ "PacketOrder" SG_ 2156314624 TODCDMPTO_CmPgR 1;
BA_ "SignalLongName" SG_ 2156314624 TODCDMPTO_CmPgR "Time of Day Charging Display Main Page Temporary Override : Charging Complete Page Requested";
BA_ "VNSigAllNodes" SG_ 2156314624 TODCDMPTO_CmPgR 1;
BA_ "GenSigSendType" SG_ 2156314624 HVChrgSysStNot 10;
BA_ "VNSigInfotainment" SG_ 2156314624 HVChrgSysStNot 1;
BA_ "SignalType" SG_ 2156314624 HVChrgSysStNot "ENM";
BA_ "SignalLongName" SG_ 2156314624 HVChrgSysStNot "High Voltage Charger System Status Notification";
BA_ "VNSigAllNodes" SG_ 2156314624 HVChrgSysStNot 1;
BA_ "GenSigSendType" SG_ 2156314624 HVChrgAbrtRsn 10;
BA_ "VNSigInfotainment" SG_ 2156314624 HVChrgAbrtRsn 1;
BA_ "SignalType" SG_ 2156314624 HVChrgAbrtRsn "ENM";
BA_ "SignalLongName" SG_ 2156314624 HVChrgAbrtRsn "High Voltage Charge Abort Reason";
BA_ "VNSigAllNodes" SG_ 2156314624 HVChrgAbrtRsn 1;
BA_ "GenSigSendType" SG_ 2156314624 HVCSCLPD_UsrIntTyp 10;
BA_ "GenSigSendOnInit" SG_ 2156314624 HVCSCLPD_UsrIntTyp 1;
BA_ "VNSigInfotainment" SG_ 2156314624 HVCSCLPD_UsrIntTyp 1;
BA_ "SignalType" SG_ 2156314624 HVCSCLPD_UsrIntTyp "ENM";
BA_ "PacketOrder" SG_ 2156314624 HVCSCLPD_UsrIntTyp 1;
BA_ "SignalLongName" SG_ 2156314624 HVCSCLPD_UsrIntTyp "High Voltage Charging System Charge Level Preference Data : User Interface Type";
BA_ "VNSigAllNodes" SG_ 2156314624 HVCSCLPD_UsrIntTyp 1;
BA_ "GenSigDeltaValue" SG_ 2156314624 HVCSCLPD_RdCrntLv3 1;
BA_ "GenSigSendType" SG_ 2156314624 HVCSCLPD_RdCrntLv3 12;
BA_ "GenSigSendOnInit" SG_ 2156314624 HVCSCLPD_RdCrntLv3 1;
BA_ "VNSigInfotainment" SG_ 2156314624 HVCSCLPD_RdCrntLv3 1;
BA_ "SignalType" SG_ 2156314624 HVCSCLPD_RdCrntLv3 "UNM";
BA_ "PacketOrder" SG_ 2156314624 HVCSCLPD_RdCrntLv3 6;
BA_ "SignalLongName" SG_ 2156314624 HVCSCLPD_RdCrntLv3 "High Voltage Charging System Charge Level Preference Data : Reduced Current Level 3";
BA_ "VNSigAllNodes" SG_ 2156314624 HVCSCLPD_RdCrntLv3 1;
BA_ "GenSigDeltaValue" SG_ 2156314624 HVCSCLPD_RdCrntLv2 1;
BA_ "GenSigSendType" SG_ 2156314624 HVCSCLPD_RdCrntLv2 12;
BA_ "GenSigSendOnInit" SG_ 2156314624 HVCSCLPD_RdCrntLv2 1;
BA_ "VNSigInfotainment" SG_ 2156314624 HVCSCLPD_RdCrntLv2 1;
BA_ "SignalType" SG_ 2156314624 HVCSCLPD_RdCrntLv2 "UNM";
BA_ "PacketOrder" SG_ 2156314624 HVCSCLPD_RdCrntLv2 5;
BA_ "SignalLongName" SG_ 2156314624 HVCSCLPD_RdCrntLv2 "High Voltage Charging System Charge Level Preference Data : Reduced Current Level 2";
BA_ "VNSigAllNodes" SG_ 2156314624 HVCSCLPD_RdCrntLv2 1;
BA_ "GenSigDeltaValue" SG_ 2156314624 HVCSCLPD_RdCrntLv1 1;
BA_ "GenSigSendType" SG_ 2156314624 HVCSCLPD_RdCrntLv1 12;
BA_ "GenSigSendOnInit" SG_ 2156314624 HVCSCLPD_RdCrntLv1 1;
BA_ "VNSigInfotainment" SG_ 2156314624 HVCSCLPD_RdCrntLv1 1;
BA_ "SignalType" SG_ 2156314624 HVCSCLPD_RdCrntLv1 "UNM";
BA_ "PacketOrder" SG_ 2156314624 HVCSCLPD_RdCrntLv1 4;
BA_ "SignalLongName" SG_ 2156314624 HVCSCLPD_RdCrntLv1 "High Voltage Charging System Charge Level Preference Data : Reduced Current Level 1";
BA_ "VNSigAllNodes" SG_ 2156314624 HVCSCLPD_RdCrntLv1 1;
BA_ "GenSigDeltaValue" SG_ 2156314624 HVCSCLPD_NrmChrgC 1;
BA_ "GenSigSendType" SG_ 2156314624 HVCSCLPD_NrmChrgC 12;
BA_ "GenSigSendOnInit" SG_ 2156314624 HVCSCLPD_NrmChrgC 1;
BA_ "VNSigInfotainment" SG_ 2156314624 HVCSCLPD_NrmChrgC 1;
BA_ "SignalType" SG_ 2156314624 HVCSCLPD_NrmChrgC "UNM";
BA_ "PacketOrder" SG_ 2156314624 HVCSCLPD_NrmChrgC 3;
BA_ "SignalLongName" SG_ 2156314624 HVCSCLPD_NrmChrgC "High Voltage Charging System Charge Level Preference Data : Normal Charge Current";
BA_ "VNSigAllNodes" SG_ 2156314624 HVCSCLPD_NrmChrgC 1;
BA_ "GenSigSendType" SG_ 2156314624 HVCSCLPD_ChgLvlPfS 10;
BA_ "GenSigSendOnInit" SG_ 2156314624 HVCSCLPD_ChgLvlPfS 1;
BA_ "VNSigInfotainment" SG_ 2156314624 HVCSCLPD_ChgLvlPfS 1;
BA_ "SignalType" SG_ 2156314624 HVCSCLPD_ChgLvlPfS "ENM";
BA_ "PacketOrder" SG_ 2156314624 HVCSCLPD_ChgLvlPfS 2;
BA_ "SignalLongName" SG_ 2156314624 HVCSCLPD_ChgLvlPfS "High Voltage Charging System Charge Level Preference Data : Charge Level Preference Status";
BA_ "VNSigAllNodes" SG_ 2156314624 HVCSCLPD_ChgLvlPfS 1;
BA_ "SignalType" SG_ 2149761024 PsngStPerfMdCsCrStVal "ENM";
BA_ "SignalLongName" SG_ 2149761024 PsngStPerfMdCsCrStVal "Passenger Seat Performance Mode Customization Current Setting Value";
BA_ "VNSigAllNodes" SG_ 2149761024 PsngStPerfMdCsCrStVal 1;
BA_ "SignalType" SG_ 2149761024 PsngStPerfMdCsStAvl "BLN";
BA_ "SignalLongName" SG_ 2149761024 PsngStPerfMdCsStAvl "Passenger Seat Performance Mode Customization Setting Available";
BA_ "VNSigAllNodes" SG_ 2149761024 PsngStPerfMdCsStAvl 1;
BA_ "SignalType" SG_ 2149761024 ElvtdIdlCstCrStVal "ENM";
BA_ "SignalLongName" SG_ 2149761024 ElvtdIdlCstCrStVal "Elevated Idle Customization Current Setting Value";
BA_ "VNSigAllNodes" SG_ 2149761024 ElvtdIdlCstCrStVal 1;
BA_ "SignalType" SG_ 2149761024 ElvtdIdlCstStAvl "BLN";
BA_ "SignalLongName" SG_ 2149761024 ElvtdIdlCstStAvl "Elevated Idle Customization Setting Available";
BA_ "VNSigAllNodes" SG_ 2149761024 ElvtdIdlCstStAvl 1;
BA_ "SignalType" SG_ 2149761024 TCTPIR_TnsEsClCDwT "UNM";
BA_ "PacketOrder" SG_ 2149761024 TCTPIR_TnsEsClCDwT 3;
BA_ "SignalLongName" SG_ 2149761024 TCTPIR_TnsEsClCDwT "Transmission Clutch Thermal Protection Indication Request : Transmission Estimated Clutch Cool-down Temperature Target Display";
BA_ "VNSigAllNodes" SG_ 2149761024 TCTPIR_TnsEsClCDwT 1;
BA_ "SignalType" SG_ 2149761024 TCTPIR_TnsEsClTmpD "UNM";
BA_ "PacketOrder" SG_ 2149761024 TCTPIR_TnsEsClTmpD 2;
BA_ "SignalLongName" SG_ 2149761024 TCTPIR_TnsEsClTmpD "Transmission Clutch Thermal Protection Indication Request : Transmission Estimated Clutch Temperature Display";
BA_ "VNSigAllNodes" SG_ 2149761024 TCTPIR_TnsEsClTmpD 1;
BA_ "SignalType" SG_ 2149761024 TCTPIR_DrvNotfn "ENM";
BA_ "PacketOrder" SG_ 2149761024 TCTPIR_DrvNotfn 1;
BA_ "SignalLongName" SG_ 2149761024 TCTPIR_DrvNotfn "Transmission Clutch Thermal Protection Indication Request : Driver Notification";
BA_ "VNSigAllNodes" SG_ 2149761024 TCTPIR_DrvNotfn 1;
BA_ "SignalType" SG_ 2149761024 TrlrStabAstActIO "BLN";
BA_ "SignalLongName" SG_ 2149761024 TrlrStabAstActIO "Trailer Stability Assist Active Indication On";
BA_ "VNSigAllNodes" SG_ 2149761024 TrlrStabAstActIO 1;
BA_ "SignalType" SG_ 2149761024 PerfTrcCrnExStngVal "ENM";
BA_ "SignalLongName" SG_ 2149761024 PerfTrcCrnExStngVal "Performance Traction Corner Exit Setting Value";
BA_ "VNSigAllNodes" SG_ 2149761024 PerfTrcCrnExStngVal 1;
BA_ "SignalType" SG_ 2149761024 ActVehAccelV "ENM";
BA_ "SignalLongName" SG_ 2149761024 ActVehAccelV "Actual Vehicle Acceleration Validity";
BA_ "VNSigAllNodes" SG_ 2149761024 ActVehAccelV 1;
BA_ "SignalType" SG_ 2149761024 ActVehAccel "SNM";
BA_ "SignalLongName" SG_ 2149761024 ActVehAccel "Actual Vehicle Acceleration";
BA_ "VNSigAllNodes" SG_ 2149761024 ActVehAccel 1;
BA_ "GenSigSendType" SG_ 2151997440 DrvDrowSysIndRq 10;
BA_ "SignalType" SG_ 2151997440 DrvDrowSysIndRq "ENM";
BA_ "SignalLongName" SG_ 2151997440 DrvDrowSysIndRq "Driver Drowsiness System Indication Request";
BA_ "VNSigAllNodes" SG_ 2151997440 DrvDrowSysIndRq 1;
BA_ "GenSigSendType" SG_ 2151997440 DrvDrwDetCsCrStVal 10;
BA_ "GenSigSendOnInit" SG_ 2151997440 DrvDrwDetCsCrStVal 2;
BA_ "SignalType" SG_ 2151997440 DrvDrwDetCsCrStVal "ENM";
BA_ "SignalLongName" SG_ 2151997440 DrvDrwDetCsCrStVal "Driver Drowsiness Detection Customization Current Setting Value";
BA_ "VNSigAllNodes" SG_ 2151997440 DrvDrwDetCsCrStVal 1;
BA_ "GenSigSendType" SG_ 2151997440 DrvDrowDetCstStAvl 10;
BA_ "GenSigSendOnInit" SG_ 2151997440 DrvDrowDetCstStAvl 2;
BA_ "SignalType" SG_ 2151997440 DrvDrowDetCstStAvl "BLN";
BA_ "SignalLongName" SG_ 2151997440 DrvDrowDetCstStAvl "Driver Drowsiness Detection Customization Setting Available";
BA_ "VNSigAllNodes" SG_ 2151997440 DrvDrowDetCstStAvl 1;
BA_ "GenSigDeltaValue" SG_ 2151997440 DrvDrsnHptcStRqSeqN 1;
BA_ "GenSigSendType" SG_ 2151997440 DrvDrsnHptcStRqSeqN 12;
BA_ "SignalType" SG_ 2151997440 DrvDrsnHptcStRqSeqN "UNM";
BA_ "SignalLongName" SG_ 2151997440 DrvDrsnHptcStRqSeqN "Driver Drowsiness System Haptic Seat Vibration Request Sequence Number";
BA_ "VNSigAllNodes" SG_ 2151997440 DrvDrsnHptcStRqSeqN 1;
BA_ "GenSigDeltaValue" SG_ 2151997440 DrDrwSysHptcStVbnRq 1;
BA_ "GenSigSendType" SG_ 2151997440 DrDrwSysHptcStVbnRq 12;
BA_ "SignalType" SG_ 2151997440 DrDrwSysHptcStVbnRq "UNM";
BA_ "SignalLongName" SG_ 2151997440 DrDrwSysHptcStVbnRq "Driver Drowsiness System Haptic Seat Vibration Request";
BA_ "VNSigAllNodes" SG_ 2151997440 DrDrwSysHptcStVbnRq 1;
BA_ "GenSigSendType" SG_ 2151948288 RunBrdOpMdCstStReq 10;
BA_ "SignalType" SG_ 2151948288 RunBrdOpMdCstStReq "ENM";
BA_ "SignalLongName" SG_ 2151948288 RunBrdOpMdCstStReq "Running Boards Operating Mode Customization Setting Request";
BA_ "VNSigAllNodes" SG_ 2151948288 RunBrdOpMdCstStReq 1;
BA_ "GenSigSendType" SG_ 2151948288 DrvDrowDetCstStRq 10;
BA_ "SignalType" SG_ 2151948288 DrvDrowDetCstStRq "ENM";
BA_ "SignalLongName" SG_ 2151948288 DrvDrowDetCstStRq "Driver Drowsiness Detection Customization Setting Request";
BA_ "VNSigAllNodes" SG_ 2151948288 DrvDrowDetCstStRq 1;
BA_ "SignalType" SG_ 2152128512 PSPMCA_PsngStPrfMd6Avl "BLN";
BA_ "PacketOrder" SG_ 2152128512 PSPMCA_PsngStPrfMd6Avl 6;
BA_ "SignalLongName" SG_ 2152128512 PSPMCA_PsngStPrfMd6Avl "Passenger Seat Performance Mode Customization Available : Passenger Seat Performance Mode 6 Available";
BA_ "VNSigAllNodes" SG_ 2152128512 PSPMCA_PsngStPrfMd6Avl 1;
BA_ "SignalType" SG_ 2152128512 PSPMCA_PsngStPrfMd5Avl "BLN";
BA_ "PacketOrder" SG_ 2152128512 PSPMCA_PsngStPrfMd5Avl 5;
BA_ "SignalLongName" SG_ 2152128512 PSPMCA_PsngStPrfMd5Avl "Passenger Seat Performance Mode Customization Available : Passenger Seat Performance Mode 5 Available";
BA_ "VNSigAllNodes" SG_ 2152128512 PSPMCA_PsngStPrfMd5Avl 1;
BA_ "SignalType" SG_ 2152128512 PSPMCA_PsngStPrfMd4Avl "BLN";
BA_ "PacketOrder" SG_ 2152128512 PSPMCA_PsngStPrfMd4Avl 4;
BA_ "SignalLongName" SG_ 2152128512 PSPMCA_PsngStPrfMd4Avl "Passenger Seat Performance Mode Customization Available : Passenger Seat Performance Mode 4 Available";
BA_ "VNSigAllNodes" SG_ 2152128512 PSPMCA_PsngStPrfMd4Avl 1;
BA_ "SignalType" SG_ 2152128512 PSPMCA_PsngStPrfMd3Avl "BLN";
BA_ "PacketOrder" SG_ 2152128512 PSPMCA_PsngStPrfMd3Avl 3;
BA_ "SignalLongName" SG_ 2152128512 PSPMCA_PsngStPrfMd3Avl "Passenger Seat Performance Mode Customization Available : Passenger Seat Performance Mode 3 Available";
BA_ "VNSigAllNodes" SG_ 2152128512 PSPMCA_PsngStPrfMd3Avl 1;
BA_ "SignalType" SG_ 2152128512 PSPMCA_PsngStPrfMd2Avl "BLN";
BA_ "PacketOrder" SG_ 2152128512 PSPMCA_PsngStPrfMd2Avl 2;
BA_ "SignalLongName" SG_ 2152128512 PSPMCA_PsngStPrfMd2Avl "Passenger Seat Performance Mode Customization Available : Passenger Seat Performance Mode 2 Available";
BA_ "VNSigAllNodes" SG_ 2152128512 PSPMCA_PsngStPrfMd2Avl 1;
BA_ "SignalType" SG_ 2152128512 PSPMCA_PsngStPrfMd1Avl "BLN";
BA_ "PacketOrder" SG_ 2152128512 PSPMCA_PsngStPrfMd1Avl 1;
BA_ "SignalLongName" SG_ 2152128512 PSPMCA_PsngStPrfMd1Avl "Passenger Seat Performance Mode Customization Available : Passenger Seat Performance Mode 1 Available";
BA_ "VNSigAllNodes" SG_ 2152128512 PSPMCA_PsngStPrfMd1Avl 1;
BA_ "SignalType" SG_ 2152128512 DSPMCA_DrvrStPrfMd6Avl "BLN";
BA_ "PacketOrder" SG_ 2152128512 DSPMCA_DrvrStPrfMd6Avl 6;
BA_ "SignalLongName" SG_ 2152128512 DSPMCA_DrvrStPrfMd6Avl "Driver Seat Performance Mode Customization Available : Driver Seat Performance Mode 6 Available";
BA_ "VNSigAllNodes" SG_ 2152128512 DSPMCA_DrvrStPrfMd6Avl 1;
BA_ "SignalType" SG_ 2152128512 DSPMCA_DrvrStPrfMd5Avl "BLN";
BA_ "PacketOrder" SG_ 2152128512 DSPMCA_DrvrStPrfMd5Avl 5;
BA_ "SignalLongName" SG_ 2152128512 DSPMCA_DrvrStPrfMd5Avl "Driver Seat Performance Mode Customization Available : Driver Seat Performance Mode 5 Available";
BA_ "VNSigAllNodes" SG_ 2152128512 DSPMCA_DrvrStPrfMd5Avl 1;
BA_ "SignalType" SG_ 2152128512 DSPMCA_DrvrStPrfMd4Avl "BLN";
BA_ "PacketOrder" SG_ 2152128512 DSPMCA_DrvrStPrfMd4Avl 4;
BA_ "SignalLongName" SG_ 2152128512 DSPMCA_DrvrStPrfMd4Avl "Driver Seat Performance Mode Customization Available : Driver Seat Performance Mode 4 Available";
BA_ "VNSigAllNodes" SG_ 2152128512 DSPMCA_DrvrStPrfMd4Avl 1;
BA_ "SignalType" SG_ 2152128512 DSPMCA_DrvrStPrfMd3Avl "BLN";
BA_ "PacketOrder" SG_ 2152128512 DSPMCA_DrvrStPrfMd3Avl 3;
BA_ "SignalLongName" SG_ 2152128512 DSPMCA_DrvrStPrfMd3Avl "Driver Seat Performance Mode Customization Available : Driver Seat Performance Mode 3 Available";
BA_ "VNSigAllNodes" SG_ 2152128512 DSPMCA_DrvrStPrfMd3Avl 1;
BA_ "SignalType" SG_ 2152128512 DSPMCA_DrvrStPrfMd2Avl "BLN";
BA_ "PacketOrder" SG_ 2152128512 DSPMCA_DrvrStPrfMd2Avl 2;
BA_ "SignalLongName" SG_ 2152128512 DSPMCA_DrvrStPrfMd2Avl "Driver Seat Performance Mode Customization Available : Driver Seat Performance Mode 2 Available";
BA_ "VNSigAllNodes" SG_ 2152128512 DSPMCA_DrvrStPrfMd2Avl 1;
BA_ "SignalType" SG_ 2152128512 DSPMCA_DrvrStPrfMd1Avl "BLN";
BA_ "PacketOrder" SG_ 2152128512 DSPMCA_DrvrStPrfMd1Avl 1;
BA_ "SignalLongName" SG_ 2152128512 DSPMCA_DrvrStPrfMd1Avl "Driver Seat Performance Mode Customization Available : Driver Seat Performance Mode 1 Available";
BA_ "VNSigAllNodes" SG_ 2152128512 DSPMCA_DrvrStPrfMd1Avl 1;
BA_ "SignalType" SG_ 2152128512 DSPMCA_DrvStyPrfMd7Avl "BLN";
BA_ "PacketOrder" SG_ 2152128512 DSPMCA_DrvStyPrfMd7Avl 7;
BA_ "SignalLongName" SG_ 2152128512 DSPMCA_DrvStyPrfMd7Avl "Driving Style Performance Mode Customization Available : Driving Style Performance Mode 7 Available";
BA_ "VNSigAllNodes" SG_ 2152128512 DSPMCA_DrvStyPrfMd7Avl 1;
BA_ "SignalType" SG_ 2152128512 DSPMCA_DrvStyPrfMd6Avl "BLN";
BA_ "PacketOrder" SG_ 2152128512 DSPMCA_DrvStyPrfMd6Avl 6;
BA_ "SignalLongName" SG_ 2152128512 DSPMCA_DrvStyPrfMd6Avl "Driving Style Performance Mode Customization Available : Driving Style Performance Mode 6 Available";
BA_ "VNSigAllNodes" SG_ 2152128512 DSPMCA_DrvStyPrfMd6Avl 1;
BA_ "SignalType" SG_ 2152128512 DSPMCA_DrvStyPrfMd5Avl "BLN";
BA_ "PacketOrder" SG_ 2152128512 DSPMCA_DrvStyPrfMd5Avl 5;
BA_ "SignalLongName" SG_ 2152128512 DSPMCA_DrvStyPrfMd5Avl "Driving Style Performance Mode Customization Available : Driving Style Performance Mode 5 Available";
BA_ "VNSigAllNodes" SG_ 2152128512 DSPMCA_DrvStyPrfMd5Avl 1;
BA_ "SignalType" SG_ 2152128512 DSPMCA_DrvStyPrfMd4Avl "BLN";
BA_ "PacketOrder" SG_ 2152128512 DSPMCA_DrvStyPrfMd4Avl 4;
BA_ "SignalLongName" SG_ 2152128512 DSPMCA_DrvStyPrfMd4Avl "Driving Style Performance Mode Customization Available : Driving Style Performance Mode 4 Available";
BA_ "VNSigAllNodes" SG_ 2152128512 DSPMCA_DrvStyPrfMd4Avl 1;
BA_ "SignalType" SG_ 2152128512 DSPMCA_DrvStyPrfMd3Avl "BLN";
BA_ "PacketOrder" SG_ 2152128512 DSPMCA_DrvStyPrfMd3Avl 3;
BA_ "SignalLongName" SG_ 2152128512 DSPMCA_DrvStyPrfMd3Avl "Driving Style Performance Mode Customization Available : Driving Style Performance Mode 3 Available";
BA_ "VNSigAllNodes" SG_ 2152128512 DSPMCA_DrvStyPrfMd3Avl 1;
BA_ "SignalType" SG_ 2152128512 DSPMCA_DrvStyPrfMd2Avl "BLN";
BA_ "PacketOrder" SG_ 2152128512 DSPMCA_DrvStyPrfMd2Avl 2;
BA_ "SignalLongName" SG_ 2152128512 DSPMCA_DrvStyPrfMd2Avl "Driving Style Performance Mode Customization Available : Driving Style Performance Mode 2 Available";
BA_ "VNSigAllNodes" SG_ 2152128512 DSPMCA_DrvStyPrfMd2Avl 1;
BA_ "SignalType" SG_ 2152128512 DSPMCA_DrvStyPrfMd1Avl "BLN";
BA_ "PacketOrder" SG_ 2152128512 DSPMCA_DrvStyPrfMd1Avl 1;
BA_ "SignalLongName" SG_ 2152128512 DSPMCA_DrvStyPrfMd1Avl "Driving Style Performance Mode Customization Available : Driving Style Performance Mode 1 Available";
BA_ "VNSigAllNodes" SG_ 2152128512 DSPMCA_DrvStyPrfMd1Avl 1;
BA_ "SignalType" SG_ 2152128512 ACCPMCA_ACCPrfMd6Avl "BLN";
BA_ "PacketOrder" SG_ 2152128512 ACCPMCA_ACCPrfMd6Avl 6;
BA_ "SignalLongName" SG_ 2152128512 ACCPMCA_ACCPrfMd6Avl "Adaptive Cruise Control Performance Mode Customization Available : Adaptive Cruise Control Performance Mode 6 Available";
BA_ "VNSigAllNodes" SG_ 2152128512 ACCPMCA_ACCPrfMd6Avl 1;
BA_ "SignalType" SG_ 2152128512 ACCPMCA_ACCPrfMd5Avl "BLN";
BA_ "PacketOrder" SG_ 2152128512 ACCPMCA_ACCPrfMd5Avl 5;
BA_ "SignalLongName" SG_ 2152128512 ACCPMCA_ACCPrfMd5Avl "Adaptive Cruise Control Performance Mode Customization Available : Adaptive Cruise Control Performance Mode 5 Available";
BA_ "VNSigAllNodes" SG_ 2152128512 ACCPMCA_ACCPrfMd5Avl 1;
BA_ "SignalType" SG_ 2152128512 ACCPMCA_ACCPrfMd4Avl "BLN";
BA_ "PacketOrder" SG_ 2152128512 ACCPMCA_ACCPrfMd4Avl 4;
BA_ "SignalLongName" SG_ 2152128512 ACCPMCA_ACCPrfMd4Avl "Adaptive Cruise Control Performance Mode Customization Available : Adaptive Cruise Control Performance Mode 4 Available";
BA_ "VNSigAllNodes" SG_ 2152128512 ACCPMCA_ACCPrfMd4Avl 1;
BA_ "SignalType" SG_ 2152128512 ACCPMCA_ACCPrfMd3Avl "BLN";
BA_ "PacketOrder" SG_ 2152128512 ACCPMCA_ACCPrfMd3Avl 3;
BA_ "SignalLongName" SG_ 2152128512 ACCPMCA_ACCPrfMd3Avl "Adaptive Cruise Control Performance Mode Customization Available : Adaptive Cruise Control Performance Mode 3 Available";
BA_ "VNSigAllNodes" SG_ 2152128512 ACCPMCA_ACCPrfMd3Avl 1;
BA_ "SignalType" SG_ 2152128512 ACCPMCA_ACCPrfMd2Avl "BLN";
BA_ "PacketOrder" SG_ 2152128512 ACCPMCA_ACCPrfMd2Avl 2;
BA_ "SignalLongName" SG_ 2152128512 ACCPMCA_ACCPrfMd2Avl "Adaptive Cruise Control Performance Mode Customization Available : Adaptive Cruise Control Performance Mode 2 Available";
BA_ "VNSigAllNodes" SG_ 2152128512 ACCPMCA_ACCPrfMd2Avl 1;
BA_ "SignalType" SG_ 2152128512 ACCPMCA_ACCPrfMd1Avl "BLN";
BA_ "PacketOrder" SG_ 2152128512 ACCPMCA_ACCPrfMd1Avl 1;
BA_ "SignalLongName" SG_ 2152128512 ACCPMCA_ACCPrfMd1Avl "Adaptive Cruise Control Performance Mode Customization Available : Adaptive Cruise Control Performance Mode 1 Available";
BA_ "VNSigAllNodes" SG_ 2152128512 ACCPMCA_ACCPrfMd1Avl 1;
BA_ "GenSigSendType" SG_ 2152112128 PMVSS_Disps 10;
BA_ "GenSigSendOnInit" SG_ 2152112128 PMVSS_Disps 2;
BA_ "SignalType" SG_ 2152112128 PMVSS_Disps "ENM";
BA_ "PacketOrder" SG_ 2152112128 PMVSS_Disps 11;
BA_ "SignalLongName" SG_ 2152112128 PMVSS_Disps "Performance Mode Visualization Screen Status : Displays";
BA_ "VNSigAllNodes" SG_ 2152112128 PMVSS_Disps 1;
BA_ "GenSigSendType" SG_ 2152112128 PMVSS_Exhst 10;
BA_ "GenSigSendOnInit" SG_ 2152112128 PMVSS_Exhst 2;
BA_ "SignalType" SG_ 2152112128 PMVSS_Exhst "ENM";
BA_ "PacketOrder" SG_ 2152112128 PMVSS_Exhst 10;
BA_ "SignalLongName" SG_ 2152112128 PMVSS_Exhst "Performance Mode Visualization Screen Status : Exhaust";
BA_ "VNSigAllNodes" SG_ 2152112128 PMVSS_Exhst 1;
BA_ "GenSigSendType" SG_ 2152112128 PMVSS_PsngrSeat 10;
BA_ "GenSigSendOnInit" SG_ 2152112128 PMVSS_PsngrSeat 2;
BA_ "SignalType" SG_ 2152112128 PMVSS_PsngrSeat "ENM";
BA_ "PacketOrder" SG_ 2152112128 PMVSS_PsngrSeat 9;
BA_ "SignalLongName" SG_ 2152112128 PMVSS_PsngrSeat "Performance Mode Visualization Screen Status : Passenger Seat";
BA_ "VNSigAllNodes" SG_ 2152112128 PMVSS_PsngrSeat 1;
BA_ "GenSigSendType" SG_ 2152112128 PMVSS_DrvrSeat 10;
BA_ "GenSigSendOnInit" SG_ 2152112128 PMVSS_DrvrSeat 2;
BA_ "SignalType" SG_ 2152112128 PMVSS_DrvrSeat "ENM";
BA_ "PacketOrder" SG_ 2152112128 PMVSS_DrvrSeat 8;
BA_ "SignalLongName" SG_ 2152112128 PMVSS_DrvrSeat "Performance Mode Visualization Screen Status : Driver Seat";
BA_ "VNSigAllNodes" SG_ 2152112128 PMVSS_DrvrSeat 1;
BA_ "GenSigSendType" SG_ 2152112128 PMVSS_AdptCrsCnt 10;
BA_ "GenSigSendOnInit" SG_ 2152112128 PMVSS_AdptCrsCnt 2;
BA_ "SignalType" SG_ 2152112128 PMVSS_AdptCrsCnt "ENM";
BA_ "PacketOrder" SG_ 2152112128 PMVSS_AdptCrsCnt 7;
BA_ "SignalLongName" SG_ 2152112128 PMVSS_AdptCrsCnt "Performance Mode Visualization Screen Status : Adaptive Cruise Control";
BA_ "VNSigAllNodes" SG_ 2152112128 PMVSS_AdptCrsCnt 1;
BA_ "GenSigSendType" SG_ 2152112128 PMVSS_Drvln 10;
BA_ "GenSigSendOnInit" SG_ 2152112128 PMVSS_Drvln 2;
BA_ "SignalType" SG_ 2152112128 PMVSS_Drvln "ENM";
BA_ "PacketOrder" SG_ 2152112128 PMVSS_Drvln 6;
BA_ "SignalLongName" SG_ 2152112128 PMVSS_Drvln "Performance Mode Visualization Screen Status : Driveline";
BA_ "VNSigAllNodes" SG_ 2152112128 PMVSS_Drvln 1;
BA_ "GenSigSendType" SG_ 2152112128 PMVSS_Susp 10;
BA_ "GenSigSendOnInit" SG_ 2152112128 PMVSS_Susp 2;
BA_ "SignalType" SG_ 2152112128 PMVSS_Susp "ENM";
BA_ "PacketOrder" SG_ 2152112128 PMVSS_Susp 5;
BA_ "SignalLongName" SG_ 2152112128 PMVSS_Susp "Performance Mode Visualization Screen Status : Suspension";
BA_ "VNSigAllNodes" SG_ 2152112128 PMVSS_Susp 1;
BA_ "GenSigSendType" SG_ 2152112128 PMVSS_Strng 10;
BA_ "GenSigSendOnInit" SG_ 2152112128 PMVSS_Strng 2;
BA_ "SignalType" SG_ 2152112128 PMVSS_Strng "ENM";
BA_ "PacketOrder" SG_ 2152112128 PMVSS_Strng 4;
BA_ "SignalLongName" SG_ 2152112128 PMVSS_Strng "Performance Mode Visualization Screen Status : Steering";
BA_ "VNSigAllNodes" SG_ 2152112128 PMVSS_Strng 1;
BA_ "GenSigSendType" SG_ 2152112128 PMVSS_Trans 10;
BA_ "GenSigSendOnInit" SG_ 2152112128 PMVSS_Trans 2;
BA_ "SignalType" SG_ 2152112128 PMVSS_Trans "ENM";
BA_ "PacketOrder" SG_ 2152112128 PMVSS_Trans 3;
BA_ "SignalLongName" SG_ 2152112128 PMVSS_Trans "Performance Mode Visualization Screen Status : Transmission";
BA_ "VNSigAllNodes" SG_ 2152112128 PMVSS_Trans 1;
BA_ "GenSigSendType" SG_ 2152112128 PMVSS_Eng 10;
BA_ "GenSigSendOnInit" SG_ 2152112128 PMVSS_Eng 2;
BA_ "SignalType" SG_ 2152112128 PMVSS_Eng "ENM";
BA_ "PacketOrder" SG_ 2152112128 PMVSS_Eng 2;
BA_ "SignalLongName" SG_ 2152112128 PMVSS_Eng "Performance Mode Visualization Screen Status : Engine";
BA_ "VNSigAllNodes" SG_ 2152112128 PMVSS_Eng 1;
BA_ "GenSigSendType" SG_ 2152112128 PMVSS_Snd 10;
BA_ "GenSigSendOnInit" SG_ 2152112128 PMVSS_Snd 2;
BA_ "SignalType" SG_ 2152112128 PMVSS_Snd "ENM";
BA_ "PacketOrder" SG_ 2152112128 PMVSS_Snd 1;
BA_ "SignalLongName" SG_ 2152112128 PMVSS_Snd "Performance Mode Visualization Screen Status : Sound";
BA_ "VNSigAllNodes" SG_ 2152112128 PMVSS_Snd 1;
BA_ "GenSigSendType" SG_ 2152112128 PerfMdMainMenuType 10;
BA_ "GenSigSendOnInit" SG_ 2152112128 PerfMdMainMenuType 2;
BA_ "SignalType" SG_ 2152112128 PerfMdMainMenuType "ENM";
BA_ "SignalLongName" SG_ 2152112128 PerfMdMainMenuType "Performance Mode Main Menu Type";
BA_ "VNSigAllNodes" SG_ 2152112128 PerfMdMainMenuType 1;
BA_ "GenSigSendType" SG_ 2154299392 CrShrngVehChlngReq 10;
BA_ "VNSigIntermediate" SG_ 2154299392 CrShrngVehChlngReq 1;
BA_ "SignalType" SG_ 2154299392 CrShrngVehChlngReq "ENM";
BA_ "SignalLongName" SG_ 2154299392 CrShrngVehChlngReq "Car Sharing Vehicle Challenge Request";
BA_REL_ "GenSigSuprvResp" BU_SG_REL_ CSM_LE SG_ 2156298240 HVBSTLPC_MntOfHr 1;
BA_REL_ "GenSigSuprvResp" BU_SG_REL_ RadioHead_LE SG_ 2156298240 HVBSTLPC_MntOfHr 1;
BA_REL_ "GenSigSuprvResp" BU_SG_REL_ RadioHead_LE SG_ 2156298240 HVBSTLPC_MntOfHr 1;
BA_REL_ "GenSigSuprvResp" BU_SG_REL_ VCU_LE SG_ 2156298240 HVBSTLPC_MntOfHr 1;
BA_REL_ "GenSigSuprvResp" BU_SG_REL_ VCU_LE SG_ 2156298240 HVBSTLPC_MntOfHr 1;
BA_REL_ "GenSigSuprvResp" BU_SG_REL_ CSM_LE SG_ 2156298240 HVBSTLPC_HrOfDy 1;
BA_REL_ "GenSigSuprvResp" BU_SG_REL_ RadioHead_LE SG_ 2156298240 HVBSTLPC_HrOfDy 1;
BA_REL_ "GenSigSuprvResp" BU_SG_REL_ RadioHead_LE SG_ 2156298240 HVBSTLPC_HrOfDy 1;
BA_REL_ "GenSigSuprvResp" BU_SG_REL_ VCU_LE SG_ 2156298240 HVBSTLPC_HrOfDy 1;
BA_REL_ "GenSigSuprvResp" BU_SG_REL_ VCU_LE SG_ 2156298240 HVBSTLPC_HrOfDy 1;
BA_REL_ "GenSigSuprvResp" BU_SG_REL_ CSM_LE SG_ 2156298240 HVBSTLPC_DyOfWk 1;
BA_REL_ "GenSigSuprvResp" BU_SG_REL_ RadioHead_LE SG_ 2156298240 HVBSTLPC_DyOfWk 1;
BA_REL_ "GenSigSuprvResp" BU_SG_REL_ RadioHead_LE SG_ 2156298240 HVBSTLPC_DyOfWk 1;
BA_REL_ "GenSigSuprvResp" BU_SG_REL_ VCU_LE SG_ 2156298240 HVBSTLPC_DyOfWk 1;
BA_REL_ "GenSigSuprvResp" BU_SG_REL_ VCU_LE SG_ 2156298240 HVBSTLPC_DyOfWk 1;
BA_REL_ "GenSigSuprvResp" BU_SG_REL_ CSM_LE SG_ 2156298240 HVBSTHPC_MntOfHr 1;
BA_REL_ "GenSigSuprvResp" BU_SG_REL_ RadioHead_LE SG_ 2156298240 HVBSTHPC_MntOfHr 1;
BA_REL_ "GenSigSuprvResp" BU_SG_REL_ RadioHead_LE SG_ 2156298240 HVBSTHPC_MntOfHr 1;
BA_REL_ "GenSigSuprvResp" BU_SG_REL_ VCU_LE SG_ 2156298240 HVBSTHPC_MntOfHr 1;
BA_REL_ "GenSigSuprvResp" BU_SG_REL_ VCU_LE SG_ 2156298240 HVBSTHPC_MntOfHr 1;
BA_REL_ "GenSigSuprvResp" BU_SG_REL_ CSM_LE SG_ 2156298240 HVBSTHPC_HrOfDy 1;
BA_REL_ "GenSigSuprvResp" BU_SG_REL_ RadioHead_LE SG_ 2156298240 HVBSTHPC_HrOfDy 1;
BA_REL_ "GenSigSuprvResp" BU_SG_REL_ RadioHead_LE SG_ 2156298240 HVBSTHPC_HrOfDy 1;
BA_REL_ "GenSigSuprvResp" BU_SG_REL_ VCU_LE SG_ 2156298240 HVBSTHPC_HrOfDy 1;
BA_REL_ "GenSigSuprvResp" BU_SG_REL_ VCU_LE SG_ 2156298240 HVBSTHPC_HrOfDy 1;
BA_REL_ "GenSigSuprvResp" BU_SG_REL_ CSM_LE SG_ 2156298240 HVBSTHPC_DyOfWk 1;
BA_REL_ "GenSigSuprvResp" BU_SG_REL_ RadioHead_LE SG_ 2156298240 HVBSTHPC_DyOfWk 1;
BA_REL_ "GenSigSuprvResp" BU_SG_REL_ RadioHead_LE SG_ 2156298240 HVBSTHPC_DyOfWk 1;
BA_REL_ "GenSigSuprvResp" BU_SG_REL_ VCU_LE SG_ 2156298240 HVBSTHPC_DyOfWk 1;
BA_REL_ "GenSigSuprvResp" BU_SG_REL_ VCU_LE SG_ 2156298240 HVBSTHPC_DyOfWk 1;
BA_REL_ "GenSigSuprvResp" BU_SG_REL_ CSM_LE SG_ 2156298240 HVBCTLPC_MntOfHr 1;
BA_REL_ "GenSigSuprvResp" BU_SG_REL_ RadioHead_LE SG_ 2156298240 HVBCTLPC_MntOfHr 1;
BA_REL_ "GenSigSuprvResp" BU_SG_REL_ RadioHead_LE SG_ 2156298240 HVBCTLPC_MntOfHr 1;
BA_REL_ "GenSigSuprvResp" BU_SG_REL_ VCU_LE SG_ 2156298240 HVBCTLPC_MntOfHr 1;
BA_REL_ "GenSigSuprvResp" BU_SG_REL_ VCU_LE SG_ 2156298240 HVBCTLPC_MntOfHr 1;
BA_REL_ "GenSigSuprvResp" BU_SG_REL_ CSM_LE SG_ 2156298240 HVBCTLPC_HrOfDy 1;
BA_REL_ "GenSigSuprvResp" BU_SG_REL_ RadioHead_LE SG_ 2156298240 HVBCTLPC_HrOfDy 1;
BA_REL_ "GenSigSuprvResp" BU_SG_REL_ RadioHead_LE SG_ 2156298240 HVBCTLPC_HrOfDy 1;
BA_REL_ "GenSigSuprvResp" BU_SG_REL_ VCU_LE SG_ 2156298240 HVBCTLPC_HrOfDy 1;
BA_REL_ "GenSigSuprvResp" BU_SG_REL_ VCU_LE SG_ 2156298240 HVBCTLPC_HrOfDy 1;
BA_REL_ "GenSigSuprvResp" BU_SG_REL_ CSM_LE SG_ 2156298240 HVBCTLPC_DyOfWk 1;
BA_REL_ "GenSigSuprvResp" BU_SG_REL_ RadioHead_LE SG_ 2156298240 HVBCTLPC_DyOfWk 1;
BA_REL_ "GenSigSuprvResp" BU_SG_REL_ RadioHead_LE SG_ 2156298240 HVBCTLPC_DyOfWk 1;
BA_REL_ "GenSigSuprvResp" BU_SG_REL_ VCU_LE SG_ 2156298240 HVBCTLPC_DyOfWk 1;
BA_REL_ "GenSigSuprvResp" BU_SG_REL_ VCU_LE SG_ 2156298240 HVBCTLPC_DyOfWk 1;
BA_REL_ "GenSigSuprvResp" BU_SG_REL_ CSM_LE SG_ 2156298240 HVBCTHPC_MntOfHr 1;
BA_REL_ "GenSigSuprvResp" BU_SG_REL_ RadioHead_LE SG_ 2156298240 HVBCTHPC_MntOfHr 1;
BA_REL_ "GenSigSuprvResp" BU_SG_REL_ RadioHead_LE SG_ 2156298240 HVBCTHPC_MntOfHr 1;
BA_REL_ "GenSigSuprvResp" BU_SG_REL_ VCU_LE SG_ 2156298240 HVBCTHPC_MntOfHr 1;
BA_REL_ "GenSigSuprvResp" BU_SG_REL_ VCU_LE SG_ 2156298240 HVBCTHPC_MntOfHr 1;
BA_REL_ "GenSigSuprvResp" BU_SG_REL_ CSM_LE SG_ 2156298240 HVBCTHPC_HrOfDy 1;
BA_REL_ "GenSigSuprvResp" BU_SG_REL_ RadioHead_LE SG_ 2156298240 HVBCTHPC_HrOfDy 1;
BA_REL_ "GenSigSuprvResp" BU_SG_REL_ RadioHead_LE SG_ 2156298240 HVBCTHPC_HrOfDy 1;
BA_REL_ "GenSigSuprvResp" BU_SG_REL_ VCU_LE SG_ 2156298240 HVBCTHPC_HrOfDy 1;
BA_REL_ "GenSigSuprvResp" BU_SG_REL_ VCU_LE SG_ 2156298240 HVBCTHPC_HrOfDy 1;
BA_REL_ "GenSigSuprvResp" BU_SG_REL_ CSM_LE SG_ 2156298240 HVBCTHPC_DyOfWk 1;
BA_REL_ "GenSigSuprvResp" BU_SG_REL_ RadioHead_LE SG_ 2156298240 HVBCTHPC_DyOfWk 1;
BA_REL_ "GenSigSuprvResp" BU_SG_REL_ RadioHead_LE SG_ 2156298240 HVBCTHPC_DyOfWk 1;
BA_REL_ "GenSigSuprvResp" BU_SG_REL_ VCU_LE SG_ 2156298240 HVBCTHPC_DyOfWk 1;
BA_REL_ "GenSigSuprvResp" BU_SG_REL_ VCU_LE SG_ 2156298240 HVBCTHPC_DyOfWk 1;
BA_REL_ "GenSigSuprvResp" BU_SG_REL_ VCU_LE SG_ 2156331008 EUSD_MsrmntUnit 1;
BA_REL_ "GenSigSuprvResp" BU_SG_REL_ CSM_LE SG_ 2156331008 EUSD_MsrmntUnit 1;
BA_REL_ "GenSigSuprvResp" BU_SG_REL_ RadioHead_LE SG_ 2156331008 EUSD_MsrmntUnit 1;
BA_REL_ "GenSigSuprvResp" BU_SG_REL_ VCU_LE SG_ 2156331008 EUSD_MsrmntVal 1;
BA_REL_ "GenSigSuprvResp" BU_SG_REL_ CSM_LE SG_ 2156331008 EUSD_MsrmntVal 1;
BA_REL_ "GenSigSuprvResp" BU_SG_REL_ RadioHead_LE SG_ 2156331008 EUSD_MsrmntVal 1;
BA_REL_ "GenSigSuprvResp" BU_SG_REL_ CSM_LE SG_ 2156331008 HVDpltnMdMiCnfdcRg 1;
BA_REL_ "GenSigSuprvResp" BU_SG_REL_ RadioHead_LE SG_ 2156331008 HVDpltnMdMiCnfdcRg 1;
BA_REL_ "GenSigSuprvResp" BU_SG_REL_ RadioHead_LE SG_ 2156331008 HVDpltnMdMiCnfdcRg 1;
BA_REL_ "GenSigSuprvResp" BU_SG_REL_ VCU_LE SG_ 2156331008 HVDpltnMdMiCnfdcRg 1;
BA_REL_ "GenSigSuprvResp" BU_SG_REL_ VCU_LE SG_ 2156331008 HVDpltnMdMiCnfdcRg 1;
BA_REL_ "GenSigSuprvResp" BU_SG_REL_ CSM_LE SG_ 2156331008 HVDpltnMdMxCnfdcRg 1;
BA_REL_ "GenSigSuprvResp" BU_SG_REL_ RadioHead_LE SG_ 2156331008 HVDpltnMdMxCnfdcRg 1;
BA_REL_ "GenSigSuprvResp" BU_SG_REL_ RadioHead_LE SG_ 2156331008 HVDpltnMdMxCnfdcRg 1;
BA_REL_ "GenSigSuprvResp" BU_SG_REL_ VCU_LE SG_ 2156331008 HVDpltnMdMxCnfdcRg 1;
BA_REL_ "GenSigSuprvResp" BU_SG_REL_ VCU_LE SG_ 2156331008 HVDpltnMdMxCnfdcRg 1;
BA_REL_ "GenSigSuprvResp" BU_SG_REL_ CSM_LE SG_ 2158116864 HVBTBRCR_RtCHSlctTblRwStat 1;
BA_REL_ "GenSigSuprvResp" BU_SG_REL_ VCU_LE SG_ 2158116864 HVBTBRCR_RtCHSlctTblRwStat 1;
BA_REL_ "GenSigSuprvResp" BU_SG_REL_ VCU_LE SG_ 2158116864 HVBTBRCR_RtCHSlctTblRwStat 1;
BA_REL_ "GenSigSuprvResp" BU_SG_REL_ RadioHead_LE SG_ 2158116864 HVBTBRCR_RtCHSlctTblRwStat 1;
BA_REL_ "GenSigSuprvResp" BU_SG_REL_ RadioHead_LE SG_ 2158116864 HVBTBRCR_RtCHSlctTblRwStat 1;
BA_REL_ "GenSigSuprvResp" BU_SG_REL_ CSM_LE SG_ 2158116864 HVBTBRCR_RtChSlctStat 1;
BA_REL_ "GenSigSuprvResp" BU_SG_REL_ VCU_LE SG_ 2158116864 HVBTBRCR_RtChSlctStat 1;
BA_REL_ "GenSigSuprvResp" BU_SG_REL_ VCU_LE SG_ 2158116864 HVBTBRCR_RtChSlctStat 1;
BA_REL_ "GenSigSuprvResp" BU_SG_REL_ RadioHead_LE SG_ 2158116864 HVBTBRCR_RtChSlctStat 1;
BA_REL_ "GenSigSuprvResp" BU_SG_REL_ RadioHead_LE SG_ 2158116864 HVBTBRCR_RtChSlctStat 1;
BA_REL_ "GenSigSuprvResp" BU_SG_REL_ CSM_LE SG_ 2158116864 HVBTBRCR_RtChSlRtStat 1;
BA_REL_ "GenSigSuprvResp" BU_SG_REL_ VCU_LE SG_ 2158116864 HVBTBRCR_RtChSlRtStat 1;
BA_REL_ "GenSigSuprvResp" BU_SG_REL_ VCU_LE SG_ 2158116864 HVBTBRCR_RtChSlRtStat 1;
BA_REL_ "GenSigSuprvResp" BU_SG_REL_ RadioHead_LE SG_ 2158116864 HVBTBRCR_RtChSlRtStat 1;
BA_REL_ "GenSigSuprvResp" BU_SG_REL_ RadioHead_LE SG_ 2158116864 HVBTBRCR_RtChSlRtStat 1;
BA_REL_ "GenSigSuprvResp" BU_SG_REL_ CSM_LE SG_ 2158116864 HVBTBRCR_RtChSsnStat 1;
BA_REL_ "GenSigSuprvResp" BU_SG_REL_ VCU_LE SG_ 2158116864 HVBTBRCR_RtChSsnStat 1;
BA_REL_ "GenSigSuprvResp" BU_SG_REL_ VCU_LE SG_ 2158116864 HVBTBRCR_RtChSsnStat 1;
BA_REL_ "GenSigSuprvResp" BU_SG_REL_ RadioHead_LE SG_ 2158116864 HVBTBRCR_RtChSsnStat 1;
BA_REL_ "GenSigSuprvResp" BU_SG_REL_ RadioHead_LE SG_ 2158116864 HVBTBRCR_RtChSsnStat 1;
BA_REL_ "GenSigSuprvResp" BU_SG_REL_ CSM_LE SG_ 2158116864 HVBTBRCR_RtChMHRsp 1;
BA_REL_ "GenSigSuprvResp" BU_SG_REL_ VCU_LE SG_ 2158116864 HVBTBRCR_RtChMHRsp 1;
BA_REL_ "GenSigSuprvResp" BU_SG_REL_ VCU_LE SG_ 2158116864 HVBTBRCR_RtChMHRsp 1;
BA_REL_ "GenSigSuprvResp" BU_SG_REL_ RadioHead_LE SG_ 2158116864 HVBTBRCR_RtChMHRsp 1;
BA_REL_ "GenSigSuprvResp" BU_SG_REL_ RadioHead_LE SG_ 2158116864 HVBTBRCR_RtChMHRsp 1;
BA_REL_ "GenSigSuprvResp" BU_SG_REL_ CSM_LE SG_ 2158116864 HVBTBRCR_RtChHRsp 1;
BA_REL_ "GenSigSuprvResp" BU_SG_REL_ VCU_LE SG_ 2158116864 HVBTBRCR_RtChHRsp 1;
BA_REL_ "GenSigSuprvResp" BU_SG_REL_ VCU_LE SG_ 2158116864 HVBTBRCR_RtChHRsp 1;
BA_REL_ "GenSigSuprvResp" BU_SG_REL_ RadioHead_LE SG_ 2158116864 HVBTBRCR_RtChHRsp 1;
BA_REL_ "GenSigSuprvResp" BU_SG_REL_ RadioHead_LE SG_ 2158116864 HVBTBRCR_RtChHRsp 1;
BA_REL_ "GenSigSuprvResp" BU_SG_REL_ CSM_LE SG_ 2158116864 HVBTBRCR_RtChDStat 1;
BA_REL_ "GenSigSuprvResp" BU_SG_REL_ VCU_LE SG_ 2158116864 HVBTBRCR_RtChDStat 1;
BA_REL_ "GenSigSuprvResp" BU_SG_REL_ VCU_LE SG_ 2158116864 HVBTBRCR_RtChDStat 1;
BA_REL_ "GenSigSuprvResp" BU_SG_REL_ RadioHead_LE SG_ 2158116864 HVBTBRCR_RtChDStat 1;
BA_REL_ "GenSigSuprvResp" BU_SG_REL_ RadioHead_LE SG_ 2158116864 HVBTBRCR_RtChDStat 1;
BA_REL_ "GenSigSuprvResp" BU_SG_REL_ CSM_LE SG_ 2158116864 HVBTBDCRS_DlChSlctStat 1;
BA_REL_ "GenSigSuprvResp" BU_SG_REL_ VCU_LE SG_ 2158116864 HVBTBDCRS_DlChSlctStat 1;
BA_REL_ "GenSigSuprvResp" BU_SG_REL_ VCU_LE SG_ 2158116864 HVBTBDCRS_DlChSlctStat 1;
BA_REL_ "GenSigSuprvResp" BU_SG_REL_ RadioHead_LE SG_ 2158116864 HVBTBDCRS_DlChSlctStat 1;
BA_REL_ "GenSigSuprvResp" BU_SG_REL_ RadioHead_LE SG_ 2158116864 HVBTBDCRS_DlChSlctStat 1;
BA_REL_ "GenSigSuprvResp" BU_SG_REL_ CSM_LE SG_ 2158116864 HVBTBDCRS_DlChSsnStat 1;
BA_REL_ "GenSigSuprvResp" BU_SG_REL_ VCU_LE SG_ 2158116864 HVBTBDCRS_DlChSsnStat 1;
BA_REL_ "GenSigSuprvResp" BU_SG_REL_ VCU_LE SG_ 2158116864 HVBTBDCRS_DlChSsnStat 1;
BA_REL_ "GenSigSuprvResp" BU_SG_REL_ RadioHead_LE SG_ 2158116864 HVBTBDCRS_DlChSsnStat 1;
BA_REL_ "GenSigSuprvResp" BU_SG_REL_ RadioHead_LE SG_ 2158116864 HVBTBDCRS_DlChSsnStat 1;
BA_REL_ "GenSigSuprvResp" BU_SG_REL_ CSM_LE SG_ 2158116864 HVBTBDCRS_DlChMHRsp 1;
BA_REL_ "GenSigSuprvResp" BU_SG_REL_ VCU_LE SG_ 2158116864 HVBTBDCRS_DlChMHRsp 1;
BA_REL_ "GenSigSuprvResp" BU_SG_REL_ VCU_LE SG_ 2158116864 HVBTBDCRS_DlChMHRsp 1;
BA_REL_ "GenSigSuprvResp" BU_SG_REL_ RadioHead_LE SG_ 2158116864 HVBTBDCRS_DlChMHRsp 1;
BA_REL_ "GenSigSuprvResp" BU_SG_REL_ RadioHead_LE SG_ 2158116864 HVBTBDCRS_DlChMHRsp 1;
BA_REL_ "GenSigSuprvResp" BU_SG_REL_ CSM_LE SG_ 2158116864 HVBTBDCRS_DlChHRsp 1;
BA_REL_ "GenSigSuprvResp" BU_SG_REL_ VCU_LE SG_ 2158116864 HVBTBDCRS_DlChHRsp 1;
BA_REL_ "GenSigSuprvResp" BU_SG_REL_ VCU_LE SG_ 2158116864 HVBTBDCRS_DlChHRsp 1;
BA_REL_ "GenSigSuprvResp" BU_SG_REL_ RadioHead_LE SG_ 2158116864 HVBTBDCRS_DlChHRsp 1;
BA_REL_ "GenSigSuprvResp" BU_SG_REL_ RadioHead_LE SG_ 2158116864 HVBTBDCRS_DlChHRsp 1;
BA_REL_ "GenSigSuprvResp" BU_SG_REL_ CSM_LE SG_ 2158116864 HVBTBDCRS_DlChDStat 1;
BA_REL_ "GenSigSuprvResp" BU_SG_REL_ VCU_LE SG_ 2158116864 HVBTBDCRS_DlChDStat 1;
BA_REL_ "GenSigSuprvResp" BU_SG_REL_ VCU_LE SG_ 2158116864 HVBTBDCRS_DlChDStat 1;
BA_REL_ "GenSigSuprvResp" BU_SG_REL_ RadioHead_LE SG_ 2158116864 HVBTBDCRS_DlChDStat 1;
BA_REL_ "GenSigSuprvResp" BU_SG_REL_ RadioHead_LE SG_ 2158116864 HVBTBDCRS_DlChDStat 1;
BA_REL_ "GenSigSuprvResp" BU_SG_REL_ CSM_LE SG_ 2158116864 HVBatStrtTmDspFrmt 1;
BA_REL_ "GenSigSuprvResp" BU_SG_REL_ VCU_LE SG_ 2158116864 HVBatStrtTmDspFrmt 1;
BA_REL_ "GenSigSuprvResp" BU_SG_REL_ RadioHead_LE SG_ 2158116864 HVBatStrtTmDspFrmt 1;
BA_REL_ "GenSigSuprvResp" BU_SG_REL_ RadioHead_LE SG_ 2158116864 OBHVBCMinsRmng 1;
BA_REL_ "GenSigSuprvResp" BU_SG_REL_ VCU_LE SG_ 2158116864 OBHVBCMinsRmng 1;
BA_REL_ "GenSigSuprvResp" BU_SG_REL_ VCU_LE SG_ 2158116864 OBHVBCMinsRmng 1;
BA_REL_ "GenSigSuprvResp" BU_SG_REL_ IPC_LE SG_ 2158116864 OBHVBCMinsRmng 1;
BA_REL_ "GenSigSuprvResp" BU_SG_REL_ RadioHead_LE SG_ 2158116864 OBHVBCCompTmDispFrmt 1;
BA_REL_ "GenSigSuprvResp" BU_SG_REL_ VCU_LE SG_ 2158116864 OBHVBCCompTmDispFrmt 1;
BA_REL_ "GenSigSuprvResp" BU_SG_REL_ VCU_LE SG_ 2158116864 OBHVBCCompTmDispFrmt 1;
BA_REL_ "GenSigSuprvResp" BU_SG_REL_ IPC_LE SG_ 2158116864 OBHVBCCompTmDispFrmt 1;
BA_REL_ "GenSigSuprvResp" BU_SG_REL_ VCU_LE SG_ 2158149632 ECHGCD_XAxTkMrkInterv 1;
BA_REL_ "GenSigSuprvResp" BU_SG_REL_ CSM_LE SG_ 2158149632 ECHGCD_XAxTkMrkInterv 1;
BA_REL_ "GenSigSuprvResp" BU_SG_REL_ RadioHead_LE SG_ 2158149632 ECHGCD_XAxTkMrkInterv 1;
BA_REL_ "GenSigSuprvResp" BU_SG_REL_ VCU_LE SG_ 2158149632 ECHGCD_YAxMaxVal 1;
BA_REL_ "GenSigSuprvResp" BU_SG_REL_ CSM_LE SG_ 2158149632 ECHGCD_YAxMaxVal 1;
BA_REL_ "GenSigSuprvResp" BU_SG_REL_ RadioHead_LE SG_ 2158149632 ECHGCD_YAxMaxVal 1;
BA_REL_ "GenSigSuprvResp" BU_SG_REL_ VCU_LE SG_ 2158149632 ECHGCD_MeasUt 1;
BA_REL_ "GenSigSuprvResp" BU_SG_REL_ CSM_LE SG_ 2158149632 ECHGCD_MeasUt 1;
BA_REL_ "GenSigSuprvResp" BU_SG_REL_ RadioHead_LE SG_ 2158149632 ECHGCD_MeasUt 1;
BA_REL_ "GenSigSuprvResp" BU_SG_REL_ VCU_LE SG_ 2158149632 HVBTBSCR_SsnDyStat 1;
BA_REL_ "GenSigSuprvResp" BU_SG_REL_ VCU_LE SG_ 2158149632 HVBTBSCR_SsnDyStat 1;
BA_REL_ "GenSigSuprvResp" BU_SG_REL_ CSM_LE SG_ 2158149632 HVBTBSCR_SsnDyStat 1;
BA_REL_ "GenSigSuprvResp" BU_SG_REL_ RadioHead_LE SG_ 2158149632 HVBTBSCR_SsnDyStat 1;
BA_REL_ "GenSigSuprvResp" BU_SG_REL_ RadioHead_LE SG_ 2158149632 HVBTBSCR_SsnDyStat 1;
BA_REL_ "GenSigSuprvResp" BU_SG_REL_ VCU_LE SG_ 2158149632 HVBTBSCR_SsnStat 1;
BA_REL_ "GenSigSuprvResp" BU_SG_REL_ VCU_LE SG_ 2158149632 HVBTBSCR_SsnStat 1;
BA_REL_ "GenSigSuprvResp" BU_SG_REL_ CSM_LE SG_ 2158149632 HVBTBSCR_SsnStat 1;
BA_REL_ "GenSigSuprvResp" BU_SG_REL_ RadioHead_LE SG_ 2158149632 HVBTBSCR_SsnStat 1;
BA_REL_ "GenSigSuprvResp" BU_SG_REL_ RadioHead_LE SG_ 2158149632 HVBTBSCR_SsnStat 1;
BA_REL_ "GenSigSuprvResp" BU_SG_REL_ VCU_LE SG_ 2158149632 HVBTBSCR_SsnSlctStat 1;
BA_REL_ "GenSigSuprvResp" BU_SG_REL_ VCU_LE SG_ 2158149632 HVBTBSCR_SsnSlctStat 1;
BA_REL_ "GenSigSuprvResp" BU_SG_REL_ CSM_LE SG_ 2158149632 HVBTBSCR_SsnSlctStat 1;
BA_REL_ "GenSigSuprvResp" BU_SG_REL_ RadioHead_LE SG_ 2158149632 HVBTBSCR_SsnSlctStat 1;
BA_REL_ "GenSigSuprvResp" BU_SG_REL_ RadioHead_LE SG_ 2158149632 HVBTBSCR_SsnSlctStat 1;
BA_REL_ "GenSigSuprvResp" BU_SG_REL_ VCU_LE SG_ 2158149632 HVBTBSCR_SsnMthStat 1;
BA_REL_ "GenSigSuprvResp" BU_SG_REL_ VCU_LE SG_ 2158149632 HVBTBSCR_SsnMthStat 1;
BA_REL_ "GenSigSuprvResp" BU_SG_REL_ CSM_LE SG_ 2158149632 HVBTBSCR_SsnMthStat 1;
BA_REL_ "GenSigSuprvResp" BU_SG_REL_ RadioHead_LE SG_ 2158149632 HVBTBSCR_SsnMthStat 1;
BA_REL_ "GenSigSuprvResp" BU_SG_REL_ RadioHead_LE SG_ 2158149632 HVBTBSCR_SsnMthStat 1;
BA_REL_ "GenSigSuprvResp" BU_SG_REL_ VCU_LE SG_ 2158149632 HVBatTmBsChrgStRsp 1;
BA_REL_ "GenSigSuprvResp" BU_SG_REL_ VCU_LE SG_ 2158149632 HVBatTmBsChrgStRsp 1;
BA_REL_ "GenSigSuprvResp" BU_SG_REL_ CSM_LE SG_ 2158149632 HVBatTmBsChrgStRsp 1;
BA_REL_ "GenSigSuprvResp" BU_SG_REL_ RadioHead_LE SG_ 2158149632 HVBatTmBsChrgStRsp 1;
BA_REL_ "GenSigSuprvResp" BU_SG_REL_ RadioHead_LE SG_ 2158149632 HVBatTmBsChrgStRsp 1;
BA_REL_ "GenSigSuprvResp" BU_SG_REL_ VCU_LE SG_ 2158149632 HVBTBCRS_ChRtDStat 1;
BA_REL_ "GenSigSuprvResp" BU_SG_REL_ VCU_LE SG_ 2158149632 HVBTBCRS_ChRtDStat 1;
BA_REL_ "GenSigSuprvResp" BU_SG_REL_ CSM_LE SG_ 2158149632 HVBTBCRS_ChRtDStat 1;
BA_REL_ "GenSigSuprvResp" BU_SG_REL_ RadioHead_LE SG_ 2158149632 HVBTBCRS_ChRtDStat 1;
BA_REL_ "GenSigSuprvResp" BU_SG_REL_ RadioHead_LE SG_ 2158149632 HVBTBCRS_ChRtDStat 1;
BA_REL_ "GenSigSuprvResp" BU_SG_REL_ VCU_LE SG_ 2158149632 HVBTBCRS_ChRtSlctStat 1;
BA_REL_ "GenSigSuprvResp" BU_SG_REL_ VCU_LE SG_ 2158149632 HVBTBCRS_ChRtSlctStat 1;
BA_REL_ "GenSigSuprvResp" BU_SG_REL_ CSM_LE SG_ 2158149632 HVBTBCRS_ChRtSlctStat 1;
BA_REL_ "GenSigSuprvResp" BU_SG_REL_ RadioHead_LE SG_ 2158149632 HVBTBCRS_ChRtSlctStat 1;
BA_REL_ "GenSigSuprvResp" BU_SG_REL_ RadioHead_LE SG_ 2158149632 HVBTBCRS_ChRtSlctStat 1;
BA_REL_ "GenSigSuprvResp" BU_SG_REL_ VCU_LE SG_ 2158149632 HVBTBCRS_ChRtEnblStat 1;
BA_REL_ "GenSigSuprvResp" BU_SG_REL_ VCU_LE SG_ 2158149632 HVBTBCRS_ChRtEnblStat 1;
BA_REL_ "GenSigSuprvResp" BU_SG_REL_ CSM_LE SG_ 2158149632 HVBTBCRS_ChRtEnblStat 1;
BA_REL_ "GenSigSuprvResp" BU_SG_REL_ RadioHead_LE SG_ 2158149632 HVBTBCRS_ChRtEnblStat 1;
BA_REL_ "GenSigSuprvResp" BU_SG_REL_ RadioHead_LE SG_ 2158149632 HVBTBCRS_ChRtEnblStat 1;
BA_REL_ "GenSigSuprvResp" BU_SG_REL_ VCU_LE SG_ 2158149632 EgyCnsHstGphInsEgyCns 1;
BA_REL_ "GenSigSuprvResp" BU_SG_REL_ CSM_LE SG_ 2158149632 EgyCnsHstGphInsEgyCns 1;
BA_REL_ "GenSigSuprvResp" BU_SG_REL_ RadioHead_LE SG_ 2158149632 EgyCnsHstGphInsEgyCns 1;
BA_REL_ "GenSigSuprvResp" BU_SG_REL_ VCU_LE SG_ 2150432768 GrdBrkgAct 1;
BA_REL_ "GenSigSuprvResp" BU_SG_REL_ IPC_LE SG_ 2150432768 GrdBrkgAct 1;
BA_REL_ "GenSigSuprvResp" BU_SG_REL_ CSM_LE SG_ 2150432768 FuelTotCap 1;
BA_REL_ "GenSigSuprvResp" BU_SG_REL_ RadioHead_LE SG_ 2150432768 FuelTotCap 1;
BA_REL_ "GenSigSuprvResp" BU_SG_REL_ VCU_LE SG_ 2150432768 FuelTotCap 1;
BA_REL_ "GenSigSuprvResp" BU_SG_REL_ VCU_LE SG_ 2150432768 FuelTotCap 1;
BA_REL_ "GenSigSuprvResp" BU_SG_REL_ IPC_LE SG_ 2150432768 FuelTotCap 1;
BA_REL_ "GenSigSuprvResp" BU_SG_REL_ V2V_LE SG_ 2155413504 TireLRIPrs 1;
BA_REL_ "GenSigSuprvResp" BU_SG_REL_ TCP_LE SG_ 2155413504 TireLRIPrs 1;
BA_REL_ "GenSigSuprvResp" BU_SG_REL_ ONSTAR_LE SG_ 2155413504 TireLRIPrs 1;
BA_REL_ "GenSigSuprvResp" BU_SG_REL_ VCU_LE SG_ 2155413504 TireLRIPrs 1;
BA_REL_ "GenSigSuprvResp" BU_SG_REL_ IPC_LE SG_ 2155413504 TireLRIPrs 1;
BA_REL_ "GenSigSuprvResp" BU_SG_REL_ V2V_LE SG_ 2155413504 TireRRIPrs 1;
BA_REL_ "GenSigSuprvResp" BU_SG_REL_ TCP_LE SG_ 2155413504 TireRRIPrs 1;
BA_REL_ "GenSigSuprvResp" BU_SG_REL_ ONSTAR_LE SG_ 2155413504 TireRRIPrs 1;
BA_REL_ "GenSigSuprvResp" BU_SG_REL_ VCU_LE SG_ 2155413504 TireRRIPrs 1;
BA_REL_ "GenSigSuprvResp" BU_SG_REL_ IPC_LE SG_ 2155413504 TireRRIPrs 1;
BA_REL_ "GenSigSuprvResp" BU_SG_REL_ VCU_LE SG_ 2153381888 VltActRrAccUnavlIO 1;
BA_REL_ "GenSigSuprvResp" BU_SG_REL_ IPC_LE SG_ 2153381888 VltActRrAccUnavlIO 1;
BA_REL_ "GenSigSuprvResp" BU_SG_REL_ IPC_LE SG_ 2153381888 PwrLftgtMotStat 1;
BA_REL_ "GenSigSuprvResp" BU_SG_REL_ VCU_LE SG_ 2153381888 PwrLftgtMotStat 1;
BA_REL_ "GenSigSuprvResp" BU_SG_REL_ CSM_LE SG_ 2149908480 BrkPdlPos 1;
BA_REL_ "GenSigSuprvResp" BU_SG_REL_ RadioHead_LE SG_ 2149908480 BrkPdlPos 1;
BA_REL_ "GenSigSuprvResp" BU_SG_REL_ RadioHead_LE SG_ 2149908480 BrkPdlPos 1;
BA_REL_ "GenSigSuprvResp" BU_SG_REL_ VCU_LE SG_ 2149908480 BrkPdlPos 1;
BA_REL_ "GenSigSuprvResp" BU_SG_REL_ VCU_LE SG_ 2149908480 BrkPdlPos 1;
BA_REL_ "GenSigSuprvResp" BU_SG_REL_ VCU_LE SG_ 2149908480 BrkPdlPos 1;
BA_REL_ "GenSigSuprvResp" BU_SG_REL_ IPC_LE SG_ 2149908480 BrkPdlPos 1;
BA_REL_ "GenSigSuprvResp" BU_SG_REL_ VCU_LE SG_ 2149908480 BrkPedTrvlAchvd 1;
BA_REL_ "GenSigSuprvResp" BU_SG_REL_ IPC_LE SG_ 2149908480 BrkPedTrvlAchvd 1;
BA_REL_ "GenSigSuprvResp" BU_SG_REL_ VCU_LE SG_ 2149908480 BrkPedTrvlAchvdV 1;
BA_REL_ "GenSigSuprvResp" BU_SG_REL_ IPC_LE SG_ 2149908480 BrkPedTrvlAchvdV 1;
BA_REL_ "GenSigSuprvResp" BU_SG_REL_ CSM_LE SG_ 2150498304 EngCltTmp 1;
BA_REL_ "GenSigSuprvResp" BU_SG_REL_ RadioHead_LE SG_ 2150498304 EngCltTmp 1;
BA_REL_ "GenSigSuprvResp" BU_SG_REL_ RadioHead_LE SG_ 2150498304 EngCltTmp 1;
BA_REL_ "GenSigSuprvResp" BU_SG_REL_ VCU_LE SG_ 2150498304 EngCltTmp 1;
BA_REL_ "GenSigSuprvResp" BU_SG_REL_ VCU_LE SG_ 2150498304 EngCltTmp 1;
BA_REL_ "GenSigSuprvResp" BU_SG_REL_ CSM_LE SG_ 2154496000 TargaTopState 1;
BA_REL_ "GenSigSuprvResp" BU_SG_REL_ VCU_LE SG_ 2154496000 TargaTopState 1;
BA_REL_ "GenSigSuprvResp" BU_SG_REL_ VCU_LE SG_ 2154496000 TargaTopState 1;
BA_REL_ "GenSigSuprvResp" BU_SG_REL_ RadioHead_LE SG_ 2154496000 TargaTopState 1;
BA_REL_ "GenSigSuprvResp" BU_SG_REL_ RadioHead_LE SG_ 2154496000 TargaTopState 1;
BA_REL_ "GenSigSuprvResp" BU_SG_REL_ RCRM_LE SG_ 2154471424 RrClosAjarSwAct 1;
BA_REL_ "GenSigSuprvResp" BU_SG_REL_ CSM_LE SG_ 2154471424 RrClosAjarSwAct 1;
BA_REL_ "GenSigSuprvResp" BU_SG_REL_ RadioHead_LE SG_ 2154471424 RrClosAjarSwAct 1;
BA_REL_ "GenSigSuprvResp" BU_SG_REL_ RadioHead_LE SG_ 2154471424 RrClosAjarSwAct 1;
BA_REL_ "GenSigSuprvResp" BU_SG_REL_ VCU_LE SG_ 2154471424 RrClosAjarSwAct 1;
BA_REL_ "GenSigSuprvResp" BU_SG_REL_ VCU_LE SG_ 2154471424 RrClosAjarSwAct 1;
BA_REL_ "GenSigSuprvResp" BU_SG_REL_ VCU_LE SG_ 2151940096 EstIntRfSrfcTmp 1;
BA_REL_ "GenSigSuprvResp" BU_SG_REL_ CSM_LE SG_ 2151940096 EstIntRfSrfcTmp 1;
BA_REL_ "GenSigSuprvResp" BU_SG_REL_ RadioHead_LE SG_ 2151940096 EstIntRfSrfcTmp 1;
BA_REL_ "GenSigSuprvResp" BU_SG_REL_ VCU_LE SG_ 2151940096 EstBulkIntAirTmp 1;
BA_REL_ "GenSigSuprvResp" BU_SG_REL_ CSM_LE SG_ 2151940096 EstBulkIntAirTmp 1;
BA_REL_ "GenSigSuprvResp" BU_SG_REL_ RadioHead_LE SG_ 2151940096 EstBulkIntAirTmp 1;
BA_REL_ "GenSigSuprvResp" BU_SG_REL_ VCU_LE SG_ 2154987520 WrlsChrgSysChrgStat 1;
BA_REL_ "GenSigSuprvResp" BU_SG_REL_ CSM_LE SG_ 2154987520 WrlsChrgSysChrgStat 1;
BA_REL_ "GenSigSuprvResp" BU_SG_REL_ RadioHead_LE SG_ 2154987520 WrlsChrgSysChrgStat 1;
BA_REL_ "GenSigSuprvResp" BU_SG_REL_ V2V_LE SG_ 2154987520 HdSt 1;
BA_REL_ "GenSigSuprvResp" BU_SG_REL_ VCU_LE SG_ 2156314624 OffBrdCSFltDtctd 1;
BA_REL_ "GenSigSuprvResp" BU_SG_REL_ IPC_LE SG_ 2156314624 OffBrdCSFltDtctd 1;
BA_REL_ "GenSigSuprvResp" BU_SG_REL_ VCU_LE SG_ 2156314624 OBVhCsACChgRqBnVs 1;
BA_REL_ "GenSigSuprvResp" BU_SG_REL_ CSM_LE SG_ 2156314624 OBVhCsACChgRqBnVs 1;
BA_REL_ "GenSigSuprvResp" BU_SG_REL_ RadioHead_LE SG_ 2156314624 OBVhCsACChgRqBnVs 1;
BA_REL_ "GenSigSuprvResp" BU_SG_REL_ VCU_LE SG_ 2156314624 TODCNPDT_Min 1;
BA_REL_ "GenSigSuprvResp" BU_SG_REL_ VCU_LE SG_ 2156314624 TODCNPDT_Min 1;
BA_REL_ "GenSigSuprvResp" BU_SG_REL_ CSM_LE SG_ 2156314624 TODCNPDT_Min 1;
BA_REL_ "GenSigSuprvResp" BU_SG_REL_ RadioHead_LE SG_ 2156314624 TODCNPDT_Min 1;
BA_REL_ "GenSigSuprvResp" BU_SG_REL_ RadioHead_LE SG_ 2156314624 TODCNPDT_Min 1;
BA_REL_ "GenSigSuprvResp" BU_SG_REL_ VCU_LE SG_ 2156314624 TODCNPDT_Hr 1;
BA_REL_ "GenSigSuprvResp" BU_SG_REL_ VCU_LE SG_ 2156314624 TODCNPDT_Hr 1;
BA_REL_ "GenSigSuprvResp" BU_SG_REL_ CSM_LE SG_ 2156314624 TODCNPDT_Hr 1;
BA_REL_ "GenSigSuprvResp" BU_SG_REL_ RadioHead_LE SG_ 2156314624 TODCNPDT_Hr 1;
BA_REL_ "GenSigSuprvResp" BU_SG_REL_ RadioHead_LE SG_ 2156314624 TODCNPDT_Hr 1;
BA_REL_ "GenSigSuprvResp" BU_SG_REL_ VCU_LE SG_ 2156314624 TODCNPDT_DyOfWk 1;
BA_REL_ "GenSigSuprvResp" BU_SG_REL_ VCU_LE SG_ 2156314624 TODCNPDT_DyOfWk 1;
BA_REL_ "GenSigSuprvResp" BU_SG_REL_ CSM_LE SG_ 2156314624 TODCNPDT_DyOfWk 1;
BA_REL_ "GenSigSuprvResp" BU_SG_REL_ RadioHead_LE SG_ 2156314624 TODCNPDT_DyOfWk 1;
BA_REL_ "GenSigSuprvResp" BU_SG_REL_ RadioHead_LE SG_ 2156314624 TODCNPDT_DyOfWk 1;
BA_REL_ "GenSigSuprvResp" BU_SG_REL_ CSM_LE SG_ 2156314624 HVBatBlkSOC 1;
BA_REL_ "GenSigSuprvResp" BU_SG_REL_ RadioHead_LE SG_ 2156314624 HVBatBlkSOC 1;
BA_REL_ "GenSigSuprvResp" BU_SG_REL_ VCU_LE SG_ 2156314624 HVBatBlkSOC 1;
BA_REL_ "GenSigSuprvResp" BU_SG_REL_ VCU_LE SG_ 2156314624 HVBatBlkSOC 1;
BA_REL_ "GenSigSuprvResp" BU_SG_REL_ IPC_LE SG_ 2156314624 HVBatBlkSOC 1;
BA_REL_ "GenSigSuprvResp" BU_SG_REL_ TCP_LE SG_ 2156314624 TODCOpMd 1;
BA_REL_ "GenSigSuprvResp" BU_SG_REL_ ONSTAR_LE SG_ 2156314624 TODCOpMd 1;
BA_REL_ "GenSigSuprvResp" BU_SG_REL_ TCP_LE SG_ 2156314624 TODCDMPTO_TpOvR 1;
BA_REL_ "GenSigSuprvResp" BU_SG_REL_ ONSTAR_LE SG_ 2156314624 TODCDMPTO_TpOvR 1;
BA_REL_ "GenSigSuprvResp" BU_SG_REL_ CSM_LE SG_ 2156314624 TODCDMPTO_TpOvR 1;
BA_REL_ "GenSigSuprvResp" BU_SG_REL_ RadioHead_LE SG_ 2156314624 TODCDMPTO_TpOvR 1;
BA_REL_ "GenSigSuprvResp" BU_SG_REL_ RadioHead_LE SG_ 2156314624 TODCDMPTO_TpOvR 1;
BA_REL_ "GenSigSuprvResp" BU_SG_REL_ VCU_LE SG_ 2156314624 TODCDMPTO_TpOvR 1;
BA_REL_ "GenSigSuprvResp" BU_SG_REL_ VCU_LE SG_ 2156314624 TODCDMPTO_TpOvR 1;
BA_REL_ "GenSigSuprvResp" BU_SG_REL_ VCU_LE SG_ 2156314624 TODCDMPTO_TpOvR 1;
BA_REL_ "GenSigSuprvResp" BU_SG_REL_ IPC_LE SG_ 2156314624 TODCDMPTO_TpOvR 1;
BA_REL_ "GenSigSuprvResp" BU_SG_REL_ TCP_LE SG_ 2156314624 TODCDMPTO_CmPgR 1;
BA_REL_ "GenSigSuprvResp" BU_SG_REL_ ONSTAR_LE SG_ 2156314624 TODCDMPTO_CmPgR 1;
BA_REL_ "GenSigSuprvResp" BU_SG_REL_ CSM_LE SG_ 2156314624 TODCDMPTO_CmPgR 1;
BA_REL_ "GenSigSuprvResp" BU_SG_REL_ RadioHead_LE SG_ 2156314624 TODCDMPTO_CmPgR 1;
BA_REL_ "GenSigSuprvResp" BU_SG_REL_ RadioHead_LE SG_ 2156314624 TODCDMPTO_CmPgR 1;
BA_REL_ "GenSigSuprvResp" BU_SG_REL_ VCU_LE SG_ 2156314624 TODCDMPTO_CmPgR 1;
BA_REL_ "GenSigSuprvResp" BU_SG_REL_ VCU_LE SG_ 2156314624 TODCDMPTO_CmPgR 1;
BA_REL_ "GenSigSuprvResp" BU_SG_REL_ VCU_LE SG_ 2156314624 TODCDMPTO_CmPgR 1;
BA_REL_ "GenSigSuprvResp" BU_SG_REL_ IPC_LE SG_ 2156314624 TODCDMPTO_CmPgR 1;
BA_REL_ "GenSigSuprvResp" BU_SG_REL_ TCP_LE SG_ 2156314624 HVChrgSysStNot 1;
BA_REL_ "GenSigSuprvResp" BU_SG_REL_ ONSTAR_LE SG_ 2156314624 HVChrgSysStNot 1;
BA_REL_ "GenSigSuprvResp" BU_SG_REL_ TCP_LE SG_ 2156314624 HVChrgAbrtRsn 1;
BA_REL_ "GenSigSuprvResp" BU_SG_REL_ ONSTAR_LE SG_ 2156314624 HVChrgAbrtRsn 1;
BA_REL_ "GenSigSuprvResp" BU_SG_REL_ VCU_LE SG_ 2156314624 HVCSCLPD_UsrIntTyp 1;
BA_REL_ "GenSigSuprvResp" BU_SG_REL_ RadioHead_LE SG_ 2156314624 HVCSCLPD_UsrIntTyp 1;
BA_REL_ "GenSigSuprvResp" BU_SG_REL_ VCU_LE SG_ 2156314624 HVCSCLPD_RdCrntLv3 1;
BA_REL_ "GenSigSuprvResp" BU_SG_REL_ RadioHead_LE SG_ 2156314624 HVCSCLPD_RdCrntLv3 1;
BA_REL_ "GenSigSuprvResp" BU_SG_REL_ VCU_LE SG_ 2156314624 HVCSCLPD_RdCrntLv2 1;
BA_REL_ "GenSigSuprvResp" BU_SG_REL_ RadioHead_LE SG_ 2156314624 HVCSCLPD_RdCrntLv2 1;
BA_REL_ "GenSigSuprvResp" BU_SG_REL_ VCU_LE SG_ 2156314624 HVCSCLPD_RdCrntLv1 1;
BA_REL_ "GenSigSuprvResp" BU_SG_REL_ RadioHead_LE SG_ 2156314624 HVCSCLPD_RdCrntLv1 1;
BA_REL_ "GenSigSuprvResp" BU_SG_REL_ VCU_LE SG_ 2156314624 HVCSCLPD_NrmChrgC 1;
BA_REL_ "GenSigSuprvResp" BU_SG_REL_ RadioHead_LE SG_ 2156314624 HVCSCLPD_NrmChrgC 1;
BA_REL_ "GenSigSuprvResp" BU_SG_REL_ VCU_LE SG_ 2156314624 HVCSCLPD_ChgLvlPfS 1;
BA_REL_ "GenSigSuprvResp" BU_SG_REL_ RadioHead_LE SG_ 2156314624 HVCSCLPD_ChgLvlPfS 1;
BA_REL_ "GenSigSuprvResp" BU_SG_REL_ VCU_LE SG_ 2149761024 PsngStPerfMdCsCrStVal 1;
BA_REL_ "GenSigSuprvResp" BU_SG_REL_ CSM_LE SG_ 2149761024 PsngStPerfMdCsCrStVal 1;
BA_REL_ "GenSigSuprvResp" BU_SG_REL_ RadioHead_LE SG_ 2149761024 PsngStPerfMdCsCrStVal 1;
BA_REL_ "GenSigSuprvResp" BU_SG_REL_ VCU_LE SG_ 2149761024 PsngStPerfMdCsStAvl 1;
BA_REL_ "GenSigSuprvResp" BU_SG_REL_ CSM_LE SG_ 2149761024 PsngStPerfMdCsStAvl 1;
BA_REL_ "GenSigSuprvResp" BU_SG_REL_ RadioHead_LE SG_ 2149761024 PsngStPerfMdCsStAvl 1;
BA_REL_ "GenSigSuprvResp" BU_SG_REL_ VCU_LE SG_ 2149761024 ElvtdIdlCstCrStVal 1;
BA_REL_ "GenSigSuprvResp" BU_SG_REL_ IPC_LE SG_ 2149761024 ElvtdIdlCstCrStVal 1;
BA_REL_ "GenSigSuprvResp" BU_SG_REL_ VCU_LE SG_ 2149761024 TCTPIR_TnsEsClCDwT 1;
BA_REL_ "GenSigSuprvResp" BU_SG_REL_ IPC_LE SG_ 2149761024 TCTPIR_TnsEsClCDwT 1;
BA_REL_ "GenSigSuprvResp" BU_SG_REL_ VCU_LE SG_ 2149761024 TCTPIR_TnsEsClTmpD 1;
BA_REL_ "GenSigSuprvResp" BU_SG_REL_ IPC_LE SG_ 2149761024 TCTPIR_TnsEsClTmpD 1;
BA_REL_ "GenSigSuprvResp" BU_SG_REL_ VCU_LE SG_ 2149761024 TCTPIR_DrvNotfn 1;
BA_REL_ "GenSigSuprvResp" BU_SG_REL_ IPC_LE SG_ 2149761024 TCTPIR_DrvNotfn 1;
BA_REL_ "GenSigRxStartValue" BU_SG_REL_ VCU_LE SG_ 2149761024 TrlrStabAstActIO "0";
BA_REL_ "GenSigRxStartValue" BU_SG_REL_ IPC_LE SG_ 2149761024 TrlrStabAstActIO "0";
BA_REL_ "GenSigSuprvResp" BU_SG_REL_ VCU_LE SG_ 2149761024 ActVehAccel 1;
BA_REL_ "GenSigSuprvResp" BU_SG_REL_ IPC_LE SG_ 2149761024 ActVehAccel 1;
BA_REL_ "GenSigSuprvResp" BU_SG_REL_ VCU_LE SG_ 2151997440 DrvDrowSysIndRq 1;
BA_REL_ "GenSigSuprvResp" BU_SG_REL_ IPC_LE SG_ 2151997440 DrvDrowSysIndRq 1;
BA_REL_ "GenSigSuprvResp" BU_SG_REL_ VCU_LE SG_ 2151997440 DrvDrwDetCsCrStVal 1;
BA_REL_ "GenSigSuprvResp" BU_SG_REL_ CSM_LE SG_ 2151997440 DrvDrwDetCsCrStVal 1;
BA_REL_ "GenSigSuprvResp" BU_SG_REL_ RadioHead_LE SG_ 2151997440 DrvDrwDetCsCrStVal 1;
BA_REL_ "GenSigSuprvResp" BU_SG_REL_ VCU_LE SG_ 2151997440 DrvDrowDetCstStAvl 1;
BA_REL_ "GenSigSuprvResp" BU_SG_REL_ CSM_LE SG_ 2151997440 DrvDrowDetCstStAvl 1;
BA_REL_ "GenSigSuprvResp" BU_SG_REL_ RadioHead_LE SG_ 2151997440 DrvDrowDetCstStAvl 1;
BA_REL_ "GenSigSuprvResp" BU_SG_REL_ VCU_LE SG_ 2152128512 PSPMCA_PsngStPrfMd6Avl 1;
BA_REL_ "GenSigSuprvResp" BU_SG_REL_ CSM_LE SG_ 2152128512 PSPMCA_PsngStPrfMd6Avl 1;
BA_REL_ "GenSigSuprvResp" BU_SG_REL_ RadioHead_LE SG_ 2152128512 PSPMCA_PsngStPrfMd6Avl 1;
BA_REL_ "GenSigSuprvResp" BU_SG_REL_ VCU_LE SG_ 2152128512 PSPMCA_PsngStPrfMd5Avl 1;
BA_REL_ "GenSigSuprvResp" BU_SG_REL_ CSM_LE SG_ 2152128512 PSPMCA_PsngStPrfMd5Avl 1;
BA_REL_ "GenSigSuprvResp" BU_SG_REL_ RadioHead_LE SG_ 2152128512 PSPMCA_PsngStPrfMd5Avl 1;
BA_REL_ "GenSigSuprvResp" BU_SG_REL_ VCU_LE SG_ 2152128512 PSPMCA_PsngStPrfMd4Avl 1;
BA_REL_ "GenSigSuprvResp" BU_SG_REL_ CSM_LE SG_ 2152128512 PSPMCA_PsngStPrfMd4Avl 1;
BA_REL_ "GenSigSuprvResp" BU_SG_REL_ RadioHead_LE SG_ 2152128512 PSPMCA_PsngStPrfMd4Avl 1;
BA_REL_ "GenSigSuprvResp" BU_SG_REL_ VCU_LE SG_ 2152128512 PSPMCA_PsngStPrfMd3Avl 1;
BA_REL_ "GenSigSuprvResp" BU_SG_REL_ CSM_LE SG_ 2152128512 PSPMCA_PsngStPrfMd3Avl 1;
BA_REL_ "GenSigSuprvResp" BU_SG_REL_ RadioHead_LE SG_ 2152128512 PSPMCA_PsngStPrfMd3Avl 1;
BA_REL_ "GenSigSuprvResp" BU_SG_REL_ VCU_LE SG_ 2152128512 PSPMCA_PsngStPrfMd2Avl 1;
BA_REL_ "GenSigSuprvResp" BU_SG_REL_ CSM_LE SG_ 2152128512 PSPMCA_PsngStPrfMd2Avl 1;
BA_REL_ "GenSigSuprvResp" BU_SG_REL_ RadioHead_LE SG_ 2152128512 PSPMCA_PsngStPrfMd2Avl 1;
BA_REL_ "GenSigSuprvResp" BU_SG_REL_ VCU_LE SG_ 2152128512 PSPMCA_PsngStPrfMd1Avl 1;
BA_REL_ "GenSigSuprvResp" BU_SG_REL_ CSM_LE SG_ 2152128512 PSPMCA_PsngStPrfMd1Avl 1;
BA_REL_ "GenSigSuprvResp" BU_SG_REL_ RadioHead_LE SG_ 2152128512 PSPMCA_PsngStPrfMd1Avl 1;
BA_REL_ "GenSigSuprvResp" BU_SG_REL_ VCU_LE SG_ 2152128512 DSPMCA_DrvrStPrfMd6Avl 1;
BA_REL_ "GenSigSuprvResp" BU_SG_REL_ CSM_LE SG_ 2152128512 DSPMCA_DrvrStPrfMd6Avl 1;
BA_REL_ "GenSigSuprvResp" BU_SG_REL_ RadioHead_LE SG_ 2152128512 DSPMCA_DrvrStPrfMd6Avl 1;
BA_REL_ "GenSigSuprvResp" BU_SG_REL_ VCU_LE SG_ 2152128512 DSPMCA_DrvrStPrfMd5Avl 1;
BA_REL_ "GenSigSuprvResp" BU_SG_REL_ CSM_LE SG_ 2152128512 DSPMCA_DrvrStPrfMd5Avl 1;
BA_REL_ "GenSigSuprvResp" BU_SG_REL_ RadioHead_LE SG_ 2152128512 DSPMCA_DrvrStPrfMd5Avl 1;
BA_REL_ "GenSigSuprvResp" BU_SG_REL_ VCU_LE SG_ 2152128512 DSPMCA_DrvrStPrfMd4Avl 1;
BA_REL_ "GenSigSuprvResp" BU_SG_REL_ CSM_LE SG_ 2152128512 DSPMCA_DrvrStPrfMd4Avl 1;
BA_REL_ "GenSigSuprvResp" BU_SG_REL_ RadioHead_LE SG_ 2152128512 DSPMCA_DrvrStPrfMd4Avl 1;
BA_REL_ "GenSigSuprvResp" BU_SG_REL_ VCU_LE SG_ 2152128512 DSPMCA_DrvrStPrfMd3Avl 1;
BA_REL_ "GenSigSuprvResp" BU_SG_REL_ CSM_LE SG_ 2152128512 DSPMCA_DrvrStPrfMd3Avl 1;
BA_REL_ "GenSigSuprvResp" BU_SG_REL_ RadioHead_LE SG_ 2152128512 DSPMCA_DrvrStPrfMd3Avl 1;
BA_REL_ "GenSigSuprvResp" BU_SG_REL_ VCU_LE SG_ 2152128512 DSPMCA_DrvrStPrfMd2Avl 1;
BA_REL_ "GenSigSuprvResp" BU_SG_REL_ CSM_LE SG_ 2152128512 DSPMCA_DrvrStPrfMd2Avl 1;
BA_REL_ "GenSigSuprvResp" BU_SG_REL_ RadioHead_LE SG_ 2152128512 DSPMCA_DrvrStPrfMd2Avl 1;
BA_REL_ "GenSigSuprvResp" BU_SG_REL_ VCU_LE SG_ 2152128512 DSPMCA_DrvrStPrfMd1Avl 1;
BA_REL_ "GenSigSuprvResp" BU_SG_REL_ CSM_LE SG_ 2152128512 DSPMCA_DrvrStPrfMd1Avl 1;
BA_REL_ "GenSigSuprvResp" BU_SG_REL_ RadioHead_LE SG_ 2152128512 DSPMCA_DrvrStPrfMd1Avl 1;
BA_REL_ "GenSigSuprvResp" BU_SG_REL_ VCU_LE SG_ 2152128512 DSPMCA_DrvStyPrfMd7Avl 1;
BA_REL_ "GenSigSuprvResp" BU_SG_REL_ CSM_LE SG_ 2152128512 DSPMCA_DrvStyPrfMd7Avl 1;
BA_REL_ "GenSigSuprvResp" BU_SG_REL_ RadioHead_LE SG_ 2152128512 DSPMCA_DrvStyPrfMd7Avl 1;
BA_REL_ "GenSigSuprvResp" BU_SG_REL_ VCU_LE SG_ 2152128512 DSPMCA_DrvStyPrfMd6Avl 1;
BA_REL_ "GenSigSuprvResp" BU_SG_REL_ CSM_LE SG_ 2152128512 DSPMCA_DrvStyPrfMd6Avl 1;
BA_REL_ "GenSigSuprvResp" BU_SG_REL_ RadioHead_LE SG_ 2152128512 DSPMCA_DrvStyPrfMd6Avl 1;
BA_REL_ "GenSigSuprvResp" BU_SG_REL_ VCU_LE SG_ 2152128512 DSPMCA_DrvStyPrfMd5Avl 1;
BA_REL_ "GenSigSuprvResp" BU_SG_REL_ CSM_LE SG_ 2152128512 DSPMCA_DrvStyPrfMd5Avl 1;
BA_REL_ "GenSigSuprvResp" BU_SG_REL_ RadioHead_LE SG_ 2152128512 DSPMCA_DrvStyPrfMd5Avl 1;
BA_REL_ "GenSigSuprvResp" BU_SG_REL_ VCU_LE SG_ 2152128512 DSPMCA_DrvStyPrfMd4Avl 1;
BA_REL_ "GenSigSuprvResp" BU_SG_REL_ CSM_LE SG_ 2152128512 DSPMCA_DrvStyPrfMd4Avl 1;
BA_REL_ "GenSigSuprvResp" BU_SG_REL_ RadioHead_LE SG_ 2152128512 DSPMCA_DrvStyPrfMd4Avl 1;
BA_REL_ "GenSigSuprvResp" BU_SG_REL_ VCU_LE SG_ 2152128512 DSPMCA_DrvStyPrfMd3Avl 1;
BA_REL_ "GenSigSuprvResp" BU_SG_REL_ CSM_LE SG_ 2152128512 DSPMCA_DrvStyPrfMd3Avl 1;
BA_REL_ "GenSigSuprvResp" BU_SG_REL_ RadioHead_LE SG_ 2152128512 DSPMCA_DrvStyPrfMd3Avl 1;
BA_REL_ "GenSigSuprvResp" BU_SG_REL_ VCU_LE SG_ 2152128512 DSPMCA_DrvStyPrfMd2Avl 1;
BA_REL_ "GenSigSuprvResp" BU_SG_REL_ CSM_LE SG_ 2152128512 DSPMCA_DrvStyPrfMd2Avl 1;
BA_REL_ "GenSigSuprvResp" BU_SG_REL_ RadioHead_LE SG_ 2152128512 DSPMCA_DrvStyPrfMd2Avl 1;
BA_REL_ "GenSigSuprvResp" BU_SG_REL_ VCU_LE SG_ 2152128512 DSPMCA_DrvStyPrfMd1Avl 1;
BA_REL_ "GenSigSuprvResp" BU_SG_REL_ CSM_LE SG_ 2152128512 DSPMCA_DrvStyPrfMd1Avl 1;
BA_REL_ "GenSigSuprvResp" BU_SG_REL_ RadioHead_LE SG_ 2152128512 DSPMCA_DrvStyPrfMd1Avl 1;
BA_REL_ "GenSigSuprvResp" BU_SG_REL_ VCU_LE SG_ 2152128512 ACCPMCA_ACCPrfMd6Avl 1;
BA_REL_ "GenSigSuprvResp" BU_SG_REL_ CSM_LE SG_ 2152128512 ACCPMCA_ACCPrfMd6Avl 1;
BA_REL_ "GenSigSuprvResp" BU_SG_REL_ RadioHead_LE SG_ 2152128512 ACCPMCA_ACCPrfMd6Avl 1;
BA_REL_ "GenSigSuprvResp" BU_SG_REL_ VCU_LE SG_ 2152128512 ACCPMCA_ACCPrfMd5Avl 1;
BA_REL_ "GenSigSuprvResp" BU_SG_REL_ CSM_LE SG_ 2152128512 ACCPMCA_ACCPrfMd5Avl 1;
BA_REL_ "GenSigSuprvResp" BU_SG_REL_ RadioHead_LE SG_ 2152128512 ACCPMCA_ACCPrfMd5Avl 1;
BA_REL_ "GenSigSuprvResp" BU_SG_REL_ VCU_LE SG_ 2152128512 ACCPMCA_ACCPrfMd4Avl 1;
BA_REL_ "GenSigSuprvResp" BU_SG_REL_ CSM_LE SG_ 2152128512 ACCPMCA_ACCPrfMd4Avl 1;
BA_REL_ "GenSigSuprvResp" BU_SG_REL_ RadioHead_LE SG_ 2152128512 ACCPMCA_ACCPrfMd4Avl 1;
BA_REL_ "GenSigSuprvResp" BU_SG_REL_ VCU_LE SG_ 2152128512 ACCPMCA_ACCPrfMd3Avl 1;
BA_REL_ "GenSigSuprvResp" BU_SG_REL_ CSM_LE SG_ 2152128512 ACCPMCA_ACCPrfMd3Avl 1;
BA_REL_ "GenSigSuprvResp" BU_SG_REL_ RadioHead_LE SG_ 2152128512 ACCPMCA_ACCPrfMd3Avl 1;
BA_REL_ "GenSigSuprvResp" BU_SG_REL_ VCU_LE SG_ 2152128512 ACCPMCA_ACCPrfMd2Avl 1;
BA_REL_ "GenSigSuprvResp" BU_SG_REL_ CSM_LE SG_ 2152128512 ACCPMCA_ACCPrfMd2Avl 1;
BA_REL_ "GenSigSuprvResp" BU_SG_REL_ RadioHead_LE SG_ 2152128512 ACCPMCA_ACCPrfMd2Avl 1;
BA_REL_ "GenSigSuprvResp" BU_SG_REL_ VCU_LE SG_ 2152128512 ACCPMCA_ACCPrfMd1Avl 1;
BA_REL_ "GenSigSuprvResp" BU_SG_REL_ CSM_LE SG_ 2152128512 ACCPMCA_ACCPrfMd1Avl 1;
BA_REL_ "GenSigSuprvResp" BU_SG_REL_ RadioHead_LE SG_ 2152128512 ACCPMCA_ACCPrfMd1Avl 1;
BA_REL_ "GenSigSuprvResp" BU_SG_REL_ VCU_LE SG_ 2152112128 PMVSS_Disps 1;
BA_REL_ "GenSigSuprvResp" BU_SG_REL_ CSM_LE SG_ 2152112128 PMVSS_Disps 1;
BA_REL_ "GenSigSuprvResp" BU_SG_REL_ RadioHead_LE SG_ 2152112128 PMVSS_Disps 1;
BA_REL_ "GenSigSuprvResp" BU_SG_REL_ VCU_LE SG_ 2152112128 PMVSS_Exhst 1;
BA_REL_ "GenSigSuprvResp" BU_SG_REL_ CSM_LE SG_ 2152112128 PMVSS_Exhst 1;
BA_REL_ "GenSigSuprvResp" BU_SG_REL_ RadioHead_LE SG_ 2152112128 PMVSS_Exhst 1;
BA_REL_ "GenSigSuprvResp" BU_SG_REL_ VCU_LE SG_ 2152112128 PMVSS_PsngrSeat 1;
BA_REL_ "GenSigSuprvResp" BU_SG_REL_ CSM_LE SG_ 2152112128 PMVSS_PsngrSeat 1;
BA_REL_ "GenSigSuprvResp" BU_SG_REL_ RadioHead_LE SG_ 2152112128 PMVSS_PsngrSeat 1;
BA_REL_ "GenSigSuprvResp" BU_SG_REL_ VCU_LE SG_ 2152112128 PMVSS_DrvrSeat 1;
BA_REL_ "GenSigSuprvResp" BU_SG_REL_ CSM_LE SG_ 2152112128 PMVSS_DrvrSeat 1;
BA_REL_ "GenSigSuprvResp" BU_SG_REL_ RadioHead_LE SG_ 2152112128 PMVSS_DrvrSeat 1;
BA_REL_ "GenSigSuprvResp" BU_SG_REL_ VCU_LE SG_ 2152112128 PMVSS_AdptCrsCnt 1;
BA_REL_ "GenSigSuprvResp" BU_SG_REL_ CSM_LE SG_ 2152112128 PMVSS_AdptCrsCnt 1;
BA_REL_ "GenSigSuprvResp" BU_SG_REL_ RadioHead_LE SG_ 2152112128 PMVSS_AdptCrsCnt 1;
BA_REL_ "GenSigSuprvResp" BU_SG_REL_ VCU_LE SG_ 2152112128 PMVSS_Drvln 1;
BA_REL_ "GenSigSuprvResp" BU_SG_REL_ CSM_LE SG_ 2152112128 PMVSS_Drvln 1;
BA_REL_ "GenSigSuprvResp" BU_SG_REL_ RadioHead_LE SG_ 2152112128 PMVSS_Drvln 1;
BA_REL_ "GenSigSuprvResp" BU_SG_REL_ VCU_LE SG_ 2152112128 PMVSS_Susp 1;
BA_REL_ "GenSigSuprvResp" BU_SG_REL_ CSM_LE SG_ 2152112128 PMVSS_Susp 1;
BA_REL_ "GenSigSuprvResp" BU_SG_REL_ RadioHead_LE SG_ 2152112128 PMVSS_Susp 1;
BA_REL_ "GenSigSuprvResp" BU_SG_REL_ VCU_LE SG_ 2152112128 PMVSS_Strng 1;
BA_REL_ "GenSigSuprvResp" BU_SG_REL_ CSM_LE SG_ 2152112128 PMVSS_Strng 1;
BA_REL_ "GenSigSuprvResp" BU_SG_REL_ RadioHead_LE SG_ 2152112128 PMVSS_Strng 1;
BA_REL_ "GenSigSuprvResp" BU_SG_REL_ VCU_LE SG_ 2152112128 PMVSS_Trans 1;
BA_REL_ "GenSigSuprvResp" BU_SG_REL_ CSM_LE SG_ 2152112128 PMVSS_Trans 1;
BA_REL_ "GenSigSuprvResp" BU_SG_REL_ RadioHead_LE SG_ 2152112128 PMVSS_Trans 1;
BA_REL_ "GenSigSuprvResp" BU_SG_REL_ VCU_LE SG_ 2152112128 PMVSS_Eng 1;
BA_REL_ "GenSigSuprvResp" BU_SG_REL_ CSM_LE SG_ 2152112128 PMVSS_Eng 1;
BA_REL_ "GenSigSuprvResp" BU_SG_REL_ RadioHead_LE SG_ 2152112128 PMVSS_Eng 1;
BA_REL_ "GenSigSuprvResp" BU_SG_REL_ VCU_LE SG_ 2152112128 PMVSS_Snd 1;
BA_REL_ "GenSigSuprvResp" BU_SG_REL_ CSM_LE SG_ 2152112128 PMVSS_Snd 1;
BA_REL_ "GenSigSuprvResp" BU_SG_REL_ RadioHead_LE SG_ 2152112128 PMVSS_Snd 1;
BA_REL_ "GenSigSuprvResp" BU_SG_REL_ VCU_LE SG_ 2152112128 PerfMdMainMenuType 1;
BA_REL_ "GenSigSuprvResp" BU_SG_REL_ CSM_LE SG_ 2152112128 PerfMdMainMenuType 1;
BA_REL_ "GenSigSuprvResp" BU_SG_REL_ RadioHead_LE SG_ 2152112128 PerfMdMainMenuType 1;
VAL_ 2156298240 HTRActvIndOn 1 "true" 0 "false" ;
VAL_ 2156298240 HVBSTLPC_DyOfWk 0 "Unknown" 1 "Sunday" 2 "Monday" 3 "Tuesday" 4 "Wednesday" 5 "Thursday" 6 "Friday" 7 "Saturday" ;
VAL_ 2156298240 HVBSTHPC_DyOfWk 0 "Unknown" 1 "Sunday" 2 "Monday" 3 "Tuesday" 4 "Wednesday" 5 "Thursday" 6 "Friday" 7 "Saturday" ;
VAL_ 2156298240 HVBCTLPC_DyOfWk 0 "Unknown" 1 "Sunday" 2 "Monday" 3 "Tuesday" 4 "Wednesday" 5 "Thursday" 6 "Friday" 7 "Saturday" ;
VAL_ 2156298240 HVBCTHPC_DyOfWk 0 "Unknown" 1 "Sunday" 2 "Monday" 3 "Tuesday" 4 "Wednesday" 5 "Thursday" 6 "Friday" 7 "Saturday" ;
VAL_ 2156298240 InvldHMIEtrIO 1 "true" 0 "false" ;
VAL_ 2156298240 InsfcntTmTFlChrgIO 1 "true" 0 "false" ;
VAL_ 2156298240 HVBatChrgCrdAlrtReq 0 "None" 1 "Pedestrian" 2 "Theft" ;
VAL_ 2156298240 HVCSDTES_NPDTIO 1 "true" 0 "false" ;
VAL_ 2156298240 HVCSDTES_LoPwrCIO 1 "true" 0 "false" ;
VAL_ 2156298240 HVCSDTES_HiPwrCIO 1 "true" 0 "false" ;
VAL_ 2156331008 EUSD_MsrmntUnit 3 "Unused and Reserved 1" 2 "Unitless Score" 1 "km" 0 "No Action" ;
VAL_ 2156331008 LwRngLVLdShdRq 0 "No Load Shedding" 1 "Load Shed Level1" 2 "Load Shed Level2" 3 "Load Shed Level3" ;
VAL_ 2158116864 HVBatOvrhtdRdIO 1 "true" 0 "false" ;
VAL_ 2158116864 SrvcHghVltBatIndReq 3 "Unused and Reserved 1" 2 "No Restart" 1 "Shut Down Soon" 0 "No Indication" ;
VAL_ 2158116864 ChrgStPkInScnActIO 1 "true" 0 "false" ;
VAL_ 2158116864 HVBTBRCR_RtChSlctStat 0 "No Action" 1 "Charge Start" 2 "Charge End" 3 "Charge Start Invalid" 4 "Charge End Invalid" ;
VAL_ 2158116864 HVBTBRCR_RtChSlRtStat 0 "No Action" 1 "Low Rate" 2 "Medium Rate" 3 "High Rate" 4 "Reserved 1" 5 "Invalid Rate" ;
VAL_ 2158116864 HVBTBRCR_RtChSsnStat 3 "Yearly" 0 "No Action" 1 "Summer" 2 "Winter" ;
VAL_ 2158116864 HVBTBRCR_RtChDStat 0 "No Action" 1 "Sunday" 2 "Monday" 3 "Tuesday" 4 "Wednsday" 5 "Thursday" 6 "Friday" 7 "Saturday" 8 "All Days Same" 9 "Mon - Fri Same" 10 "Sat & Sun Same" ;
VAL_ 2158116864 HVBTBDCRS_DlChSlctStat 0 "No Action" 1 "Departure Time 1" 2 "Reserved" 3 "Departure Time 1 Invalid" 4 "Reserved" 5 "Departure Time 2" 6 "Reserved" 7 "Departure Time 2 Invalid" 8 "Reserved" ;
VAL_ 2158116864 HVBTBDCRS_DlChSsnStat 3 "Yearly" 0 "No Action" 1 "Summer" 2 "Winter" ;
VAL_ 2158116864 HVBTBDCRS_DlChDStat 0 "No Action" 1 "Sunday" 2 "Monday" 3 "Tuesday" 4 "Wednsday" 5 "Thursday" 6 "Friday" 7 "Saturday" 8 "All Days Same" 9 "Mon - Fri Same" 10 "Sat & Sun Same" ;
VAL_ 2158116864 HVBatStrtTmDspFrmt 4 "Display Start Time On Cord And Station" 3 "Display Now On Cord And Station" 2 "Display Now On Station Only" 1 "Display Now On Cord Only" 0 "No Action" ;
VAL_ 2158116864 OBHVBCCompTmDispFrmt 2 "Display Remaining Minutes To Complete" 1 "Display Completion Time" 0 "No Action" ;
VAL_ 2158149632 ECHGCD_XAxTkMrkInterv 7 "100" 6 "80" 5 "50" 4 "20" 3 "10" 2 "5" 1 "1" 0 "0.5" ;
VAL_ 2158149632 ECHGCD_MeasUt 15 "Unused and Reserved 7" 14 "Unused and Reserved 6" 13 "Unused and Reserved 5" 12 "Unused and Reserved 4" 11 "Unused and Reserved 3" 10 "Unused and Reserved 2" 9 "Unused and  Reserved 1" 8 "km per L e Combined" 7 "L per 100km e Combined" 6 "MPGe Combined" 5 "L per 100km" 4 "mi per gal" 3 "km per L" 2 "kWh per 100km" 1 "mi per kWh" 0 "km per kWh" ;
VAL_ 2158149632 HVBTBSCR_SsnStat 3 "Yearly" 0 "No Action" 1 "Summer" 2 "Winter" ;
VAL_ 2158149632 HVBTBSCR_SsnSlctStat 0 "No Action" 1 "Selected Season" 2 "Start Season" 3 "End Season" ;
VAL_ 2158149632 HVBTBSCR_SsnMthStat 0 "No Action" 1 "January" 2 "February" 3 "Mars" 4 "April" 5 "May" 6 "June" 7 "July" 8 "August" 9 "September" 10 "October" 11 "November" 12 "December" ;
VAL_ 2158149632 HVBatTmBsChrgStRsp 0 "No Action" 1 "Charge Now" 2 "Delayed Charge" 3 "Rate Based Charge" ;
VAL_ 2158149632 HVBTBCRS_ChRtDStat 0 "No Action" 1 "Sunday" 2 "Monday" 3 "Tuesday" 4 "Wednsday" 5 "Thursday" 6 "Friday" 7 "Saturday" 8 "All Days Same" 9 "Mon - Fri Same" 10 "Sat & Sun Same" ;
VAL_ 2158149632 HVBTBCRS_ChRtSlctStat 0 "No Action" 1 "Low Rate" 2 "Medium Rate" 3 "High Rate" ;
VAL_ 2158149632 HVBTBCRS_ChRtEnblStat 0 "No Action" 1 "Enabled" 2 "Disabled" ;
VAL_ 2158149632 HVBatCrgDspStat 0 "Inactive" 1 "Pending" 2 "Active Charging" 3 "Complete" 4 "Faulted" ;
VAL_ 2150432768 CbnHtrWrmUpIO 1 "true" 0 "false" ;
VAL_ 2150432768 EngManfldAirTempCrtdV 1 "Invalid" 0 "Valid" ;
VAL_ 2150432768 GrdBrkgAct 1 "true" 0 "false" ;
VAL_ 2150432768 FuelFltLifRstPerf 1 "true" 0 "false" ;
VAL_ 2150432768 EngShtdwnPndgIO 1 "true" 0 "false" ;
VAL_ 2150432768 GenFldDutCycV 1 "Invalid" 0 "Valid" ;
VAL_ 2150432768 TransOilTempSensPres 1 "true" 0 "false" ;
VAL_ 2150432768 TrnsNEmsRltMalfActv 1 "true" 0 "false" ;
VAL_ 2150432768 TrnEmsMlfAtv 1 "true" 0 "false" ;
VAL_ 2150432768 TrnsThrmlMngmntStat 2 "Driver Intervention Requested" 1 "Countermeasures Active" 0 "Normal" ;
VAL_ 2150432768 PTHiElecLdReqd 1 "true" 0 "false" ;
VAL_ 2155413504 TireLRIPrsV 1 "Invalid" 0 "Valid" ;
VAL_ 2155413504 TireLRIPrsStat 5 "High" 4 "Low Extended Mobility" 3 "Low" 2 "Low Service Now" 1 "Nominal" 0 "Unknown" ;
VAL_ 2155413504 TireRRIPrsV 1 "Invalid" 0 "Valid" ;
VAL_ 2155413504 TireRRIPrsStat 5 "High" 4 "Low Extended Mobility" 3 "Low" 2 "Low Service Now" 1 "Nominal" 0 "Unknown" ;
VAL_ 2155413504 PsvLckngReqd 1 "true" 0 "false" ;
VAL_ 2155413504 DrvrDrKeyCylUlkSwAct 1 "true" 0 "false" ;
VAL_ 2155413504 DrvrDrKeyCylUlkSwActV 1 "Invalid" 0 "Valid" ;
VAL_ 2154225664 RLDrHndleSwAtv 1 "true" 0 "false" ;
VAL_ 2154225664 RRDrHndleSwAtv 1 "true" 0 "false" ;
VAL_ 2154225664 RCHndleSwAtv 1 "true" 0 "false" ;
VAL_ 2154225664 PasDrHndleSwAtv 1 "true" 0 "false" ;
VAL_ 2154225664 DrvDrHndleSwAtv 1 "true" 0 "false" ;
VAL_ 2151481344 HdUpDsplyUnblIO 1 "true" 0 "false" ;
VAL_ 2151481344 FSRACCFrstRsmPrssIO 1 "true" 0 "false" ;
VAL_ 2151481344 FrtRdrBlckdIO 1 "true" 0 "false" ;
VAL_ 2151481344 ShtToPrkBfExtngVehIO 1 "true" 0 "false" ;
VAL_ 2151481344 AutoBrkRlsIO 1 "true" 0 "false" ;
VAL_ 2153381888 VltActRrAccUnavlIO 1 "true" 0 "false" ;
VAL_ 2153381888 PwrLftgtMotStat 0 "Unknown" 1 "Full open" 2 "Closed" 3 "Opening" 4 "Closing" 5 "Stopped" ;
VAL_ 2153381888 GrgPrgMdCmpl 1 "true" 0 "false" ;
VAL_ 2153381888 PwrLftgtInclAngV 1 "Invalid" 0 "Valid" ;
VAL_ 2153381888 RrClsrObstclDtctd 1 "true" 0 "false" ;
VAL_ 2153381888 FnshRrClsrMtnBfrDrvIO 1 "true" 0 "false" ;
VAL_ 2153381888 RrClosOpenSwAct 1 "true" 0 "false" ;
VAL_ 2153381888 RrClosOpenSwActV 1 "Invalid" 0 "Valid" ;
VAL_ 2153381888 RrClsrInMtn 1 "true" 0 "false" ;
VAL_ 2153381888 RrWprInhbRq 1 "true" 0 "false" ;
VAL_ 2153979904 RtPrkLtFld 1 "true" 0 "false" ;
VAL_ 2153979904 RtLwBmFld 1 "true" 0 "false" ;
VAL_ 2153979904 RtDytmRunLmpFld 1 "true" 0 "false" ;
VAL_ 2153979904 RtBrkLtFld 1 "true" 0 "false" ;
VAL_ 2153979904 RRTrnIndLtFld 1 "true" 0 "false" ;
VAL_ 2153979904 RLTrnIndLtFld 1 "true" 0 "false" ;
VAL_ 2153979904 LicPltLtFld 1 "true" 0 "false" ;
VAL_ 2153979904 LftPrkLtFld 1 "true" 0 "false" ;
VAL_ 2153979904 LftLwBmFld 1 "true" 0 "false" ;
VAL_ 2153979904 LftBrkLtFld 1 "true" 0 "false" ;
VAL_ 2153979904 FRTrnIndLtFld 1 "true" 0 "false" ;
VAL_ 2153979904 FLTrnIndLtFld 1 "true" 0 "false" ;
VAL_ 2153979904 CHMSLFld 1 "true" 0 "false" ;
VAL_ 2153979904 LftDytmRunLmpFld 1 "true" 0 "false" ;
VAL_ 2153979904 RvsLtFld 1 "true" 0 "false" ;
VAL_ 2153979904 RFgLtFld 1 "true" 0 "false" ;
VAL_ 2149908480 BrkPedTrvlAchvd 1 "true" 0 "false" ;
VAL_ 2149908480 BrkPedTrvlAchvdV 1 "Invalid" 0 "Valid" ;
VAL_ 2149908480 BrkPdlModTrvlV 1 "Invalid" 0 "Valid" ;
VAL_ 2149908480 BrkPdlModTrvl 1 "true" 0 "false" ;
VAL_ 2154643456 HtrCoreInltClntTmpCalcV 1 "Invalid" 0 "Valid" ;
VAL_ 2154643456 AuxHtrAtv 1 "true" 0 "false" ;
VAL_ 2151186432 CtLghtDet 1 "true" 0 "false" ;
VAL_ 2151186432 AutoHgBmCtrlInOn 1 "true" 0 "false" ;
VAL_ 2151186432 AutoBmSlctStat 2 "High Beam" 1 "Low  Beam" 0 "Disabled" ;
VAL_ 2150498304 OAT_PT_EstV 1 "Invalid" 0 "Valid" ;
VAL_ 2150498304 EngOilPrsV 1 "Invalid" 0 "Valid" ;
VAL_ 2150498304 EngOilTmpV 1 "Invalid" 0 "Valid" ;
VAL_ 2150498304 TrnOilTmpV 1 "Invalid" 0 "Valid" ;
VAL_ 2150498304 EngCltTmpV 1 "Invalid" 0 "Valid" ;
VAL_ 2150498304 EngIntAirTmpV 1 "Invalid" 0 "Valid" ;
VAL_ 2150498304 OAT_PT_EstM 1 "Use Data" 0 "Don't Use Data" ;
VAL_ 2150498304 BarPrsAbsV 1 "Invalid" 0 "Valid" ;
VAL_ 2154840064 CmpsZnNvrSet 1 "true" 0 "false" ;
VAL_ 2154840064 CmpsSatrtd 1 "true" 0 "false" ;
VAL_ 2154840064 CmpsDecZone 15 "Zone 15" 14 "Zone 14" 13 "Zone 13" 12 "Zone 12" 11 "Zone 11" 10 "Zone 10" 9 "Zone 9" 8 "Zone 8" 7 "Zone 7" 6 "Zone 6" 5 "Zone 5" 4 "Zone 4" 3 "Zone 3" 2 "Zone 2" 1 "Zone 1" 0 "Unknown" ;
VAL_ 2154840064 CmpsOctHdingDataSrc 1 "Calculated Value" 0 "Stored Value" ;
VAL_ 2154840064 CmpsOctHding 7 "NW (North West)" 6 "W (West)" 5 "SW (South West)" 4 "S (South)" 3 "SE (South East)" 2 "E (East)" 1 "NE (North East)" 0 "N (North)" ;
VAL_ 2154840064 CmpsModManCalInPrc 1 "true" 0 "false" ;
VAL_ 2154840064 CmpsModFltPrs 1 "true" 0 "false" ;
VAL_ 2151890944 TICR_Ind1 0 "Red" 1 "Green" 2 "Yellow" ;
VAL_ 2151890944 TICR_Ind1Req 0 "Off" 1 "Continuous Indication" 2 "Flashing" 3 "Count" ;
VAL_ 2155896832 FuelAlcoholCompV 1 "Invalid" 0 "Valid" ;
VAL_ 2155896832 FuelAlchlCompAdptnPrg 1 "true" 0 "false" ;
VAL_ 2155896832 FuelMdStat 3 "Alternative Fuel Cut-off Active" 2 "Liquified Petroleum Gas Mode" 1 "Natural Gas Mode" 0 "Gasoline Mode" ;
VAL_ 2155896832 FlLvlTank2PctV 1 "Invalid" 0 "Valid" ;
VAL_ 2155896832 AltFuelPHeatAct 1 "true" 0 "false" ;
VAL_ 2155896832 AltFuelMdReqDndIO 1 "true" 0 "false" ;
VAL_ 2155896832 AltFuelLvlLo 1 "true" 0 "false" ;
VAL_ 2155896832 AltFuelAccWrnngAct 1 "true" 0 "false" ;
VAL_ 2154496000 ShftrUnlkdBrkToShftIO 1 "true" 0 "false" ;
VAL_ 2154496000 ShftrLkdBklPsnStbltIO 1 "true" 0 "false" ;
VAL_ 2154496000 ShftrLkdBklDrvStbltIO 1 "true" 0 "false" ;
VAL_ 2154496000 TargaTopStateV 1 "Invalid" 0 "Valid" ;
VAL_ 2154496000 TargaTopState 0 "Open" 1 "Closed" ;
VAL_ 2154496000 CmpSftTopMotBfrOpTrnkIO 1 "true" 0 "false" ;
VAL_ 2154471424 RrClsrSnwLdIO 1 "true" 0 "false" ;
VAL_ 2154471424 RrClosAjarSwAct 1 "true" 0 "false" ;
VAL_ 2151940096 EstIntHorzDshSrfTmpM 0 "Don't Use Data" 1 "Use Data" ;
VAL_ 2151940096 EstIntRfSrfcTmpV 1 "Invalid" 0 "Valid" ;
VAL_ 2151940096 EstBulkIntAirTmpV 1 "Invalid" 0 "Valid" ;
VAL_ 2151940096 A2ERRAlrmReq 2 "Cancel Alarm" 1 "Set Alarm" 0 "No Action" ;
VAL_ 2154987520 WrlsChrgSysChrgStat 7 "Unused and Reserved 2" 6 "Unused and Reserved 1" 5 "WCS Overtemp Shutdown" 4 "Foreign Object Detected" 0 "WCS Not Present" 1 "Charging Inactive" 2 "Charging Active" 3 "Charging Complete" ;
VAL_ 2154987520 HdStV 1 "Invalid" 0 "Valid" ;
VAL_ 2154987520 HdSt 2 "Open" 1 "Ajar" 0 "Closed" ;
VAL_ 2156281856 LftmEffDtRstRqd 1 "true" 0 "false" ;
VAL_ 2156281856 HTRCsStReq 4 "On Away" 3 "On Home" 2 "On" 1 "Off" 0 "No Action" ;
VAL_ 2156281856 RtBsChrgCmplnTmPrfReq 2 "Latest Possible" 1 "Earliest Possible" 0 "No Action" ;
VAL_ 2156281856 TONPDTR_StTmpOvrAtv 0 "No Action" 1 "False (Inactive)" 2 "True (Active)" 3 "Unused and Reserved" ;
VAL_ 2156281856 TONPDTR_DyOfWk 0 "No Action" 1 "Unknown" 2 "Sunday" 3 "Monday" 4 "Tuesday" 5 "Wednesday" 6 "Thursday" 7 "Friday" 8 "Saturday" ;
VAL_ 2156281856 StTODChrgTmpOvrd 1 "true" 0 "false" ;
VAL_ 2156281856 HVBTBSCSR_SsnStReq 3 "Yearly" 0 "No Action" 1 "Summer" 2 "Winter" ;
VAL_ 2156281856 HVBTBSCSR_SsnSlStReq 0 "No Action" 1 "Selected Season" 2 "Start Season" 3 "End Season" ;
VAL_ 2156281856 HVBTBSCSR_SsnMthStReq 0 "No Action" 1 "January" 2 "February" 3 "Mars" 4 "April" 5 "May" 6 "June" 7 "July" 8 "August" 9 "September" 10 "October" 11 "November" 12 "December" ;
VAL_ 2156281856 HVBTBCRSR_ChRtSlStReq 0 "No Action" 1 "Low Rate" 2 "Medium Rate" 3 "High Rate" ;
VAL_ 2156281856 HVBTBCRSR_ChRtEnblStReq 0 "No Action" 1 "Enabled" 2 "Disabled" ;
VAL_ 2156281856 HVBTBCRSR_ChRtDStReq 0 "No Action" 1 "Sunday" 2 "Monday" 3 "Tuesday" 4 "Wednsday" 5 "Thursday" 6 "Friday" 7 "Saturday" 8 "All Days Same" 9 "Mon - Fri Same" 10 "Sat & Sun Same" ;
VAL_ 2156281856 HVBatTmBsChrgMdReq 0 "No Action" 1 "Charge Now" 2 "Delayed Charge" 3 "Rate Based Charge" ;
VAL_ 2156281856 HVChgSyChgLvlPrfSt 0 "No Action" 1 "No Reduction" 2 "Reduced Current Level 1" 3 "Reduced Current Level 2" 4 "Reduced Current Level 3" ;
VAL_ 2156281856 TODCTmpImdtOvrdReq 2 "Active" 1 "Inactive" 0 "No Action" ;
VAL_ 2156314624 HVChrgSysSplyFltIO 1 "true" 0 "false" ;
VAL_ 2156314624 OffBrdCSFltDtctd 1 "true" 0 "false" ;
VAL_ 2156314624 OBVhCsACChgRqBnVs 1 "true" 0 "false" ;
VAL_ 2156314624 TODCNPDT_DyOfWk 0 "Unknown" 1 "Sunday" 2 "Monday" 3 "Tuesday" 4 "Wednesday" 5 "Thursday" 6 "Friday" 7 "Saturday" ;
VAL_ 2156314624 TODCOpMd 0 "Normal Operation" 1 "Departure Time Temporary Override" 2 "Charge Mode Temporary Override" 3 "Time of Day Faulted" ;
VAL_ 2156314624 TODCDMPTO_TpOvR 11 "Offboard Thermal Conditioning Only" 10 "Offboard Not Active Bulk Done" 9 "Offboard Active Bulk Done" 8 "Offboard Not Active" 7 "Offboard Active" 0 "None" 1 "Override Immediate" 2 "Override Next Plan Depart Time" 3 "Disabled" 4 "Onboard Fault" 5 "Offboard Fault Off Vehicle" 6 "Offboard Fault On Vehicle" ;
VAL_ 2156314624 TODCDMPTO_CmPgR 1 "true" 0 "false" ;
VAL_ 2156314624 HVChrgSysStNot 6 "Utility Override" 0 "Default" 1 "Idle" 2 "Initializing" 3 "Active" 4 "Complete" 5 "Aborted" ;
VAL_ 2156314624 HVChrgAbrtRsn 0 "No Action" 1 "Loss of AC" 2 "Unplug Charge" 3 "Unplug Delay" 4 "Charge Failure" 5 "Cordset Fault" 6 "Cordset Delay" ;
VAL_ 2156314624 HVCSCLPD_UsrIntTyp 0 "User Interface 1" 1 "User Interface 2" ;
VAL_ 2156314624 HVCSCLPD_ChgLvlPfS 0 "No Reduction" 1 "Reduced Current Level 1" 2 "Reduced Current Level 2" 3 "Reduced Current Level 3" ;
VAL_ 2149761024 PsngStPerfMdCsCrStVal 7 "Auto" 6 "Performance Mode 6" 5 "Performance Mode 5" 4 "Performance Mode 4" 3 "Performance Mode 3" 2 "Performance Mode 2" 1 "Performance Mode 1" 0 "No Action" ;
VAL_ 2149761024 PsngStPerfMdCsStAvl 1 "true" 0 "false" ;
VAL_ 2149761024 ElvtdIdlCstCrStVal 0 "No Action" 1 "Off" 2 "On" ;
VAL_ 2149761024 ElvtdIdlCstStAvl 1 "true" 0 "false" ;
VAL_ 2149761024 TCTPIR_DrvNotfn 15 "Indication 15" 14 "Indication 14" 13 "Indication 13" 12 "Indication 12" 11 "Indication 11" 10 "Indication 10" 9 "Indication 9" 8 "Indication 8" 7 "Indication 7" 6 "Indication 6" 5 "Indication 5" 4 "Indication 4" 3 "Indication 3" 2 "Indication 2" 1 "Indication 1" 0 "No Indication" ;
VAL_ 2149761024 TrlrStabAstActIO 1 "true" 0 "false" ;
VAL_ 2149761024 PerfTrcCrnExStngVal 0 "No Action" 1 "Off" 2 "Setting 1" 3 "Setting 2" 4 "Setting 3" 5 "Setting 4" 6 "Setting 5" 7 "Setting 6" 8 "Setting 7" 9 "Setting 8" 10 "Setting 9" 11 "Setting 10" 12 "Setting 11" 13 "Setting 12" 14 "Setting 13" 15 "Setting 14" 16 "Setting 15" ;
VAL_ 2149761024 ActVehAccelV 1 "Invalid" 0 "Valid" ;
VAL_ 2151997440 DrvDrowSysIndRq 0 "No Indication" 1 "Continuous Indication" 2 "Flashing Indication With Chime" 3 "Flashing Indication Without Chime" 4 "Reserved1" 5 "Reserved2" 6 "Reserved3" 7 "Reserved4" ;
VAL_ 2151997440 DrvDrwDetCsCrStVal 0 "No Action" 1 "Off" 2 "On" 3 "Reserved1" 4 "Reserved2" 5 "Reserved3" 6 "Reserved4" 7 "Reserved5" ;
VAL_ 2151997440 DrvDrowDetCstStAvl 1 "true" 0 "false" ;
VAL_ 2151948288 RunBrdOpMdCstStReq 7 "Unused and Reserved 4" 6 "Unused and Reserved 3" 5 "Unused and Reserved 2" 4 "Unused and Reserved 1" 3 "Extended" 2 "On" 1 "Off" 0 "No Action" ;
VAL_ 2151948288 DrvDrowDetCstStRq 0 "No Action" 1 "Off" 2 "On" 3 "Reserved1" 4 "Reserved2" 5 "Reserved3" 6 "Reserved4" 7 "Reserved5" ;
VAL_ 2152128512 PSPMCA_PsngStPrfMd6Avl 1 "true" 0 "false" ;
VAL_ 2152128512 PSPMCA_PsngStPrfMd5Avl 1 "true" 0 "false" ;
VAL_ 2152128512 PSPMCA_PsngStPrfMd4Avl 1 "true" 0 "false" ;
VAL_ 2152128512 PSPMCA_PsngStPrfMd3Avl 1 "true" 0 "false" ;
VAL_ 2152128512 PSPMCA_PsngStPrfMd2Avl 1 "true" 0 "false" ;
VAL_ 2152128512 PSPMCA_PsngStPrfMd1Avl 1 "true" 0 "false" ;
VAL_ 2152128512 DSPMCA_DrvrStPrfMd6Avl 1 "true" 0 "false" ;
VAL_ 2152128512 DSPMCA_DrvrStPrfMd5Avl 1 "true" 0 "false" ;
VAL_ 2152128512 DSPMCA_DrvrStPrfMd4Avl 1 "true" 0 "false" ;
VAL_ 2152128512 DSPMCA_DrvrStPrfMd3Avl 1 "true" 0 "false" ;
VAL_ 2152128512 DSPMCA_DrvrStPrfMd2Avl 1 "true" 0 "false" ;
VAL_ 2152128512 DSPMCA_DrvrStPrfMd1Avl 1 "true" 0 "false" ;
VAL_ 2152128512 DSPMCA_DrvStyPrfMd7Avl 1 "true" 0 "false" ;
VAL_ 2152128512 DSPMCA_DrvStyPrfMd6Avl 1 "true" 0 "false" ;
VAL_ 2152128512 DSPMCA_DrvStyPrfMd5Avl 1 "true" 0 "false" ;
VAL_ 2152128512 DSPMCA_DrvStyPrfMd4Avl 1 "true" 0 "false" ;
VAL_ 2152128512 DSPMCA_DrvStyPrfMd3Avl 1 "true" 0 "false" ;
VAL_ 2152128512 DSPMCA_DrvStyPrfMd2Avl 1 "true" 0 "false" ;
VAL_ 2152128512 DSPMCA_DrvStyPrfMd1Avl 1 "true" 0 "false" ;
VAL_ 2152128512 ACCPMCA_ACCPrfMd6Avl 1 "true" 0 "false" ;
VAL_ 2152128512 ACCPMCA_ACCPrfMd5Avl 1 "true" 0 "false" ;
VAL_ 2152128512 ACCPMCA_ACCPrfMd4Avl 1 "true" 0 "false" ;
VAL_ 2152128512 ACCPMCA_ACCPrfMd3Avl 1 "true" 0 "false" ;
VAL_ 2152128512 ACCPMCA_ACCPrfMd2Avl 1 "true" 0 "false" ;
VAL_ 2152128512 ACCPMCA_ACCPrfMd1Avl 1 "true" 0 "false" ;
VAL_ 2152112128 PMVSS_Disps 7 "Visualization Type 7" 6 "Visualization Type 6" 5 "Visualization Type 5" 4 "Visualization Type 4" 3 "Visualization Type 3" 2 "Visualization Type 2" 1 "Visualization Type 1" 0 "No Action" ;
VAL_ 2152112128 PMVSS_Exhst 7 "Visualization Type 7" 6 "Visualization Type 6" 5 "Visualization Type 5" 4 "Visualization Type 4" 3 "Visualization Type 3" 2 "Visualization Type 2" 1 "Visualization Type 1" 0 "No Action" ;
VAL_ 2152112128 PMVSS_PsngrSeat 7 "Visualization Type 7" 6 "Visualization Type 6" 5 "Visualization Type 5" 4 "Visualization Type 4" 3 "Visualization Type 3" 2 "Visualization Type 2" 1 "Visualization Type 1" 0 "No Action" ;
VAL_ 2152112128 PMVSS_DrvrSeat 7 "Visualization Type 7" 6 "Visualization Type 6" 5 "Visualization Type 5" 4 "Visualization Type 4" 3 "Visualization Type 3" 2 "Visualization Type 2" 1 "Visualization Type 1" 0 "No Action" ;
VAL_ 2152112128 PMVSS_AdptCrsCnt 7 "Visualization Type 7" 6 "Visualization Type 6" 5 "Visualization Type 5" 4 "Visualization Type 4" 3 "Visualization Type 3" 2 "Visualization Type 2" 1 "Visualization Type 1" 0 "No Action" ;
VAL_ 2152112128 PMVSS_Drvln 7 "Visualization Type 7" 6 "Visualization Type 6" 5 "Visualization Type 5" 4 "Visualization Type 4" 3 "Visualization Type 3" 2 "Visualization Type 2" 1 "Visualization Type 1" 0 "No Action" ;
VAL_ 2152112128 PMVSS_Susp 7 "Visualization Type 7" 6 "Visualization Type 6" 5 "Visualization Type 5" 4 "Visualization Type 4" 3 "Visualization Type 3" 2 "Visualization Type 2" 1 "Visualization Type 1" 0 "No Action" ;
VAL_ 2152112128 PMVSS_Strng 7 "Visualization Type 7" 6 "Visualization Type 6" 5 "Visualization Type 5" 4 "Visualization Type 4" 3 "Visualization Type 3" 2 "Visualization Type 2" 1 "Visualization Type 1" 0 "No Action" ;
VAL_ 2152112128 PMVSS_Trans 7 "Visualization Type 7" 6 "Visualization Type 6" 5 "Visualization Type 5" 4 "Visualization Type 4" 3 "Visualization Type 3" 2 "Visualization Type 2" 1 "Visualization Type 1" 0 "No Action" ;
VAL_ 2152112128 PMVSS_Eng 7 "Visualization Type 7" 6 "Visualization Type 6" 5 "Visualization Type 5" 4 "Visualization Type 4" 3 "Visualization Type 3" 2 "Visualization Type 2" 1 "Visualization Type 1" 0 "No Action" ;
VAL_ 2152112128 PMVSS_Snd 7 "Visualization Type 7" 6 "Visualization Type 6" 5 "Visualization Type 5" 4 "Visualization Type 4" 3 "Visualization Type 3" 2 "Visualization Type 2" 1 "Visualization Type 1" 0 "No Action" ;
VAL_ 2152112128 PerfMdMainMenuType 7 "Reserved" 6 "Reserved" 5 "Reserved" 4 "Reserved" 3 "Main Menu Type 3" 2 "Main Menu Type 2" 1 "Main Menu Type 1" 0 "No Action" ;
VAL_ 2154299392 CrShrngVehChlngReq 1 "Request New  Challenge" 0 "No Action" ;
SIG_GROUP_ 2156298240 HVBatStrTmLwPwrChrg 1 : HVBSTLPC_MntOfHr HVBSTLPC_HrOfDy HVBSTLPC_DyOfWk;
SIG_GROUP_ 2156298240 HVBatStrTmHghPwrChrg 1 : HVBSTHPC_MntOfHr HVBSTHPC_HrOfDy HVBSTHPC_DyOfWk;
SIG_GROUP_ 2156298240 HVBatCmpltTmLwPwrChrg 1 : HVBCTLPC_MntOfHr HVBCTLPC_HrOfDy HVBCTLPC_DyOfWk;
SIG_GROUP_ 2156298240 HVBatCmpltTmHghPwrChrg 1 : HVBCTHPC_MntOfHr HVBCTHPC_HrOfDy HVBCTHPC_DyOfWk;
SIG_GROUP_ 2156298240 HVChrgSysDpTmExdSt 1 : HVCSDTES_NPDTIO HVCSDTES_LoPwrCIO HVCSDTES_HiPwrCIO;
SIG_GROUP_ 2156331008 EngyUsgScrDsp 1 : EUSD_MsrmntUnit EUSD_MsrmntVal;
SIG_GROUP_ 2158116864 HVBatTmBsRtChrgRsp 1 : HVBTBRCR_RtCHSlctTblRwStat HVBTBRCR_RtChSlctStat HVBTBRCR_RtChSlRtStat HVBTBRCR_RtChSsnStat HVBTBRCR_RtChMHRsp HVBTBRCR_RtChHRsp HVBTBRCR_RtChDStat;
SIG_GROUP_ 2158116864 HVBatTmBsDelChrgRsp 1 : HVBTBDCRS_DlChSlctStat HVBTBDCRS_DlChSsnStat HVBTBDCRS_DlChMHRsp HVBTBDCRS_DlChHRsp HVBTBDCRS_DlChDStat;
SIG_GROUP_ 2158149632 EngyCnsHsGrphCnfgDt 1 : ECHGCD_XAxTkMrkInterv ECHGCD_YAxMaxVal ECHGCD_MeasUt;
SIG_GROUP_ 2158149632 HVBatTmBsSsnChRsp 1 : HVBTBSCR_SsnDyStat HVBTBSCR_SsnStat HVBTBSCR_SsnSlctStat HVBTBSCR_SsnMthStat;
SIG_GROUP_ 2158149632 HVBatTmBsChrgRtRsp 1 : HVBTBCRS_ChRtDStat HVBTBCRS_ChRtSlctStat HVBTBCRS_ChRtEnblStat;
SIG_GROUP_ 2149908480 BrkPedInitTrvlAchvdStat 1 : BrkPedTrvlAchvd BrkPedTrvlAchvdV;
SIG_GROUP_ 2151890944 TlmtcsIndCntrlReq 1 : TICR_Ind1FlshRtOn TICR_Ind1FlshRtOff TICR_Ind1Cnt TICR_Ind1 TICR_Ind1Req;
SIG_GROUP_ 2151940096 Alrm2ExtRngReq 1 : A2ERRAlrmTime A2ERRAlrmReq;
SIG_GROUP_ 2156281856 TmpOvdNxtPlnDptTmRq 1 : TONPDTR_StTmpOvrAtv TONPDTR_MntOfHr TONPDTR_HrOfDy TONPDTR_DyOfWk;
SIG_GROUP_ 2156281856 HVBatTmBsSsnChStReq 1 : HVBTBSCSR_SsnStReq HVBTBSCSR_SsnSlStReq HVBTBSCSR_SsnMthStReq HVBTBSCSR_SsnDayStReq;
SIG_GROUP_ 2156281856 HVBatTmBsChrgRtStReq 1 : HVBTBCRSR_ChRtSlStReq HVBTBCRSR_ChRtEnblStReq HVBTBCRSR_ChRtDStReq;
SIG_GROUP_ 2156314624 TODCNxtPlnndDprtrTm 1 : TODCNPDT_Min TODCNPDT_Hr TODCNPDT_DyOfWk;
SIG_GROUP_ 2156314624 TODCDspMnPgTmpOr 1 : TODCDMPTO_TpOvR TODCDMPTO_CmPgR;
SIG_GROUP_ 2156314624 HVChgSyChgLvlPrfDt 1 : HVCSCLPD_UsrIntTyp HVCSCLPD_RdCrntLv3 HVCSCLPD_RdCrntLv2 HVCSCLPD_RdCrntLv1 HVCSCLPD_NrmChrgC HVCSCLPD_ChgLvlPfS;
SIG_GROUP_ 2149761024 TrnsCltchThrmlProtIndR 1 : TCTPIR_TnsEsClCDwT TCTPIR_TnsEsClTmpD TCTPIR_DrvNotfn;
SIG_GROUP_ 2152128512 PsngStPerfMdCustAvl 1 : PSPMCA_PsngStPrfMd6Avl PSPMCA_PsngStPrfMd5Avl PSPMCA_PsngStPrfMd4Avl PSPMCA_PsngStPrfMd3Avl PSPMCA_PsngStPrfMd2Avl PSPMCA_PsngStPrfMd1Avl;
SIG_GROUP_ 2152128512 DrvrStPerfMdCustAvl 1 : DSPMCA_DrvrStPrfMd6Avl DSPMCA_DrvrStPrfMd5Avl DSPMCA_DrvrStPrfMd4Avl DSPMCA_DrvrStPrfMd3Avl DSPMCA_DrvrStPrfMd2Avl DSPMCA_DrvrStPrfMd1Avl;
SIG_GROUP_ 2152128512 DrvStyPerfMdCustAvl 1 : DSPMCA_DrvStyPrfMd7Avl DSPMCA_DrvStyPrfMd6Avl DSPMCA_DrvStyPrfMd5Avl DSPMCA_DrvStyPrfMd4Avl DSPMCA_DrvStyPrfMd3Avl DSPMCA_DrvStyPrfMd2Avl DSPMCA_DrvStyPrfMd1Avl;
SIG_GROUP_ 2152128512 ACCPerfMdCustAvl 1 : ACCPMCA_ACCPrfMd6Avl ACCPMCA_ACCPrfMd5Avl ACCPMCA_ACCPrfMd4Avl ACCPMCA_ACCPrfMd3Avl ACCPMCA_ACCPrfMd2Avl ACCPMCA_ACCPrfMd1Avl;
SIG_GROUP_ 2152112128 PerfMdVislztnScrnStat 1 : PMVSS_Disps PMVSS_Exhst PMVSS_PsngrSeat PMVSS_DrvrSeat PMVSS_AdptCrsCnt PMVSS_Drvln PMVSS_Susp PMVSS_Strng PMVSS_Trans PMVSS_Eng PMVSS_Snd;
